VERSION "HNNBNNNYNNNNNNNNNNNNNNNNNNNNNNNNNNNNNNNNNN/4/%%%/4/'%**4NNN///"

NS_ :

BS_ :

BU_:  Airbag BAP_Tester ICAS1_Gateway ICAS1_KommunikationsServer LE1 LE2 Motor_BEV Schaltbetaetigung

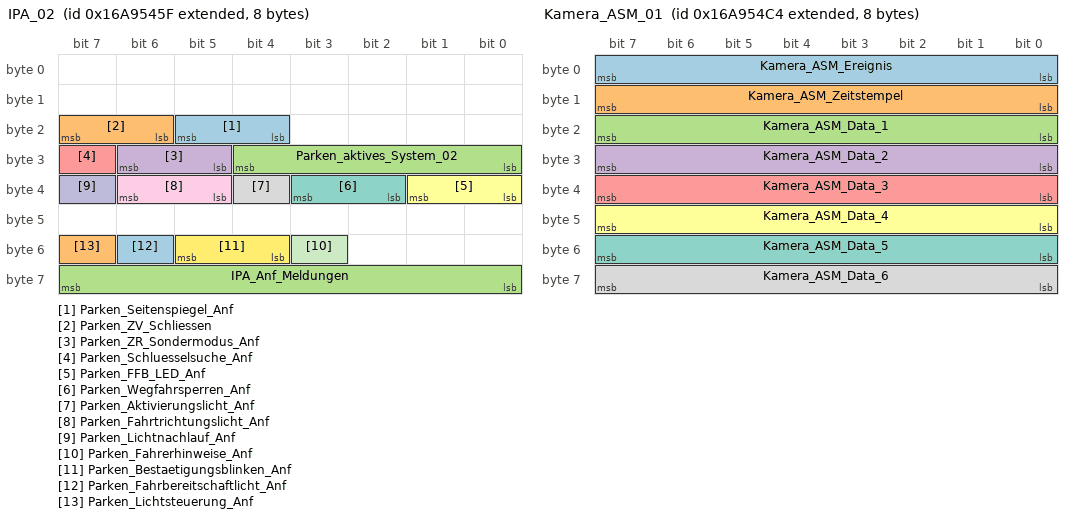
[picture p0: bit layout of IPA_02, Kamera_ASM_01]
BO_ 2527679583 IPA_02: 8 ICAS1_Gateway
 SG_ Parken_Seitenspiegel_Anf  : 20|2@1+ (1.000000,0.000000) [0.000000|3.000000] "" Vector__XXX
 SG_ Parken_ZV_Schliessen  : 22|2@1+ (1.000000,0.000000) [0.000000|3.000000] "" Vector__XXX
 SG_ Parken_aktives_System_02  : 24|5@1+ (1.000000,0.000000) [0.000000|31.000000] "" Vector__XXX
 SG_ Parken_ZR_Sondermodus_Anf  : 29|2@1+ (1.000000,0.000000) [0.000000|3.000000] "" Vector__XXX
 SG_ Parken_Schluesselsuche_Anf  : 31|1@1+ (1.000000,0.000000) [0.000000|1.000000] "" Vector__XXX
 SG_ Parken_FFB_LED_Anf  : 32|2@1+ (1.000000,0.000000) [0.000000|3.000000] "" Vector__XXX
 SG_ Parken_Wegfahrsperren_Anf  : 34|2@1+ (1.000000,0.000000) [0.000000|3.000000] "" LE1 LE2
 SG_ Parken_Aktivierungslicht_Anf  : 36|1@1+ (1.000000,0.000000) [0.000000|1.000000] "" Vector__XXX
 SG_ Parken_Fahrtrichtungslicht_Anf  : 37|2@1+ (1.000000,0.000000) [0.000000|3.000000] "" Vector__XXX
 SG_ Parken_Lichtnachlauf_Anf  : 39|1@1+ (1.000000,0.000000) [0.000000|1.000000] "" Vector__XXX
 SG_ Parken_Fahrerhinweise_Anf  : 51|1@1+ (1.000000,0.000000) [0.000000|1.000000] "" Vector__XXX
 SG_ Parken_Bestaetigungsblinken_Anf  : 52|2@1+ (1.000000,0.000000) [0.000000|3.000000] "" Vector__XXX
 SG_ Parken_Fahrbereitschaftlicht_Anf  : 54|1@1+ (1.000000,0.000000) [0.000000|1.000000] "" Vector__XXX
 SG_ Parken_Lichtsteuerung_Anf  : 55|1@1+ (1.000000,0.000000) [0.000000|1.000000] "" Vector__XXX
 SG_ IPA_Anf_Meldungen  : 56|8@1+ (1.000000,0.000000) [0.000000|255.000000] "" Vector__XXX

BO_ 1813 ISO_Airbag_01_Req: 8 ICAS1_Gateway
 SG_ ISO_Airbag_01_Req_Data  : 0|64@1+ (1.000000,0.000000) [0.000000|18446744073709551616.000000] "" Airbag

BO_ 1919 ISO_Airbag_01_Resp: 8 Airbag
 SG_ ISO_Airbag_01_Resp_Data  : 0|64@1+ (1.000000,0.000000) [0.000000|18446744073709551616.000000] "" ICAS1_Gateway

BO_ 1792 ISO_Funktionaler_Req_All: 8 ICAS1_Gateway
 SG_ ISO_ALL_01_Req_Data  : 0|64@1+ (1.000000,0.000000) [0.000000|18446744073709551616.000000] "" Airbag LE1 LE2 Motor_BEV

BO_ 2621440021 ISOx_Airbag_01_Req_FD: 64 ICAS1_Gateway
 SG_ ISOx_Airbag_01_Req_FD_Data  : 0|512@1+ (1.000000,0.000000) [0.000000|13407807929942597099574024998205846127479365820592393377723561443721764030073546976801874298166903427690031858186486050853753882811946569946433649006084096.000000] "" Airbag

BO_ 2621571093 ISOx_Airbag_01_Resp_FD: 64 Airbag
 SG_ ISOx_Airbag_01_Resp_FD_Data  : 0|512@1+ (1.000000,0.000000) [0.000000|13407807929942597099574024998205846127479365820592393377723561443721764030073546976801874298166903427690031858186486050853753882811946569946433649006084096.000000] "" ICAS1_Gateway

BO_ 2549874812 ISOx_EMotor_01_Req: 8 ICAS1_Gateway
 SG_ ISO_EMotor_01_Req_Data  : 0|64@1+ (1.000000,0.000000) [0.000000|18446744073709551616.000000] "" LE1

BO_ 2621440124 ISOx_EMotor_01_Req_FD: 64 ICAS1_Gateway
 SG_ ISOx_EMotor_01_Req_FD_Data  : 0|512@1+ (1.000000,0.000000) [0.000000|13407807929942597099574024998205846127479365820592393377723561443721764030073546976801874298166903427690031858186486050853753882811946569946433649006084096.000000] "" LE1

BO_ 2550005884 ISOx_EMotor_01_Resp: 8 LE1
 SG_ ISO_EMotor_01_Resp_Data  : 0|64@1+ (1.000000,0.000000) [0.000000|18446744073709551616.000000] "" ICAS1_Gateway

BO_ 2621571196 ISOx_EMotor_01_Resp_FD: 64 LE1
 SG_ ISOx_EMotor_01_Resp_FD_Data  : 0|512@1+ (1.000000,0.000000) [0.000000|13407807929942597099574024998205846127479365820592393377723561443721764030073546976801874298166903427690031858186486050853753882811946569946433649006084096.000000] "" ICAS1_Gateway

BO_ 2549874872 ISOx_EMotor_02_Req: 8 ICAS1_Gateway
 SG_ ISO_EMotor_02_Req_Data  : 0|64@1+ (1.000000,0.000000) [0.000000|18446744073709551616.000000] "" LE2

BO_ 2621440184 ISOx_EMotor_02_Req_FD: 64 ICAS1_Gateway
 SG_ ISOx_EMotor_02_Req_FD_Data  : 0|512@1+ (1.000000,0.000000) [0.000000|13407807929942597099574024998205846127479365820592393377723561443721764030073546976801874298166903427690031858186486050853753882811946569946433649006084096.000000] "" LE2

BO_ 2550005944 ISOx_EMotor_02_Resp: 8 LE2
 SG_ ISO_EMotor_02_Resp_Data  : 0|64@1+ (1.000000,0.000000) [0.000000|18446744073709551616.000000] "" ICAS1_Gateway

BO_ 2621571256 ISOx_EMotor_02_Resp_FD: 64 LE2
 SG_ ISOx_EMotor_02_Resp_FD_Data  : 0|512@1+ (1.000000,0.000000) [0.000000|13407807929942597099574024998205846127479365820592393377723561443721764030073546976801874298166903427690031858186486050853753882811946569946433649006084096.000000] "" ICAS1_Gateway

BO_ 2621505536 ISOx_Funkt_Req_All_FD: 64 ICAS1_Gateway
 SG_ ISOx_Funkt_Req_All_FD_Data  : 0|512@1+ (1.000000,0.000000) [0.000000|13407807929942597099574024998205846127479365820592393377723561443721764030073546976801874298166903427690031858186486050853753882811946569946433649006084096.000000] "" Airbag LE1 LE2 Motor_BEV

BO_ 2549874806 ISOx_MO_01_Req: 8 ICAS1_Gateway
 SG_ ISOx_MO_01_Req_Data  : 0|64@1+ (1.000000,0.000000) [0.000000|18446744073709551616.000000] "" Motor_BEV

BO_ 2621440118 ISOx_MO_01_Req_FD: 64 ICAS1_Gateway
 SG_ ISOx_MO_01_Req_FD_Data  : 0|512@1+ (1.000000,0.000000) [0.000000|13407807929942597099574024998205846127479365820592393377723561443721764030073546976801874298166903427690031858186486050853753882811946569946433649006084096.000000] "" Motor_BEV

BO_ 2550005878 ISOx_MO_01_Resp: 8 Motor_BEV
 SG_ ISOx_MO_01_Resp_Data  : 0|64@1+ (1.000000,0.000000) [0.000000|18446744073709551616.000000] "" ICAS1_Gateway

BO_ 2621571190 ISOx_MO_01_Resp_FD: 64 Motor_BEV
 SG_ ISOx_MO_01_Resp_FD_Data  : 0|512@1+ (1.000000,0.000000) [0.000000|13407807929942597099574024998205846127479365820592393377723561443721764030073546976801874298166903427690031858186486050853753882811946569946433649006084096.000000] "" ICAS1_Gateway

BO_ 2527679684 Kamera_ASM_01: 8 ICAS1_Gateway
 SG_ Kamera_ASM_Ereignis  : 0|8@1+ (1.000000,0.000000) [1.000000|254.000000] "" Airbag
 SG_ Kamera_ASM_Zeitstempel  : 8|8@1+ (0.080000,0.000000) [0.000000|20.320000] "Unit_Secon" Airbag
 SG_ Kamera_ASM_Data_1  : 16|8@1+ (1.000000,0.000000) [0.000000|255.000000] "" Airbag
 SG_ Kamera_ASM_Data_2  : 24|8@1+ (1.000000,0.000000) [0.000000|255.000000] "" Airbag
 SG_ Kamera_ASM_Data_3  : 32|8@1+ (1.000000,0.000000) [0.000000|255.000000] "" Airbag
 SG_ Kamera_ASM_Data_4  : 40|8@1+ (1.000000,0.000000) [0.000000|255.000000] "" Airbag
 SG_ Kamera_ASM_Data_5  : 48|8@1+ (1.000000,0.000000) [0.000000|255.000000] "" Airbag
 SG_ Kamera_ASM_Data_6  : 56|8@1+ (1.000000,0.000000) [0.000000|255.000000] "" Airbag

BO_ 960 Klemmen_Status_01: 4 ICAS1_Gateway
 SG_ Klemmen_Status_01_CRC  : 0|8@1+ (1.000000,0.000000) [0.000000|255.000000] "" Motor_BEV
 SG_ Klemmen_Status_01_BZ  : 8|4@1+ (1.000000,0.000000) [0.000000|15.000000] "" Motor_BEV
 SG_ RSt_Fahrerhinweise  : 12|4@1+ (1.000000,0.000000) [0.000000|15.000000] "" Vector__XXX
 SG_ ZAS_Kl_S  : 16|1@1+ (1.000000,0.000000) [0.000000|1.000000] "" Vector__XXX
 SG_ ZAS_Kl_15  : 17|1@1+ (1.000000,0.000000) [0.000000|1.000000] "" Airbag LE1 LE2 Motor_BEV Schaltbetaetigung
 SG_ ZAS_Kl_X  : 18|1@1+ (1.000000,0.000000) [0.000000|1.000000] "" Vector__XXX
 SG_ ZAS_Kl_50_Startanforderung  : 19|1@1+ (1.000000,0.000000) [0.000000|1.000000] "" Motor_BEV
 SG_ BCM_Remotestart_Betrieb  : 20|1@1+ (1.000000,0.000000) [0.000000|1.000000] "" Vector__XXX
 SG_ ZAS_Kl_Infotainment  : 21|1@1+ (1.000000,0.000000) [0.000000|1.000000] "" Vector__XXX
 SG_ BCM_Remotestart_KL15_Anf  : 22|1@1+ (1.000000,0.000000) [0.000000|1.000000] "" Vector__XXX
 SG_ BCM_Remotestart_MO_Start  : 23|1@1+ (1.000000,0.000000) [0.000000|1.000000] "" Vector__XXX
 SG_ KST_Warn_P1_ZST_def  : 24|1@1+ (1.000000,0.000000) [0.000000|1.000000] "" Vector__XXX
 SG_ KST_Warn_P2_ZST_def  : 25|1@1+ (1.000000,0.000000) [0.000000|1.000000] "" Vector__XXX
 SG_ KST_Fahrerhinweis_1  : 26|1@1+ (1.000000,0.000000) [0.000000|1.000000] "" Vector__XXX
 SG_ KST_Fahrerhinweis_2  : 27|1@1+ (1.000000,0.000000) [0.000000|1.000000] "" Vector__XXX
 SG_ BCM_Ausparken_Betrieb  : 28|1@1+ (1.000000,0.000000) [0.000000|1.000000] "" Vector__XXX
 SG_ KST_Fahrerhinweis_4  : 29|1@1+ (1.000000,0.000000) [0.000000|1.000000] "" Vector__XXX
 SG_ KST_Fahrerhinweis_5  : 30|1@1+ (1.000000,0.000000) [0.000000|1.000000] "" Vector__XXX
 SG_ KST_Fahrerhinweis_6  : 31|1@1+ (1.000000,0.000000) [0.000000|1.000000] "" Vector__XXX

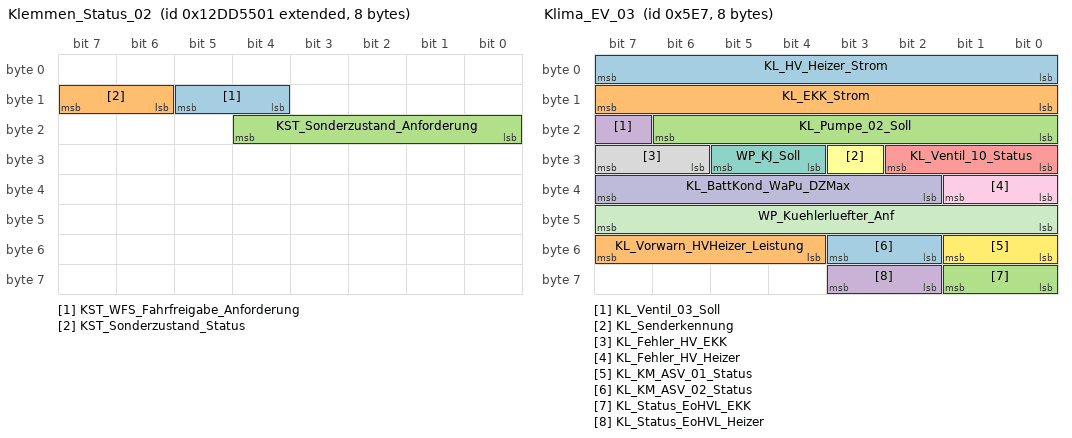
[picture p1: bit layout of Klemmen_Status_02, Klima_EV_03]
BO_ 2463978753 Klemmen_Status_02: 8 ICAS1_Gateway
 SG_ KST_WFS_Fahrfreigabe_Anforderung  : 12|2@1+ (1.000000,0.000000) [0.000000|3.000000] "" LE1 LE2
 SG_ KST_Sonderzustand_Status  : 14|2@1+ (1.000000,0.000000) [0.000000|3.000000] "" LE1 LE2
 SG_ KST_Sonderzustand_Anforderung  : 16|5@1+ (1.000000,0.000000) [0.000000|31.000000] "" LE1 LE2

BO_ 1420 Klemmen_Steuerung_01: 8 ICAS1_Gateway
 SG_ Klemmen_Steuerung_01_CRC  : 0|8@1+ (1.000000,0.000000) [0.000000|255.000000] "" Vector__XXX
 SG_ Klemmen_Steuerung_01_BZ  : 8|4@1+ (1.000000,0.000000) [0.000000|15.000000] "" Vector__XXX
 SG_ KST_Anf_Klemme_15  : 12|1@1+ (1.000000,0.000000) [0.000000|1.000000] "" Vector__XXX
 SG_ KST_Anf_Klemme_50  : 13|1@1+ (1.000000,0.000000) [0.000000|1.000000] "" Motor_BEV
 SG_ KST_Anf_Klemme_S  : 14|1@1+ (1.000000,0.000000) [0.000000|1.000000] "" Vector__XXX
 SG_ KST_Txt_Werkstatt  : 15|1@1+ (1.000000,0.000000) [0.000000|1.000000] "" Vector__XXX
 SG_ KST_Txt_P_Gang  : 16|1@1+ (1.000000,0.000000) [0.000000|1.000000] "" Vector__XXX
 SG_ KST_Txt_Panikabschaltung  : 17|1@1+ (1.000000,0.000000) [0.000000|1.000000] "" Vector__XXX
 SG_ KST_Anf_Klemmenfreigabe_ELV  : 18|1@1+ (1.000000,0.000000) [0.000000|1.000000] "" Vector__XXX
 SG_ KST_Txt_Komfortabschaltung  : 19|1@1+ (1.000000,0.000000) [0.000000|1.000000] "" Vector__XXX
 SG_ KST_ZAT_betaetigt  : 20|1@1+ (1.000000,0.000000) [0.000000|1.000000] "" Vector__XXX
 SG_ KST_Unterdr_Zuendungsmeldung  : 21|1@1+ (1.000000,0.000000) [0.000000|1.000000] "" Vector__XXX
 SG_ KST_aut_Abschaltung_Zuendung  : 22|1@1+ (1.000000,0.000000) [0.000000|1.000000] "" Vector__XXX
 SG_ KST_Anf_Klemmenfreigabe_WFS  : 23|1@1+ (1.000000,0.000000) [0.000000|1.000000] "" Vector__XXX
 SG_ KST_Anf_ZV_Verriegelung  : 24|1@1+ (1.000000,0.000000) [0.000000|1.000000] "" Vector__XXX
 SG_ Relais_VoKo_angesteuert  : 25|1@1+ (1.000000,0.000000) [0.000000|1.000000] "" Vector__XXX
 SG_ RSt_Anforderung_HMS  : 26|3@1+ (1.000000,0.000000) [0.000000|7.000000] "" Vector__XXX
 SG_ KST_Zuendungswarnung  : 29|2@1+ (1.000000,0.000000) [0.000000|3.000000] "" Vector__XXX
 SG_ KST_Fahrer_Info_Text  : 31|3@1+ (1.000000,0.000000) [0.000000|7.000000] "" Vector__XXX

BO_ 949 Klima_11: 8 ICAS1_Gateway
 SG_ KL_Drehz_Anh  : 0|1@1+ (1.000000,0.000000) [0.000000|1.000000] "" Vector__XXX
 SG_ KL_Vorwarn_Komp_ein  : 1|1@1+ (1.000000,0.000000) [0.000000|1.000000] "" Vector__XXX
 SG_ KL_AC_Schalter  : 2|1@1+ (1.000000,0.000000) [0.000000|1.000000] "" Vector__XXX
 SG_ KL_Komp_Moment_alt  : 3|1@1+ (1.000000,0.000000) [0.000000|1.000000] "" Vector__XXX
 SG_ KL_Vorwarn_Zuheizer_ein  : 6|1@1+ (1.000000,0.000000) [0.000000|1.000000] "" Vector__XXX
 SG_ KL_Zustand  : 7|1@1+ (1.000000,0.000000) [0.000000|1.000000] "" Vector__XXX
 SG_ KL_Kompressorkupplung_linear  : 8|8@1+ (20.000000,0.000000) [0.000000|4000.000000] "Unit_MilliAmper" Vector__XXX
 SG_ KL_Charisma_FahrPr  : 16|4@1+ (1.000000,0.000000) [0.000000|15.000000] "" Vector__XXX
 SG_ KL_Charisma_Status  : 20|2@1+ (1.000000,0.000000) [0.000000|3.000000] "" Vector__XXX
 SG_ KL_nachtr_Stopp_Anf  : 22|1@1+ (1.000000,0.000000) [0.000000|1.000000] "" Vector__XXX
 SG_ KL_T_Charge  : 23|1@1+ (1.000000,0.000000) [0.000000|1.000000] "" Vector__XXX
 SG_ KL_Last_Kompr  : 24|8@1+ (0.250000,0.000000) [0.000000|63.500000] "Unit_NewtoMeter" Vector__XXX
 SG_ KL_Spannungs_Anf  : 32|2@1+ (1.000000,0.000000) [0.000000|3.000000] "" Vector__XXX
 SG_ KL_Thermomanagement  : 34|2@1+ (1.000000,0.000000) [0.000000|3.000000] "" Motor_BEV
 SG_ KL_StartStopp_Info  : 36|2@1+ (1.000000,0.000000) [0.000000|3.000000] "" Vector__XXX
 SG_ KL_Freilauf_Info  : 38|2@1+ (1.000000,0.000000) [0.000000|3.000000] "" Vector__XXX
 SG_ KL_Anf_KL  : 40|8@1+ (0.400000,0.000000) [0.000000|101.600000] "Unit_PerCent" Motor_BEV
 SG_ KL_el_Zuheizer_Stufe  : 48|3@1+ (1.000000,0.000000) [0.000000|7.000000] "" Vector__XXX
 SG_ KL_Ausstattung_Klima  : 51|3@1+ (1.000000,0.000000) [0.000000|7.000000] "" Vector__XXX
 SG_ KL_Variante_Standheizung  : 54|2@1+ (1.000000,0.000000) [0.000000|3.000000] "" Vector__XXX
 SG_ KL_Anf_KV  : 57|7@1+ (1.000000,0.000000) [0.000000|100.000000] "Unit_PerCent" Motor_BEV

BO_ 1511 Klima_EV_03: 8 ICAS1_Gateway
 SG_ KL_HV_Heizer_Strom  : 0|8@1+ (0.250000,0.000000) [0.000000|63.500000] "Unit_Amper" Motor_BEV
 SG_ KL_EKK_Strom  : 8|8@1+ (0.250000,0.000000) [0.000000|63.500000] "Unit_Amper" Motor_BEV
 SG_ KL_Pumpe_02_Soll  : 16|7@1+ (1.000000,0.000000) [0.000000|100.000000] "Unit_PerCent" Motor_BEV
 SG_ KL_Ventil_03_Soll  : 23|1@1+ (1.000000,0.000000) [0.000000|1.000000] "" Vector__XXX
 SG_ KL_Ventil_10_Status  : 24|3@1+ (1.000000,0.000000) [0.000000|7.000000] "" Vector__XXX
 SG_ KL_Senderkennung  : 27|1@1+ (1.000000,0.000000) [0.000000|1.000000] "" Vector__XXX
 SG_ WP_KJ_Soll  : 28|2@1+ (1.000000,0.000000) [0.000000|3.000000] "" Vector__XXX
 SG_ KL_Fehler_HV_EKK  : 30|2@1+ (1.000000,0.000000) [0.000000|3.000000] "" Vector__XXX
 SG_ KL_Fehler_HV_Heizer  : 32|2@1+ (1.000000,0.000000) [0.000000|3.000000] "" Vector__XXX
 SG_ KL_BattKond_WaPu_DZMax  : 34|6@1+ (2.000000,0.000000) [0.000000|100.000000] "Unit_PerCent" Vector__XXX
 SG_ WP_Kuehlerluefter_Anf  : 40|8@1+ (0.400000,0.000000) [0.000000|101.600000] "Unit_PerCent" Vector__XXX
 SG_ KL_KM_ASV_01_Status  : 48|2@1+ (1.000000,0.000000) [0.000000|3.000000] "" Vector__XXX
 SG_ KL_KM_ASV_02_Status  : 50|2@1+ (1.000000,0.000000) [0.000000|3.000000] "" Vector__XXX
 SG_ KL_Vorwarn_HVHeizer_Leistung  : 52|4@1+ (1.000000,0.000000) [0.000000|15.000000] "" Vector__XXX
 SG_ KL_Status_EoHVL_EKK  : 56|2@1+ (1.000000,0.000000) [0.000000|3.000000] "" Motor_BEV
 SG_ KL_Status_EoHVL_Heizer  : 58|2@1+ (1.000000,0.000000) [0.000000|3.000000] "" Motor_BEV

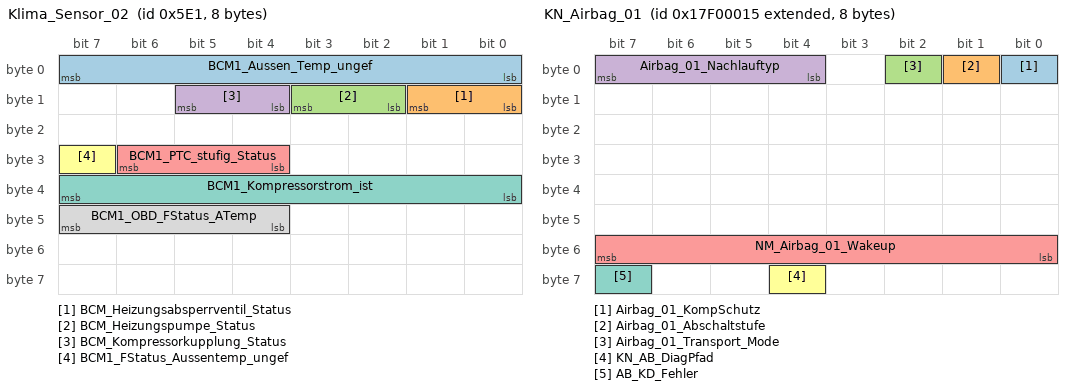
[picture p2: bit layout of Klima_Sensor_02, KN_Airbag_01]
BO_ 1505 Klima_Sensor_02: 8 ICAS1_Gateway
 SG_ BCM1_Aussen_Temp_ungef  : 0|8@1+ (0.500000,-50.000000) [-50.000000|76.000000] "Unit_DegreCelsi" LE1 LE2 Motor_BEV
 SG_ BCM_Heizungsabsperrventil_Status  : 8|2@1+ (1.000000,0.000000) [0.000000|3.000000] "" Vector__XXX
 SG_ BCM_Heizungspumpe_Status  : 10|2@1+ (1.000000,0.000000) [0.000000|3.000000] "" Vector__XXX
 SG_ BCM_Kompressorkupplung_Status  : 12|2@1+ (1.000000,0.000000) [0.000000|3.000000] "" Vector__XXX
 SG_ BCM1_PTC_stufig_Status  : 28|3@1+ (1.000000,0.000000) [0.000000|7.000000] "" Vector__XXX
 SG_ BCM1_FStatus_Aussentemp_ungef  : 31|1@1+ (1.000000,0.000000) [0.000000|1.000000] "" Vector__XXX
 SG_ BCM1_Kompressorstrom_ist  : 32|8@1+ (4.000000,0.000000) [0.000000|1000.000000] "Unit_MilliAmper" Vector__XXX
 SG_ BCM1_OBD_FStatus_ATemp  : 44|4@1+ (1.000000,0.000000) [0.000000|15.000000] "" Vector__XXX

BO_ 2549088277 KN_Airbag_01: 8 Airbag
 SG_ Airbag_01_KompSchutz  : 0|1@1+ (1.000000,0.000000) [0.000000|1.000000] "" Vector__XXX
 SG_ Airbag_01_Abschaltstufe  : 1|1@1+ (1.000000,0.000000) [0.000000|1.000000] "" Vector__XXX
 SG_ Airbag_01_Transport_Mode  : 2|1@1+ (1.000000,0.000000) [0.000000|1.000000] "" Vector__XXX
 SG_ Airbag_01_Nachlauftyp  : 4|4@1+ (1.000000,0.000000) [0.000000|15.000000] "" ICAS1_Gateway
 SG_ NM_Airbag_01_Wakeup  : 48|8@1+ (1.000000,0.000000) [0.000000|255.000000] "" Vector__XXX
 SG_ KN_AB_DiagPfad  : 60|1@1+ (1.000000,0.000000) [0.000000|1.000000] "" ICAS1_Gateway
 SG_ AB_KD_Fehler  : 63|1@1+ (1.000000,0.000000) [0.000000|1.000000] "" ICAS1_Gateway

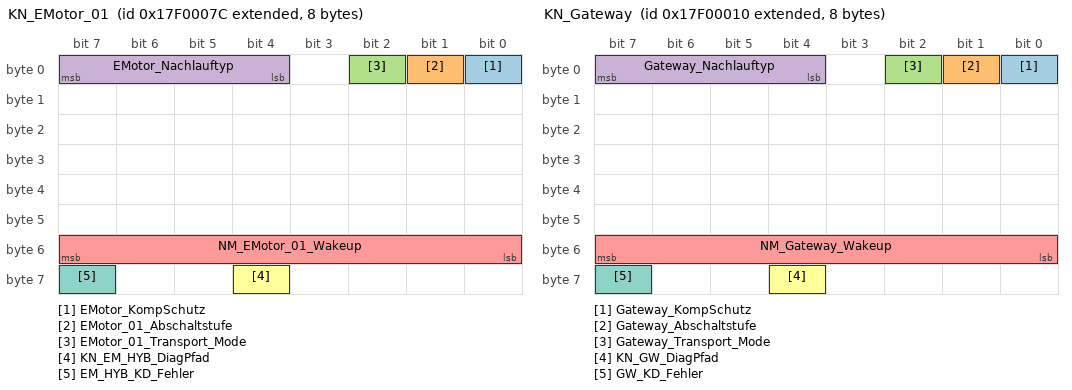
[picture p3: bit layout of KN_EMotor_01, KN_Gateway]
BO_ 2549088380 KN_EMotor_01: 8 LE1
 SG_ EMotor_KompSchutz  : 0|1@1+ (1.000000,0.000000) [0.000000|1.000000] "" Vector__XXX
 SG_ EMotor_01_Abschaltstufe  : 1|1@1+ (1.000000,0.000000) [0.000000|1.000000] "" Vector__XXX
 SG_ EMotor_01_Transport_Mode  : 2|1@1+ (1.000000,0.000000) [0.000000|1.000000] "" Vector__XXX
 SG_ EMotor_Nachlauftyp  : 4|4@1+ (1.000000,0.000000) [0.000000|15.000000] "" ICAS1_Gateway
 SG_ NM_EMotor_01_Wakeup  : 48|8@1+ (1.000000,0.000000) [0.000000|255.000000] "" Vector__XXX
 SG_ KN_EM_HYB_DiagPfad  : 60|1@1+ (1.000000,0.000000) [0.000000|1.000000] "" ICAS1_Gateway
 SG_ EM_HYB_KD_Fehler  : 63|1@1+ (1.000000,0.000000) [0.000000|1.000000] "" ICAS1_Gateway

BO_ 2549088272 KN_Gateway: 8 ICAS1_Gateway
 SG_ Gateway_KompSchutz  : 0|1@1+ (1.000000,0.000000) [0.000000|1.000000] "" Vector__XXX
 SG_ Gateway_Abschaltstufe  : 1|1@1+ (1.000000,0.000000) [0.000000|1.000000] "" Vector__XXX
 SG_ Gateway_Transport_Mode  : 2|1@1+ (1.000000,0.000000) [0.000000|1.000000] "" Vector__XXX
 SG_ Gateway_Nachlauftyp  : 4|4@1+ (1.000000,0.000000) [0.000000|15.000000] "" Vector__XXX
 SG_ NM_Gateway_Wakeup  : 48|8@1+ (1.000000,0.000000) [0.000000|255.000000] "" Vector__XXX
 SG_ KN_GW_DiagPfad  : 60|1@1+ (1.000000,0.000000) [0.000000|1.000000] "" Vector__XXX
 SG_ GW_KD_Fehler  : 63|1@1+ (1.000000,0.000000) [0.000000|1.000000] "" Vector__XXX

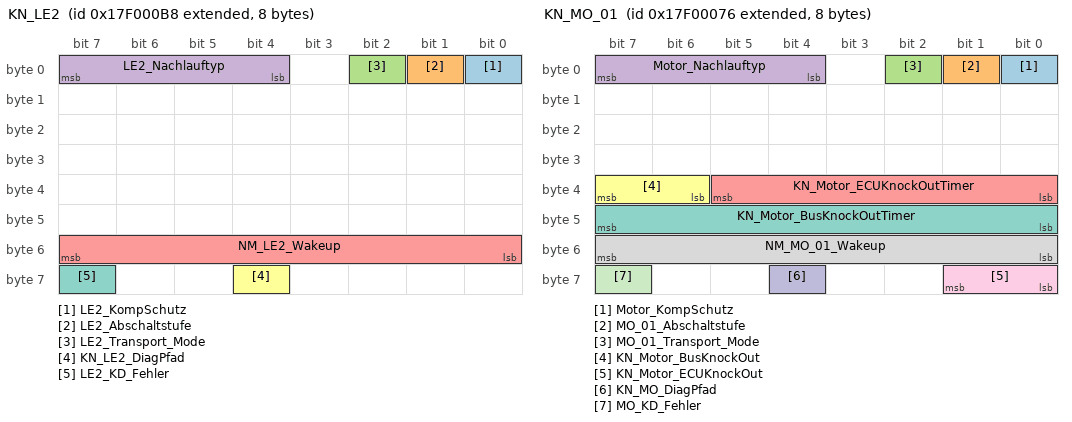
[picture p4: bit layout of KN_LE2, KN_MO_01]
BO_ 2549088440 KN_LE2: 8 LE2
 SG_ LE2_KompSchutz  : 0|1@1+ (1.000000,0.000000) [0.000000|1.000000] "" Vector__XXX
 SG_ LE2_Abschaltstufe  : 1|1@1+ (1.000000,0.000000) [0.000000|1.000000] "" Vector__XXX
 SG_ LE2_Transport_Mode  : 2|1@1+ (1.000000,0.000000) [0.000000|1.000000] "" Vector__XXX
 SG_ LE2_Nachlauftyp  : 4|4@1+ (1.000000,0.000000) [0.000000|15.000000] "" ICAS1_Gateway
 SG_ NM_LE2_Wakeup  : 48|8@1+ (1.000000,0.000000) [0.000000|255.000000] "" Vector__XXX
 SG_ KN_LE2_DiagPfad  : 60|1@1+ (1.000000,0.000000) [0.000000|1.000000] "" ICAS1_Gateway
 SG_ LE2_KD_Fehler  : 63|1@1+ (1.000000,0.000000) [0.000000|1.000000] "" ICAS1_Gateway

BO_ 2549088374 KN_MO_01: 8 Motor_BEV
 SG_ Motor_KompSchutz  : 0|1@1+ (1.000000,0.000000) [0.000000|1.000000] "" Vector__XXX
 SG_ MO_01_Abschaltstufe  : 1|1@1+ (1.000000,0.000000) [0.000000|1.000000] "" Vector__XXX
 SG_ MO_01_Transport_Mode  : 2|1@1+ (1.000000,0.000000) [0.000000|1.000000] "" Vector__XXX
 SG_ Motor_Nachlauftyp  : 4|4@1+ (1.000000,0.000000) [0.000000|15.000000] "" ICAS1_Gateway
 SG_ KN_Motor_ECUKnockOutTimer  : 32|6@1+ (1.000000,0.000000) [0.000000|62.000000] "Unit_Minut" Vector__XXX
 SG_ KN_Motor_BusKnockOut  : 38|2@1+ (1.000000,0.000000) [0.000000|3.000000] "" Vector__XXX
 SG_ KN_Motor_BusKnockOutTimer  : 40|8@1+ (1.000000,0.000000) [0.000000|254.000000] "" Vector__XXX
 SG_ NM_MO_01_Wakeup  : 48|8@1+ (1.000000,0.000000) [0.000000|255.000000] "" Vector__XXX
 SG_ KN_Motor_ECUKnockOut  : 56|2@1+ (1.000000,0.000000) [0.000000|3.000000] "" Vector__XXX
 SG_ KN_MO_DiagPfad  : 60|1@1+ (1.000000,0.000000) [0.000000|1.000000] "" ICAS1_Gateway
 SG_ MO_KD_Fehler  : 63|1@1+ (1.000000,0.000000) [0.000000|1.000000] "" ICAS1_Gateway

BO_ 2621440277 KS_Airbag_01_Req_FD: 16 ICAS1_Gateway
 SG_ KS_Airbag_01_Req_FD_Data  : 0|128@1+ (1.000000,0.000000) [0.000000|340282366920938463463374607431768211456.000000] "" Airbag

BO_ 2621571349 KS_Airbag_01_Resp_FD: 16 Airbag
 SG_ KS_Airbag_01_Resp_FD_Data  : 0|128@1+ (1.000000,0.000000) [0.000000|340282366920938463463374607431768211456.000000] "" ICAS1_Gateway

BO_ 982 Licht_hinten_01: 8 ICAS1_Gateway
 SG_ Licht_hinten_01_BZ  : 0|4@1+ (1.000000,0.000000) [0.000000|15.000000] "" Vector__XXX
 SG_ LH_Aussenlicht_def  : 7|1@1+ (1.000000,0.000000) [0.000000|1.000000] "" Vector__XXX
 SG_ LH_Standlicht_H_aktiv  : 8|1@1+ (1.000000,0.000000) [0.000000|1.000000] "" Vector__XXX
 SG_ LH_Parklicht_HL_aktiv  : 9|1@1+ (1.000000,0.000000) [0.000000|1.000000] "" Vector__XXX
 SG_ LH_Parklicht_HR_aktiv  : 10|1@1+ (1.000000,0.000000) [0.000000|1.000000] "" Vector__XXX
 SG_ LH_Bremslicht_H_aktiv  : 11|1@1+ (1.000000,0.000000) [0.000000|1.000000] "" Vector__XXX
 SG_ LH_Nebelschluss_aktiv  : 12|1@1+ (1.000000,0.000000) [0.000000|1.000000] "" Vector__XXX
 SG_ LH_Rueckfahrlicht_aktiv  : 13|1@1+ (1.000000,0.000000) [0.000000|1.000000] "" Vector__XXX
 SG_ LH_Blinker_HL_akt  : 14|1@1+ (1.000000,0.000000) [0.000000|1.000000] "" Vector__XXX
 SG_ LH_Blinker_HR_akt  : 15|1@1+ (1.000000,0.000000) [0.000000|1.000000] "" Vector__XXX
 SG_ LH_Blinker_li_def  : 16|1@1+ (1.000000,0.000000) [0.000000|1.000000] "" Vector__XXX
 SG_ LH_Bremsl_li_def  : 17|1@1+ (1.000000,0.000000) [0.000000|1.000000] "" Vector__XXX
 SG_ LH_Schlusslicht_li_def  : 18|1@1+ (1.000000,0.000000) [0.000000|1.000000] "" Vector__XXX
 SG_ LH_Rueckf_li_def  : 19|1@1+ (1.000000,0.000000) [0.000000|1.000000] "" Vector__XXX
 SG_ LH_Nebel_li_def  : 20|1@1+ (1.000000,0.000000) [0.000000|1.000000] "" Vector__XXX
 SG_ LH_Schluss_Brems_Nebel_li_def  : 21|1@1+ (1.000000,0.000000) [0.000000|1.000000] "" Vector__XXX
 SG_ LH_Schluss_Brems_Nebel_re_def  : 22|1@1+ (1.000000,0.000000) [0.000000|1.000000] "" Vector__XXX
 SG_ LH_Zusatzschlussl_def  : 23|1@1+ (1.000000,0.000000) [0.000000|1.000000] "" Vector__XXX
 SG_ LH_Schluss_Brems_li_def  : 24|1@1+ (1.000000,0.000000) [0.000000|1.000000] "" Vector__XXX
 SG_ LH_Schluss_Nebel_li_def  : 25|1@1+ (1.000000,0.000000) [0.000000|1.000000] "" Vector__XXX
 SG_ LH_SL_BRL_BLK_li_def  : 26|1@1+ (1.000000,0.000000) [0.000000|1.000000] "" Vector__XXX
 SG_ LH_Brems_Blk_li_def  : 27|1@1+ (1.000000,0.000000) [0.000000|1.000000] "" Vector__XXX
 SG_ LH_Diag_Status_re_def  : 28|1@1+ (1.000000,0.000000) [0.000000|1.000000] "" Vector__XXX
 SG_ LH_Diag_Status_li_def  : 29|1@1+ (1.000000,0.000000) [0.000000|1.000000] "" Vector__XXX
 SG_ LH_Diag_LED_li_def  : 30|1@1+ (1.000000,0.000000) [0.000000|1.000000] "" Vector__XXX
 SG_ LH_Diag_LED_re_def  : 31|1@1+ (1.000000,0.000000) [0.000000|1.000000] "" Vector__XXX
 SG_ LH_Blinker_re_def  : 32|1@1+ (1.000000,0.000000) [0.000000|1.000000] "" Vector__XXX
 SG_ LH_Bremsl_re_def  : 33|1@1+ (1.000000,0.000000) [0.000000|1.000000] "" Vector__XXX
 SG_ LH_Schlusslicht_re_def  : 34|1@1+ (1.000000,0.000000) [0.000000|1.000000] "" Vector__XXX
 SG_ LH_Rueckf_re_def  : 35|1@1+ (1.000000,0.000000) [0.000000|1.000000] "" Vector__XXX
 SG_ LH_Nebel_re_def  : 36|1@1+ (1.000000,0.000000) [0.000000|1.000000] "" Vector__XXX
 SG_ LH_Schluss_Brems_mi_def  : 37|1@1+ (1.000000,0.000000) [0.000000|1.000000] "" Vector__XXX
 SG_ LH_Schluss_Brems_re_def  : 40|1@1+ (1.000000,0.000000) [0.000000|1.000000] "" Vector__XXX
 SG_ LH_Schluss_Nebel_re_def  : 41|1@1+ (1.000000,0.000000) [0.000000|1.000000] "" Vector__XXX
 SG_ LH_SL_BRL_BLK_re_def  : 42|1@1+ (1.000000,0.000000) [0.000000|1.000000] "" Vector__XXX
 SG_ LH_Brems_Blk_re_def  : 43|1@1+ (1.000000,0.000000) [0.000000|1.000000] "" Vector__XXX
 SG_ LH_Kennzl_def  : 48|1@1+ (1.000000,0.000000) [0.000000|1.000000] "" Vector__XXX
 SG_ LH_3_Bremsl_def  : 49|1@1+ (1.000000,0.000000) [0.000000|1.000000] "" Motor_BEV
 SG_ LH_Nebel_mi_def  : 50|1@1+ (1.000000,0.000000) [0.000000|1.000000] "" Vector__XXX
 SG_ LH_Rueckf_mi_def  : 51|1@1+ (1.000000,0.000000) [0.000000|1.000000] "" Vector__XXX
 SG_ LH_Schlusslicht_mi_def  : 52|1@1+ (1.000000,0.000000) [0.000000|1.000000] "" Vector__XXX
 SG_ LH_Bremsl_li_ges_def  : 54|1@1+ (1.000000,0.000000) [0.000000|1.000000] "" Motor_BEV
 SG_ LH_Bremsl_re_ges_def  : 55|1@1+ (1.000000,0.000000) [0.000000|1.000000] "" Motor_BEV
 SG_ LH_Bremsl_mi_def  : 61|1@1+ (1.000000,0.000000) [0.000000|1.000000] "" Vector__XXX
 SG_ BRL_als_SHL  : 62|1@1+ (1.000000,0.000000) [0.000000|1.000000] "" Vector__XXX

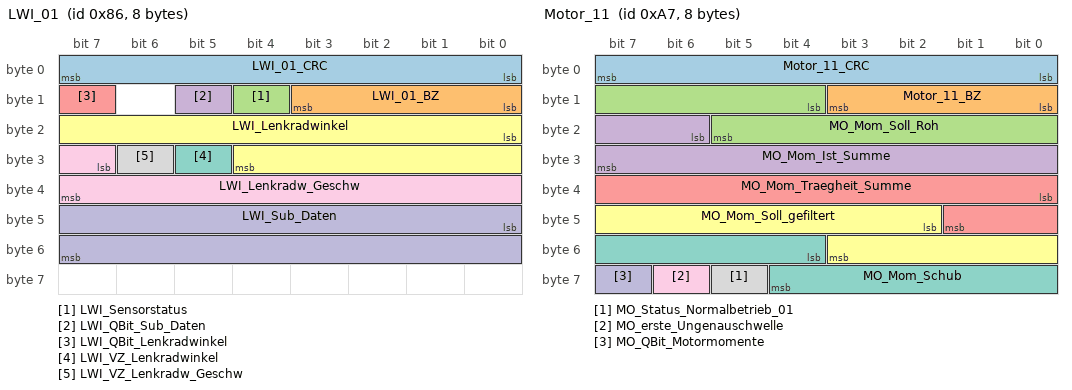
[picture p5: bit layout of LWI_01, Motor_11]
BO_ 134 LWI_01: 8 ICAS1_Gateway
 SG_ LWI_01_CRC  : 0|8@1+ (1.000000,0.000000) [0.000000|255.000000] "" Airbag Motor_BEV
 SG_ LWI_01_BZ  : 8|4@1+ (1.000000,0.000000) [0.000000|15.000000] "" Airbag Motor_BEV
 SG_ LWI_Sensorstatus  : 12|1@1+ (1.000000,0.000000) [0.000000|1.000000] "" Airbag Motor_BEV
 SG_ LWI_QBit_Sub_Daten  : 13|1@1+ (1.000000,0.000000) [0.000000|1.000000] "" Vector__XXX
 SG_ LWI_QBit_Lenkradwinkel  : 15|1@1+ (1.000000,0.000000) [0.000000|1.000000] "" Airbag Motor_BEV
 SG_ LWI_Lenkradwinkel  : 16|13@1+ (0.100000,0.000000) [0.000000|800.000000] "Unit_DegreOfArc" Airbag Motor_BEV
 SG_ LWI_VZ_Lenkradwinkel  : 29|1@1+ (1.000000,0.000000) [0.000000|1.000000] "" Airbag Motor_BEV
 SG_ LWI_VZ_Lenkradw_Geschw  : 30|1@1+ (1.000000,0.000000) [0.000000|1.000000] "" Vector__XXX
 SG_ LWI_Lenkradw_Geschw  : 31|9@1+ (5.000000,0.000000) [0.000000|2500.000000] "Unit_DegreOfArcPerSecon" Airbag
 SG_ LWI_Sub_Daten  : 40|16@1+ (1.000000,0.000000) [0.000000|65535.000000] "" Vector__XXX

BO_ 817 MFL_01: 8 ICAS1_Gateway
 SG_ MFL_Zaehler  : 0|4@1+ (1.000000,0.000000) [0.000000|15.000000] "" Vector__XXX
 SG_ MFL_Toggle  : 4|1@1+ (1.000000,0.000000) [0.000000|1.000000] "" Vector__XXX
 SG_ MFL_Lokalaktiv  : 5|1@1+ (1.000000,0.000000) [0.000000|1.000000] "" Vector__XXX
 SG_ MFL_M_Taste  : 6|1@1+ (1.000000,0.000000) [0.000000|1.000000] "" Vector__XXX
 SG_ MFL_Paddle_Verbau  : 7|1@1+ (1.000000,0.000000) [0.000000|1.000000] "" Vector__XXX
 SG_ MFL_Tastencode_1  : 8|8@1+ (1.000000,0.000000) [0.000000|255.000000] "" Vector__XXX
 SG_ MFL_Tastencode_2  : 16|8@1+ (1.000000,0.000000) [0.000000|255.000000] "" Vector__XXX
 SG_ MFL_Eventcode_1  : 24|4@1+ (1.000000,0.000000) [0.000000|15.000000] "" Vector__XXX
 SG_ MFL_Eventcode_2  : 28|4@1+ (1.000000,0.000000) [0.000000|15.000000] "" Vector__XXX
 SG_ MFL_Marke  : 32|4@1+ (1.000000,0.000000) [0.000000|15.000000] "" Vector__XXX
 SG_ MFL_Variante  : 36|4@1+ (1.000000,0.000000) [0.000000|15.000000] "" Vector__XXX
 SG_ MFL_Dummy_0_Signal_1  : 40|8@1+ (1.000000,0.000000) [0.000000|255.000000] "" Vector__XXX
 SG_ MFL_Tip_Down  : 48|1@1+ (1.000000,0.000000) [0.000000|1.000000] "" Motor_BEV
 SG_ MFL_Tip_Up  : 49|1@1+ (1.000000,0.000000) [0.000000|1.000000] "" Motor_BEV
 SG_ MFL_SatModul_links_Err  : 50|1@1+ (1.000000,0.000000) [0.000000|1.000000] "" Vector__XXX
 SG_ MFL_SatModul_rechts_Err  : 51|1@1+ (1.000000,0.000000) [0.000000|1.000000] "" Vector__XXX
 SG_ MFL_Dummy_0_Signal_2  : 52|1@1+ (1.000000,0.000000) [0.000000|1.000000] "" Vector__XXX
 SG_ MFL_Dummy_0_Signal_3  : 53|1@1+ (1.000000,0.000000) [0.000000|1.000000] "" Vector__XXX
 SG_ MFL_LR_HZG_Status  : 54|1@1+ (1.000000,0.000000) [0.000000|1.000000] "" Vector__XXX
 SG_ MFL_LR_HZG_Err  : 55|1@1+ (1.000000,0.000000) [0.000000|1.000000] "" Vector__XXX
 SG_ MFL_Signalhorn  : 56|1@1+ (1.000000,0.000000) [0.000000|1.000000] "" Vector__XXX
 SG_ MFL_Signalhorn_Err  : 57|1@1+ (1.000000,0.000000) [0.000000|1.000000] "" Vector__XXX
 SG_ MFL_Tip_links_Err  : 58|1@1+ (1.000000,0.000000) [0.000000|1.000000] "" Vector__XXX
 SG_ MFL_Tip_rechts_Err  : 59|1@1+ (1.000000,0.000000) [0.000000|1.000000] "" Vector__XXX
 SG_ MFL_Taste_links_Err  : 60|1@1+ (1.000000,0.000000) [0.000000|1.000000] "" Vector__XXX
 SG_ MFL_Taste_rechts_Err  : 61|1@1+ (1.000000,0.000000) [0.000000|1.000000] "" Vector__XXX
 SG_ MFL_ECU_Err  : 62|1@1+ (1.000000,0.000000) [0.000000|1.000000] "" Vector__XXX
 SG_ MFL_Response_Err  : 63|1@1+ (1.000000,0.000000) [0.000000|1.000000] "" Vector__XXX

BO_ 15 MO_SOPC: 1 Motor_BEV
 SG_ MO_SOPC  : 0|1@1+ (1.000000,0.000000) [0.000000|1.000000] "" Vector__XXX

BO_ 1600 Motor_07: 8 Motor_BEV
 SG_ MO_QBit_Ansaugluft_Temp  : 0|1@1+ (1.000000,0.000000) [0.000000|1.000000] "" Vector__XXX
 SG_ MO_QBit_Oel_Temp  : 1|1@1+ (1.000000,0.000000) [0.000000|1.000000] "" Vector__XXX
 SG_ MO_QBit_Kuehlmittel_Temp  : 2|1@1+ (1.000000,0.000000) [0.000000|1.000000] "" Vector__XXX
 SG_ MO_KL15_Abschaltempfehlung  : 3|1@1+ (1.000000,0.000000) [0.000000|1.000000] "" Vector__XXX
 SG_ MO_HYB_Fehler_HV_Netz  : 4|1@1+ (1.000000,0.000000) [0.000000|1.000000] "" Vector__XXX
 SG_ MO_aktives_Getriebeheizen  : 5|1@1+ (1.000000,0.000000) [0.000000|1.000000] "" Vector__XXX
 SG_ MO_Absperrventil_oeffnen  : 6|2@1+ (1.000000,0.000000) [0.000000|3.000000] "" Vector__XXX
 SG_ MO_Ansaugluft_Temp  : 8|8@1+ (0.750000,-48.000000) [-48.000000|141.750000] "Unit_DegreCelsi" Vector__XXX
 SG_ MO_Oel_Temp  : 16|8@1+ (1.000000,-60.000000) [-60.000000|192.000000] "Unit_DegreCelsi" Vector__XXX
 SG_ MO_Kuehlmittel_Temp  : 24|8@1+ (0.750000,-48.000000) [-48.000000|141.750000] "Unit_DegreCelsi" Vector__XXX
 SG_ MO_Hoeheninfo  : 32|8@1+ (0.007810,0.000000) [0.000000|1.983740] "" Vector__XXX
 SG_ MO_Kennfeldk  : 40|1@1+ (1.000000,0.000000) [0.000000|1.000000] "" Vector__XXX
 SG_ MO_Versionsinfo_02  : 41|5@1+ (1.000000,0.000000) [0.000000|31.000000] "" Vector__XXX
 SG_ MO_QBit_Hoeheninfo  : 46|1@1+ (1.000000,0.000000) [0.000000|1.000000] "" Vector__XXX
 SG_ MO_Getriebe_kuehlen  : 47|1@1+ (1.000000,0.000000) [0.000000|1.000000] "" Vector__XXX
 SG_ MO_Mom_Traegheit_02  : 48|5@1+ (0.010000,0.000000) [0.000000|0.310000] "Unit_KiloGramMeterSquar" Vector__XXX
 SG_ MO_Heizungspumpenansteuerung  : 53|4@1+ (10.000000,0.000000) [0.000000|100.000000] "Unit_PerCent" Vector__XXX
 SG_ MO_SpannungsAnf  : 57|1@1+ (1.000000,0.000000) [0.000000|1.000000] "" Vector__XXX
 SG_ MO_Nachlaufzeit_Heizungspumpe  : 58|6@1+ (15.000000,0.000000) [0.000000|945.000000] "Unit_Secon" Vector__XXX

BO_ 167 Motor_11: 8 Motor_BEV
 SG_ Motor_11_CRC  : 0|8@1+ (1.000000,0.000000) [0.000000|255.000000] "" ICAS1_Gateway
 SG_ Motor_11_BZ  : 8|4@1+ (1.000000,0.000000) [0.000000|15.000000] "" ICAS1_Gateway
 SG_ MO_Mom_Soll_Roh  : 12|10@1+ (1.000000,-509.000000) [-509.000000|509.000000] "" ICAS1_Gateway
 SG_ MO_Mom_Ist_Summe  : 22|10@1+ (1.000000,-509.000000) [-509.000000|509.000000] "" ICAS1_Gateway
 SG_ MO_Mom_Traegheit_Summe  : 32|10@1+ (1.000000,-509.000000) [-509.000000|509.000000] "" ICAS1_Gateway
 SG_ MO_Mom_Soll_gefiltert  : 42|10@1+ (1.000000,-509.000000) [-509.000000|509.000000] "" ICAS1_Gateway
 SG_ MO_Mom_Schub  : 52|9@1+ (1.000000,-509.000000) [-509.000000|0.000000] "" ICAS1_Gateway
 SG_ MO_Status_Normalbetrieb_01  : 61|1@1+ (1.000000,0.000000) [0.000000|1.000000] "" ICAS1_Gateway
 SG_ MO_erste_Ungenauschwelle  : 62|1@1+ (1.000000,0.000000) [0.000000|1.000000] "" ICAS1_Gateway
 SG_ MO_QBit_Motormomente  : 63|1@1+ (1.000000,0.000000) [0.000000|1.000000] "" ICAS1_Gateway

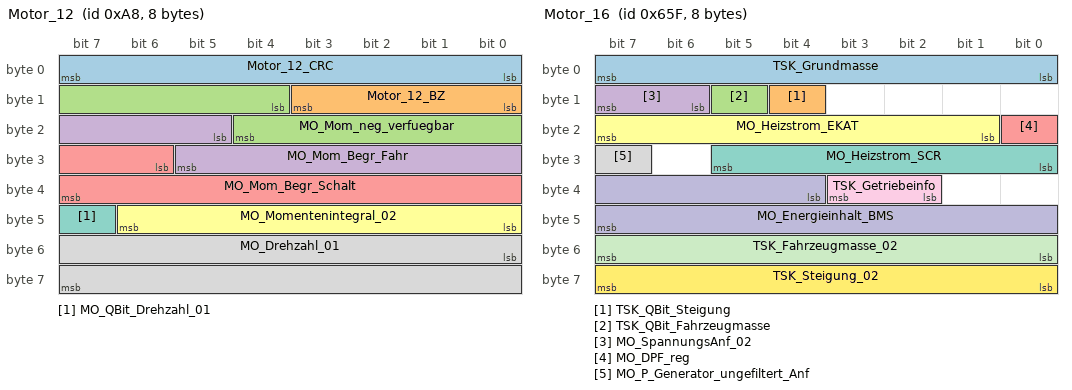
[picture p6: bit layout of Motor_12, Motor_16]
BO_ 168 Motor_12: 8 Motor_BEV
 SG_ Motor_12_CRC  : 0|8@1+ (1.000000,0.000000) [0.000000|255.000000] "" ICAS1_Gateway
 SG_ Motor_12_BZ  : 8|4@1+ (1.000000,0.000000) [0.000000|15.000000] "" ICAS1_Gateway
 SG_ MO_Mom_neg_verfuegbar  : 12|9@1+ (1.000000,-509.000000) [-509.000000|0.000000] "" ICAS1_Gateway
 SG_ MO_Mom_Begr_Fahr  : 21|9@1+ (1.000000,0.000000) [0.000000|509.000000] "" ICAS1_Gateway
 SG_ MO_Mom_Begr_Schalt  : 30|10@1+ (1.000000,-509.000000) [-509.000000|509.000000] "" ICAS1_Gateway
 SG_ MO_Momentenintegral_02  : 40|7@1+ (1.000000,0.000000) [0.000000|100.000000] "Unit_PerCent" ICAS1_Gateway
 SG_ MO_QBit_Drehzahl_01  : 47|1@1+ (1.000000,0.000000) [0.000000|1.000000] "" Airbag ICAS1_Gateway LE2
 SG_ MO_Drehzahl_01  : 48|16@1+ (0.250000,0.000000) [0.000000|16383.000000] "Unit_MinutInver" ICAS1_Gateway

BO_ 958 Motor_14: 8 Motor_BEV
 SG_ Motor_14_CRC  : 0|8@1+ (1.000000,0.000000) [0.000000|255.000000] "" ICAS1_Gateway
 SG_ Motor_14_BZ  : 8|4@1+ (1.000000,0.000000) [0.000000|15.000000] "" ICAS1_Gateway
 SG_ MO_StartStopp_Status  : 12|2@1+ (1.000000,0.000000) [0.000000|3.000000] "" ICAS1_Gateway
 SG_ MO_StartStopp_Wiederstart  : 14|1@1+ (1.000000,0.000000) [0.000000|1.000000] "" ICAS1_Gateway
 SG_ MO_StartStopp_Motorstopp  : 15|1@1+ (1.000000,0.000000) [0.000000|1.000000] "" ICAS1_Gateway
 SG_ MO_Freig_Reku  : 16|2@1+ (1.000000,0.000000) [0.000000|3.000000] "" ICAS1_Gateway
 SG_ MO_Kl_75  : 18|1@1+ (1.000000,0.000000) [0.000000|1.000000] "" ICAS1_Gateway
 SG_ MO_Kl_50  : 19|1@1+ (1.000000,0.000000) [0.000000|1.000000] "" ICAS1_Gateway
 SG_ MO_Gangposition  : 20|4@1+ (1.000000,0.000000) [0.000000|15.000000] "" ICAS1_Gateway
 SG_ MO_StartStopp_Fahrerwunsch  : 24|2@1+ (1.000000,0.000000) [0.000000|3.000000] "" ICAS1_Gateway
 SG_ MO_HYB_Fahrbereitschaft  : 26|1@1+ (1.000000,0.000000) [0.000000|1.000000] "" ICAS1_Gateway
 SG_ MO_Ext_E_Fahrt_aktiv  : 27|1@1+ (1.000000,0.000000) [0.000000|1.000000] "" ICAS1_Gateway
 SG_ MO_Fahrer_bremst  : 28|1@1+ (1.000000,0.000000) [0.000000|1.000000] "" Airbag ICAS1_Gateway
 SG_ MO_QBit_Fahrer_bremst  : 29|1@1+ (1.000000,0.000000) [0.000000|1.000000] "" Airbag ICAS1_Gateway
 SG_ MO_BLS  : 30|1@1+ (1.000000,0.000000) [0.000000|1.000000] "" Airbag ICAS1_Gateway
 SG_ MO_Konsistenz_Bremsped  : 31|1@1+ (1.000000,0.000000) [0.000000|1.000000] "" ICAS1_Gateway
 SG_ MO_Timeout_ESP  : 32|1@1+ (1.000000,0.000000) [0.000000|1.000000] "" ICAS1_Gateway
 SG_ MO_Klima_Eingr  : 33|2@1+ (1.000000,0.000000) [0.000000|3.000000] "" ICAS1_Gateway
 SG_ MO_Aussp_Anlass  : 35|1@1+ (1.000000,0.000000) [0.000000|1.000000] "" ICAS1_Gateway
 SG_ MO_Freig_Anlass  : 36|1@1+ (1.000000,0.000000) [0.000000|1.000000] "" ICAS1_Gateway
 SG_ MO_Kuppl_schalter  : 37|1@1+ (1.000000,0.000000) [0.000000|1.000000] "" ICAS1_Gateway
 SG_ MO_Interlock  : 38|1@1+ (1.000000,0.000000) [0.000000|1.000000] "" ICAS1_Gateway
 SG_ MO_Motor_laeuft  : 39|1@1+ (1.000000,0.000000) [0.000000|1.000000] "" ICAS1_Gateway
 SG_ MO_Kickdown  : 40|1@1+ (1.000000,0.000000) [0.000000|1.000000] "" ICAS1_Gateway ICAS1_KommunikationsServer
 SG_ MO_QBit_KL_75  : 41|1@1+ (1.000000,0.000000) [0.000000|1.000000] "" ICAS1_Gateway
 SG_ MO_EKlKomLeiRed  : 42|2@1+ (1.000000,0.000000) [0.000000|3.000000] "" ICAS1_Gateway
 SG_ MO_Handshake_STH  : 44|1@1+ (1.000000,0.000000) [0.000000|1.000000] "" ICAS1_Gateway
 SG_ MO_BKV_Unterdruckwarnung  : 45|1@1+ (1.000000,0.000000) [0.000000|1.000000] "" ICAS1_Gateway
 SG_ MO_Freigabe_Segeln  : 46|1@1+ (1.000000,0.000000) [0.000000|1.000000] "" ICAS1_Gateway
 SG_ MO_PTC_Status  : 47|3@1+ (1.000000,0.000000) [0.000000|7.000000] "" ICAS1_Gateway
 SG_ MO_QBit_Gangposition  : 50|1@1+ (1.000000,0.000000) [0.000000|1.000000] "" ICAS1_Gateway
 SG_ MO_Signalquelle_Gangposition  : 51|1@1+ (1.000000,0.000000) [0.000000|1.000000] "" ICAS1_Gateway
 SG_ MO_Remotestart_Betrieb  : 52|1@1+ (1.000000,0.000000) [0.000000|1.000000] "" ICAS1_Gateway
 SG_ MO_Remotestart_moeglich  : 53|1@1+ (1.000000,0.000000) [0.000000|1.000000] "" ICAS1_Gateway
 SG_ MO_FMAus_aktiv  : 55|1@1+ (1.000000,0.000000) [0.000000|1.000000] "" ICAS1_Gateway
 SG_ MO_FMAus_Startvariante  : 56|2@1+ (1.000000,0.000000) [0.000000|3.000000] "" ICAS1_Gateway
 SG_ MO_BMS_NV_Anf_stuetzen  : 58|1@1+ (1.000000,0.000000) [0.000000|1.000000] "" ICAS1_Gateway
 SG_ MO_Zylinderabschaltung  : 59|2@1+ (1.000000,0.000000) [0.000000|3.000000] "" ICAS1_Gateway
 SG_ MO_HYB_VM_aktiv  : 61|1@1+ (1.000000,0.000000) [0.000000|1.000000] "" ICAS1_Gateway
 SG_ MO_StartVorauss_erfuellt  : 62|2@1+ (1.000000,0.000000) [0.000000|3.000000] "" ICAS1_Gateway

BO_ 1631 Motor_16: 8 Motor_BEV
 SG_ TSK_Grundmasse  : 0|8@1+ (32.000000,0.000000) [0.000000|8128.000000] "Unit_KiloGram" ICAS1_Gateway
 SG_ TSK_QBit_Steigung  : 12|1@1+ (1.000000,0.000000) [0.000000|1.000000] "" ICAS1_Gateway
 SG_ TSK_QBit_Fahrzeugmasse  : 13|1@1+ (1.000000,0.000000) [0.000000|1.000000] "" ICAS1_Gateway
 SG_ MO_SpannungsAnf_02  : 14|2@1+ (1.000000,0.000000) [0.000000|3.000000] "" ICAS1_Gateway
 SG_ MO_DPF_reg  : 16|1@1+ (1.000000,0.000000) [0.000000|1.000000] "" ICAS1_Gateway
 SG_ MO_Heizstrom_EKAT  : 17|7@1+ (1.000000,0.000000) [0.000000|126.000000] "Unit_Amper" ICAS1_Gateway
 SG_ MO_Heizstrom_SCR  : 24|6@1+ (1.000000,0.000000) [0.000000|62.000000] "Unit_Amper" ICAS1_Gateway
 SG_ MO_P_Generator_ungefiltert_Anf  : 31|1@1+ (1.000000,0.000000) [0.000000|1.000000] "" ICAS1_Gateway
 SG_ TSK_Getriebeinfo  : 34|2@1+ (1.000000,0.000000) [0.000000|3.000000] "" ICAS1_Gateway
 SG_ MO_Energieinhalt_BMS  : 36|12@1+ (25.000000,0.000000) [0.000000|102325.000000] "Unit_WattHour" ICAS1_Gateway
 SG_ TSK_Fahrzeugmasse_02  : 48|8@1+ (32.000000,0.000000) [0.000000|8128.000000] "Unit_KiloGram" ICAS1_Gateway
 SG_ TSK_Steigung_02  : 56|8@1+ (0.800000,-101.600000) [-100.800000|101.600000] "Unit_PerCent" ICAS1_Gateway

CM_ BO_ 2527679583 "ehemalsZFAS_01";
CM_ BO_ 2621505536 "VWAGDiagnosefunktionalerRequestaufCANFD";
CM_ BO_ 960 "MQB";
CM_ BO_ 949 "abMQB7.4";
CM_ BO_ 1505 "abMQB7.3";
CM_ BO_ 982 "MQB";
CM_ BO_ 134 "abMQBmitCRCinByte1";
CM_ BO_ 1600 "abMQBmitQBitHöheneinfoundMO_Versionsinfo_02";
CM_ BO_ 168 "Teil2neueMomentenschnittstelleMLB";
CM_ SG_ 2527679583 Parken_Seitenspiegel_Anf "AnforderungfürSeitenspiegelan-oderabklappenbeimPiloPa";
CM_ SG_ 2527679583 Parken_ZV_Schliessen "AnforderungfürZentralverriegelungverriegelnodersafenbeimPiloPa";
CM_ SG_ 2527679583 Parken_aktives_System_02 "zeigtanwelchesparkendesSystemaktivist";
CM_ SG_ 2527679583 Parken_ZR_Sondermodus_Anf "AnforderungSondermodus,umbeim„pilotiertenParken“spezielleFunktionsanpassungenimInfotainment-Bereichzuermöglichen(u.a.schnellererStartup,AbschaltungBT)";
CM_ SG_ 2527679583 Parken_Schluesselsuche_Anf "AnsteuerungderSchlüsselsuchefürdaspilotierteParken.";
CM_ SG_ 2527679583 Parken_FFB_LED_Anf "StatusinformationdesPilotiertenParkensfürdieAnsteuerungderLEDaufderFunkfernbedienung.";
CM_ SG_ 2527679583 Parken_Wegfahrsperren_Anf "AnsteuerungderWegfahrsperrenKomponentenfürdaspilotierteParken.";
CM_ SG_ 2527679583 Parken_Aktivierungslicht_Anf "AnforderungdesAktivierungslichtsnacherfolgreicherAktivierungshandlungseitensPilotiertemParken.";
CM_ SG_ 2527679583 Parken_Fahrtrichtungslicht_Anf "AnforderungseitensPilotiertemParkenfürdieAnzeigederinitialenFahrtrichtungnachSystemaktivierung.";
CM_ SG_ 2527679583 Parken_Lichtnachlauf_Anf "AnforderungdesLichtnachlaufsbeimBCM1(analogVerlassenskonzept)fürdasPilotierteParken.";
CM_ SG_ 2527679583 Parken_Fahrerhinweise_Anf "AnforderungzurerneutenLampenaufprüfungundAnzeigevonWarnhinweisennacheinempilotiertenAusparkvorgang.";
CM_ SG_ 2527679583 Parken_Bestaetigungsblinken_Anf "AnforderungseitensPilotiertemParkenfüreinErfolgsblinkennachdemErreichenderZielpositionbzw.füreinAbbruchsblinkenbeiEintreteneinerAbbruchsbedingung.";
CM_ SG_ 2527679583 Parken_Fahrbereitschaftlicht_Anf "AnforderungdesFahrbereitschaftslichts";
CM_ SG_ 2527679583 Parken_Lichtsteuerung_Anf "AnforderungzumSetzendesLichtmodusdesFahrzeugesvonderParkfunktion";
CM_ SG_ 2527679583 IPA_Anf_Meldungen "AnforderungderMeldungen:
0 - Keine Meldung
1-127 IPA niederprio. Meldungen
128-191 IPA hochprio. Meldungen
192-207 TPA Meldungen
208-255 Vorhalt";
CM_ SG_ 1813 ISO_Airbag_01_Req_Data "DiagnoseRequestAirbagsteuergeraet";
CM_ SG_ 1919 ISO_Airbag_01_Resp_Data "DiagnoseResponseAirbagsteuergeraet";
CM_ SG_ 1792 ISO_ALL_01_Req_Data "FunktionalerRequestALL";
CM_ SG_ 2621440021 ISOx_Airbag_01_Req_FD_Data "DiagnoseRequest";
CM_ SG_ 2621571093 ISOx_Airbag_01_Resp_FD_Data "DiagnoseResponse";
CM_ SG_ 2549874812 ISO_EMotor_01_Req_Data "DiagnoseRequestLeistungselektronikE-Maschine1";
CM_ SG_ 2621440124 ISOx_EMotor_01_Req_FD_Data "DiagnoseRequest";
CM_ SG_ 2550005884 ISO_EMotor_01_Resp_Data "DiagnoseResponseLeistungselektronikE-Maschine1";
CM_ SG_ 2621571196 ISOx_EMotor_01_Resp_FD_Data "DiagnoseResponse";
CM_ SG_ 2549874872 ISO_EMotor_02_Req_Data "DiagnoseRequestLeistungselektronikE-Maschine2";
CM_ SG_ 2621440184 ISOx_EMotor_02_Req_FD_Data "DiagnoseRequest";
CM_ SG_ 2550005944 ISO_EMotor_02_Resp_Data "DiagnoseResponseLeistungselektronikE-Maschine2";
CM_ SG_ 2621571256 ISOx_EMotor_02_Resp_FD_Data "DiagnoseResponse";
CM_ SG_ 2621505536 ISOx_Funkt_Req_All_FD_Data "VWAGDiagnosefunktionalerRequestaufCANFD";
CM_ SG_ 2549874806 ISOx_MO_01_Req_Data "DiagnoseRequest";
CM_ SG_ 2621440118 ISOx_MO_01_Req_FD_Data "DiagnoseRequest";
CM_ SG_ 2550005878 ISOx_MO_01_Resp_Data "DiagnoseResponse";
CM_ SG_ 2621571190 ISOx_MO_01_Resp_FD_Data "DiagnoseResponse";
CM_ SG_ 2527679684 Kamera_ASM_Ereignis "DiesesSignaldefiniert,welcheFunktionundwelcheArtvonAktivitätdasSendenderBotschaftandenAssistenzsystemmonitorASMveranlassthat.";
CM_ SG_ 2527679684 Kamera_ASM_Zeitstempel "DiesesSignalermöglichtdiezeitlicheZuordnungdervonACCandenAssistenzsystemmonitorASMgesendetenStatusbotschaften.";
CM_ SG_ 2527679684 Kamera_ASM_Data_1 "DiesesSignalwirdvonderFrontkamerabefülltundandenAssistenzsystemmonitorASMgesendet.";
CM_ SG_ 2527679684 Kamera_ASM_Data_2 "DiesesSignalwirdvonderFrontkamerabefülltundandenAssistenzsystemmonitorASMgesendet.";
CM_ SG_ 2527679684 Kamera_ASM_Data_3 "DiesesSignalwirdvonderFrontkamerabefülltundandenAssistenzsystemmonitorASMgesendet.";
CM_ SG_ 2527679684 Kamera_ASM_Data_4 "DiesesSignalwirdvonderFrontkamerabefülltundandenAssistenzsystemmonitorASMgesendet.";
CM_ SG_ 2527679684 Kamera_ASM_Data_5 "DiesesSignalwirdvonderFrontkamerabefülltundandenAssistenzsystemmonitorASMgesendet.";
CM_ SG_ 2527679684 Kamera_ASM_Data_6 "DiesesSignalwirdvonderFrontkamerabefülltundandenAssistenzsystemmonitorASMgesendet.";
CM_ SG_ 960 Klemmen_Status_01_CRC "FürMLB:
'Berechnung siehe Lastenheft 'Kommunikationsabsicherung für FlexRay und CAN''

Ab MQB und MLBevo:
'Berechnung siehe Lastenheft 'End-to-End Kommunikationsabsicherung''

Endwerte siehe Begleitdokument 'S-PDU Kennungsfolgen'";
CM_ SG_ 960 Klemmen_Status_01_BZ "4bitBotschaftszaehler;wirdinjederSendebotschaftinkrementiert";
CM_ SG_ 960 RSt_Fahrerhinweise "ÜberdasSignalfordertdasBCMFahrerhinweiseimKombifürdieFunktionRemoteStartan.";
CM_ SG_ 960 ZAS_Kl_S "KlemmeS:S-Kontakt(Schluesselsteckt)
";
CM_ SG_ 960 ZAS_Kl_15 "Klemme15:Zuendung(SW-Kl.15)
";
CM_ SG_ 960 ZAS_Kl_X "Klemme75
";
CM_ SG_ 960 ZAS_Kl_50_Startanforderung "Klemme50:StartwunschFahrer
";
CM_ SG_ 960 BCM_Remotestart_Betrieb "ZeigtdenStatusdesRemoteStartsan,d.h.KL15_RStistaktiviertundderMotorlaufistimRSt-Betriebaktiv.";
CM_ SG_ 960 ZAS_Kl_Infotainment "SeparateKlemmeninformationfürdasInfotainment.SignalentsprichtimwesentlicheneinerKlemmeSInformation,kannaberübereinenVor-bzw.NachlaufzuKlemmeSverfügen.
Ein konkreter Anwendungsfall für einen Nachlauf ist die Abschaltung der Klemme";
CM_ SG_ 960 BCM_Remotestart_KL15_Anf "ZeigtdenStatusderAktivierungderKL15_RSTdurchdasBCMan.";
CM_ SG_ 960 BCM_Remotestart_MO_Start "NachdemdasBCMdieRemotestartMSGFreigabesichererkannthat,fordertdasBCMwiederumüberdiesesSignalvomMSGeinenMotorstartdurchzuführen.";
CM_ SG_ 960 KST_Warn_P1_ZST_def "KombiPrioWarnungKlemmensteuerung
Zündschloß defekt, Service aufsuchen!";
CM_ SG_ 960 KST_Warn_P2_ZST_def "KombiPrioWarnungKlemmensteuerung
Zündschloß defekt!
";
CM_ SG_ 960 KST_Fahrerhinweis_1 "SignalisierungFahrerhinweis1derKlemmensteuerungandasKombi";
CM_ SG_ 960 KST_Fahrerhinweis_2 "SignalisierungFahrerhinweis2derKlemmensteuerungandasKombi";
CM_ SG_ 960 BCM_Ausparken_Betrieb "AnforderungzurerneutenLampenaufprüfungundAnzeigevonWarnhinweisennacheinempilotiertenAusparkvorgang(Trigger:fallendeFlanke)";
CM_ SG_ 960 KST_Fahrerhinweis_4 "SignalisierungFahrerhinweis4derKlemmensteuerungandasKombi";
CM_ SG_ 960 KST_Fahrerhinweis_5 "AnzeigesignalfürRemoteStart";
CM_ SG_ 960 KST_Fahrerhinweis_6 "SignalaktiviertdieKombi-Anzeigeinstrumente(Drehzahl,Tankinhalt,Kühlmitteltemperatur)währendaktiviertemRemoteStart-Betrieb";
CM_ SG_ 2463978753 KST_WFS_Fahrfreigabe_Anforderung "HiermitwirddenWegfahrsperren-TeilnehmernsignalisiertwelcheArtderFahrfreigabevonderanforderndenSonderfunktionbenötigtwird";
CM_ SG_ 2463978753 KST_Sonderzustand_Status "Hiermitwirdsignalisiert,dasseineSonderfunktionaktivistunddieKlemme15durchdieseangefordertwurdebzw.einÜbergangvonSonderfunktionenstattfindet";
CM_ SG_ 2463978753 KST_Sonderzustand_Anforderung "Hiermitwirddieaktivebzw.aktuellangeforderte(s.KST_Sonderzustand_Status)Sonderfunktionidentifiziert";
CM_ SG_ 1420 Klemmen_Steuerung_01_CRC "AbMQBundMLBevo:
'Berechnung siehe Lastenheft 'End-to-End Kommunikationsabsicherung''

Endwerte siehe Begleitdokument 'S-PDU Kennungsfolgen'";
CM_ SG_ 1420 Klemmen_Steuerung_01_BZ "4bitBotschaftszaehler;wirdinjederSendebotschaftinkrementiert";
CM_ SG_ 1420 KST_Anf_Klemme_15 "AnforderungderKlemme15andasBCM.SignalwirdzurPlausibilisierungparallelzumKlemmensignalaufdemCANübertragen.";
CM_ SG_ 1420 KST_Anf_Klemme_50 "AnforderungderKlemme50andasMSG.SignalwirdzurPlausibilisierungparallelzumKlemmensignalaufdemCANübertragen.";
CM_ SG_ 1420 KST_Anf_Klemme_S "AnforderungderKlemmeSandasBCM.SignalwirdzurPlausibilisierungparallelzumKlemmensignalaufdemCANübertragen.";
CM_ SG_ 1420 KST_Txt_Werkstatt "Text:'Klemmensteuerung!Werkstatt!'";
CM_ SG_ 1420 KST_Txt_P_Gang "Text:'WählhebelinPositionPbringen!'";
CM_ SG_ 1420 KST_Txt_Panikabschaltung "Text:'Notabschaltung''";
CM_ SG_ 1420 KST_Anf_Klemmenfreigabe_ELV "KlemmensteuerungfordertKlemmen-FreigabedurchdieELVan.";
CM_ SG_ 1420 KST_Txt_Komfortabschaltung "DiesesSignalfordertimKombidieMeldungan,diedenFahrerüberdieausgeführteautomatischeZündungsabschaltunginformiert.Signalwirdfür10sgesendet.";
CM_ SG_ 1420 KST_ZAT_betaetigt "Zündanlass-Taster(ZAT)betätigt";
CM_ SG_ 1420 KST_Unterdr_Zuendungsmeldung "BeiaktivemSignalsolldieZündungsmeldungdurchdasKombiunterdrücktwerden.";
CM_ SG_ 1420 KST_aut_Abschaltung_Zuendung "FallsbeieingeschalteterZündungdasAbblendlichtaktivwar,mussnachderautomatischenAbschaltungderKl_15&Kl_S,dassStandlichtaktivbleiben.DasSignalsendetdieInformation,dasseineautomatischeAbschaltungderKl_15undKl_Serfogt.";
CM_ SG_ 1420 KST_Anf_Klemmenfreigabe_WFS "AnforderungderFreigabevonderWFSzumEinschaltenvonKlemme15undKlemmeS";
CM_ SG_ 1420 KST_Anf_ZV_Verriegelung "NeuerVerriegelungstriggerfürdieZVnachderautomatischenKlemmenabschaltung.

Wird bei Kessyfahrzeugen mit StartStop ein aktiver Stop-Mode und Fahrerverlassen erkannt, startet ein 30 Sekunden-Timer. Innerhalb dieser 30 Sekunden hat der Fahrer die Mö";
CM_ SG_ 1420 Relais_VoKo_angesteuert "SignalzurRückmeldung,obdasRelaisfürdieVerbrauchervonerweiterteVoko/RemoteStartangesteuertwird.";
CM_ SG_ 1420 RSt_Anforderung_HMS "AnforderungvomRSt(RemoteStart)andasHMS(HaltemanagementSystem)";
CM_ SG_ 1420 KST_Zuendungswarnung "BeiaktivemSignalsolljenachgesetztemStatuseineWarnungdurchdasKombiausgegebenwerden";
CM_ SG_ 1420 KST_Fahrer_Info_Text "HinweisefürdenFahrerfürdieFahrzeugaktivierung/-deaktivierung";
CM_ SG_ 949 KL_Drehz_Anh "DrehzahlanhebungvomMotorangefordert

";
CM_ SG_ 949 KL_Vorwarn_Komp_ein "VorwarnungKompressorein;140msvorher;InformationfürMotorzumAufbauMomentenreserve";
CM_ SG_ 949 KL_AC_Schalter "ACSchalter
";
CM_ SG_ 949 KL_Vorwarn_Zuheizer_ein "VorwarnungZuheizerbetrieb
";
CM_ SG_ 949 KL_Zustand "BeschreibtdenZustanddesKlima-/Heizungsbedienteils.(OFF-ModeBedienteil)

PAG (MLB): Beschreibt den Zustand des Kompressors";
CM_ SG_ 949 KL_Kompressorkupplung_linear "SollwertzurAnsteuerungderKompressorkupplung";
CM_ SG_ 949 KL_Charisma_FahrPr "MLBevo:AktuellesFahrprogrammdesCharisma-Teilnehmers(sieheSystemlastenheftDriveSelect)
MQB: Istwert der Kennlinie (siehe Systemlastenheft MQB FPA)";
CM_ SG_ 949 KL_Charisma_Status "CharismaSystemstatusdesCharisma-Teilnehmers

Wert 0x3 ist nur für Fahrzeuge ab MQB relevant";
CM_ SG_ 949 KL_nachtr_Stopp_Anf "DiesesSignaldientdemMotoralsTrigger,dasseinnachträglicherMotorstoppeingeleitetwerdenkann,wennesdieBedingungendesStStKoordinatorsdieszulassen.";
CM_ SG_ 949 KL_T_Charge "SignalfürTastenbetätigungCharge-Taste(SOCIncreasing)";
CM_ SG_ 949 KL_Last_Kompr "AktuellesVerlustmomentderKlimaanlagebezogenaufdieKurbelwelle.WirdderKlimakompressornichtangesteuert,istdasSchleppmomentbezogenaufdieKurbelwellezusenden.";
CM_ SG_ 949 KL_Spannungs_Anf "ForderungdesKlima-SG'szurSpannungsanhebung.";
CM_ SG_ 949 KL_Thermomanagement "StufendesThermomanagement";
CM_ SG_ 949 KL_StartStopp_Info "Stopp-FreigabeundStart-AnforderungandenStart-Stopp-Koordinator";
CM_ SG_ 949 KL_Freilauf_Info "FreilaufInformationssignalvonKlimazumFreilaufkoordinator.KlimakannüberdiesesSignaldenFreilauffreigeben,verhindernbzw.explizitanfordern.";
CM_ SG_ 949 KL_Anf_KL "AnforderungKühlerlüfterderKlimaanlageinProzent

";
CM_ SG_ 949 KL_el_Zuheizer_Stufe "VorgabefürMotorsteuergeraetPTC-Stufe;imMLB-B8undMQBnurStufe0...3

";
CM_ SG_ 949 KL_Ausstattung_Klima "AusttattungsartderKlimabedienung";
CM_ SG_ 949 KL_Variante_Standheizung "IdentifikationderVariantederStandheizungenzurBerechnungderenergetischenZielzeit";
CM_ SG_ 949 KL_Anf_KV "AnforderungdesKühlerrollosin%";
CM_ SG_ 1511 KL_HV_Heizer_Strom "StromHV-HeizerfürReichweitenberechnung";
CM_ SG_ 1511 KL_EKK_Strom "EKKStromaufnahme(Hochvolt)";
CM_ SG_ 1511 KL_Pumpe_02_Soll "AnforderungKM-PumpeKlimakreislauf
Init (126dec)      = 0% Ansteuerung Pumpe
Fehler (127dec) = 100% Ansteuerung Pumpe";
CM_ SG_ 1511 KL_Ventil_03_Soll "AnforderungBatteriebypass-VentilimKlimakreislauf";
CM_ SG_ 1511 KL_Ventil_10_Status "StatusVentil_Wärmepump";
CM_ SG_ 1511 KL_Senderkennung "Gibtan,welchesSG(KlimaoderWP)dieBotschaftsendet";
CM_ SG_ 1511 WP_KJ_Soll "AnforderungderKuehlerjalousiestellungdurchWaermepumpenSG";
CM_ SG_ 1511 KL_Fehler_HV_EKK "FehlersignalbeiErkennungHVFehleramelektrischenKlimakompressorEKK
Sender: Klima MQB (evtl. Wärmepumpen SG MQB, OBD SG MQB)";
CM_ SG_ 1511 KL_Fehler_HV_Heizer "FehlersignalbeiErkennungHVFehleramHVHeizer
Sender: Klima MQB (evtl. Wärmepumpen SG MQB, OBD SG MQB)";
CM_ SG_ 1511 KL_BattKond_WaPu_DZMax "Maximal-DrehzahlderWasserpumpeimBatteriekühlkreislaufalsVorgabefürBMS";
CM_ SG_ 1511 WP_Kuehlerluefter_Anf "AnforderungKühlerlüfterdurchWärmepumpenSG";
CM_ SG_ 1511 KL_KM_ASV_01_Status "SchaltstatusKältemittelAbsperrventil
VW370/9 PHEV = Ventil vor Verdampfer";
CM_ SG_ 1511 KL_KM_ASV_02_Status "SchaltstatusKältemittelAbsperrventil
VW370/9 PHEV = Ventil vor Chiller";
CM_ SG_ 1511 KL_Vorwarn_HVHeizer_Leistung "VorwarnungderHeizerleistungfürdieStromregelung.Botschaft:Klima_EV_03,dadasSignalentwedervomKlimasteuergerätoderdemWärmepumpensteuergerätgesendetwerdensoll.";
CM_ SG_ 1511 KL_Status_EoHVL_EKK "ErkennungeineroffenenHV-Leitung(EoHVL).BewertetanhandeinerSpannungsgrenze.";
CM_ SG_ 1511 KL_Status_EoHVL_Heizer "ErkennungeineroffenenHV-Leitung(EoHVL).BewertetanhandeinerSpannungsgrenze.";
CM_ SG_ 1505 BCM1_Aussen_Temp_ungef "ungefilterterWertdesAussentemperatursensors
";
CM_ SG_ 1505 BCM_Heizungsabsperrventil_Status "DasSignalbeschreibtdenZustanddesHeizungsabsperrventils,welchesalsPortexpandervomBCM1elektrischangesteuertwird.";
CM_ SG_ 1505 BCM_Heizungspumpe_Status "DasSignalbeschreibtdenZustandderHeizungspumpe,welchealsPortexpandervomBCM1elektrischangesteuertwird.";
CM_ SG_ 1505 BCM_Kompressorkupplung_Status "DasSignalbeschreibtdenZustandderKlimakompressorkupplung,welchealsPortexpandervomBCM1elektrischangesteuertwird.";
CM_ SG_ 1505 BCM1_PTC_stufig_Status "StatusdesBCM1-HeizverbrauchersPTC(stufig)";
CM_ SG_ 1505 BCM1_FStatus_Aussentemp_ungef "FehlerstatusfürAussentemperatur(Kombianzeige)";
CM_ SG_ 1505 BCM1_Kompressorstrom_ist "IST-StromvomKlima-Kompressor";
CM_ SG_ 1505 BCM1_OBD_FStatus_ATemp "FehlerstatusUmgebungstemperatursensor(OBDrelevanterSensor)
";
CM_ SG_ 2549088277 Airbag_01_KompSchutz "FunktionseinschränkungaufgrundKomponentenschutzaktiv";
CM_ SG_ 2549088277 Airbag_01_Abschaltstufe "FunktionseinschränkungaufgrundaktiverAbschaltstufe";
CM_ SG_ 2549088277 Airbag_01_Transport_Mode "FunktionseinschränkungaufgrundaktivemTransportModeund/oderTransportSchutz";
CM_ SG_ 2549088277 Airbag_01_Nachlauftyp "AbgebildetwirddievonderHardwarevorgegebeneMöglichkeit,dieKommunikationnachKlemme15=AUSaufrechtzuerhalten.EswirdeinInit-Wertgesendet.
0 = Kommunikation nur bei KL15=EIN (kein Nachlauf, nicht weckfähig)
1 = Kommunikation nach KL15=AU";
CM_ SG_ 2549088277 NM_Airbag_01_Wakeup "enthältdieWeckursache;stehenmehrereWeckursachenparallelan,dannmussderkleinsteWertübertragenwerden";
CM_ SG_ 2549088277 KN_AB_DiagPfad "KennzeichnungderDiagnosefähigkeitdesBusInterfaceseinesSteuergerätes(Knoten)
Umfang LAH 80127

Bei Nutzung des Signal explizit pro angebundenem BusInterface zu setzen:
MQB auf A-CAN = 0 (aktiv)
MQB2020 auf A-CAN = 0 (aktiv)
MLBevo auf FlexRay ";
CM_ SG_ 2549088277 AB_KD_Fehler "BeigesetztemBitistmindestenseinKundendienstfehlereingetragen
";
CM_ SG_ 2549088380 EMotor_KompSchutz "FunktionseinschränkungaufgrundKomponentenschutzaktiv";
CM_ SG_ 2549088380 EMotor_01_Abschaltstufe "FunktionseinschränkungaufgrundaktiverAbschaltstufe";
CM_ SG_ 2549088380 EMotor_01_Transport_Mode "FunktionseinschränkungaufgrundaktivemTransportModeund/oderTransportSchutz";
CM_ SG_ 2549088380 EMotor_Nachlauftyp "AbgebildetwirddievonderHardwarevorgegebeneMöglichkeit,dieKommunikationnachKlemme15=AUSaufrechtzuerhalten.EswirdeinInit-Wertgesendet.
0 = Kommunikation nur bei KL15=EIN (kein Nachlauf, nicht weckfähig)
1 = Kommunikation nach KL15=AU";
CM_ SG_ 2549088380 NM_EMotor_01_Wakeup "enthältdieWeckursache;stehenmehrereWeckursachenparallelan,dannmussderkleinsteWertübertragenwerden";
CM_ SG_ 2549088380 KN_EM_HYB_DiagPfad "KennzeichnungderDiagnosefähigkeitdesBusInterfaceseinesSteuergerätes(Knoten)
Umfang LAH 80127

Bei Nutzung des Signal explizit pro angebundenem BusInterface zu setzen:
MQB AB auf A-CAN = 0 (aktiv)
MQB2020 auf A-CAN = 0 (aktiv)
MEB auf A-CAN = ";
CM_ SG_ 2549088380 EM_HYB_KD_Fehler "BeigesetztemBitistmindestenseinKundendienstfehlereingetragen";
CM_ SG_ 2549088272 Gateway_KompSchutz "FunktionseinschränkungaufgrundKomponentenschutzaktiv";
CM_ SG_ 2549088272 Gateway_Abschaltstufe "FunktionseinschränkungaufgrundaktiverAbschaltstufe";
CM_ SG_ 2549088272 Gateway_Transport_Mode "FunktionseinschränkungaufgrundaktivemTransportModeund/oderTransportSchutz";
CM_ SG_ 2549088272 Gateway_Nachlauftyp "AbgebildetwirddievonderHardwarevorgegebeneMöglichkeit,dieKommunikationnachKlemme15=AUSaufrechtzuerhalten.EswirdeinInit-Wertgesendet.
0 = Kommunikation nur bei KL15=EIN (kein Nachlauf, nicht weckfähig)
1 = Kommunikation nach KL15=AU";
CM_ SG_ 2549088272 NM_Gateway_Wakeup "enthältdieWeckursache;stehenmehrereWeckursachenparallelan,dannmussderkleinsteWertübertragenwerden";
CM_ SG_ 2549088272 KN_GW_DiagPfad "KennzeichnungderDiagnosefähigkeitdesBusInterfaceseinesSteuergerätes(Knoten)
Umfang LAH 80127

Bei Nutzung des Signal explizit pro angebundenem BusInterface zu setzen:
MQB auf Diag-CAN = 0 (aktiv)
MLBevo auf Diag-CAN = 0 (aktiv)
alle weiteren ";
CM_ SG_ 2549088272 GW_KD_Fehler "KundendienstfehlerbitGatewayzurAnzeigeeinesimGatewayabgelegtenFehlerspeichereintrages.";
CM_ SG_ 2549088440 LE2_KompSchutz "FunktionseinschränkungaufgrundKomponentenschutzaktiv";
CM_ SG_ 2549088440 LE2_Abschaltstufe "FunktionseinschränkungaufgrundaktiverAbschaltstufe";
CM_ SG_ 2549088440 LE2_Transport_Mode "FunktionseinschränkungaufgrundaktivemTransportModeund/oderTransportSchutz
";
CM_ SG_ 2549088440 LE2_Nachlauftyp "AbgebildetwirddievonderHardwarevorgegebeneMoeglichkeit,dieKommunikationnachKlemme15=AUSaufrechtzuerhalten.EswirdeinInit-Wertgesendet.
0 = Kommunikation nur bei KL15=EIN (kein Nachlauf, nicht weckfähig)
1 = Kommunikation nach KL15=A";
CM_ SG_ 2549088440 NM_LE2_Wakeup "enthältdieWeckursache;stehenmehrereWeckursachenparallelan,dannmussderkleinsteWertübertragenwerden";
CM_ SG_ 2549088440 KN_LE2_DiagPfad "KennzeichnungderDiagnosefähigkeitdesBusInterfaceseinesSteuergerätes(Knoten)
Umfang LAH 80127

Bei Nutzung des Signal explizit pro angebundenem BusInterface zu setzen:

MQB2020 auf A-CAN = 0 (aktiv)
MEB auf A-CAN = 0 (aktiv)";
CM_ SG_ 2549088440 LE2_KD_Fehler "StatusKundendienst-Fehlerspeicher";
CM_ SG_ 2549088374 Motor_KompSchutz "FunktionseinschränkungaufgrundKomponentenschutzaktiv";
CM_ SG_ 2549088374 MO_01_Abschaltstufe "FunktionseinschränkungaufgrundaktiverAbschaltstufe";
CM_ SG_ 2549088374 MO_01_Transport_Mode "FunktionseinschränkungaufgrundaktivemTransportModeund/oderTransportSchutz";
CM_ SG_ 2549088374 Motor_Nachlauftyp "AbgebildetwirddievonderHardwarevorgegebeneMöglichkeit,dieKommunikationnachKlemme15=AUSaufrechtzuerhalten.EswirdeinInit-Wertgesendet.
0 = Kommunikation nur bei KL15=EIN (kein Nachlauf, nicht weckfähig)
1 = Kommunikation nach KL15=AU";
CM_ SG_ 2549088374 KN_Motor_ECUKnockOutTimer "AusgabedesECUKnockOut-TimerinderKnotenbotschaft";
CM_ SG_ 2549088374 KN_Motor_BusKnockOut "AusgabedesBusKnockout-StatusinderKnotenbotschaft";
CM_ SG_ 2549088374 KN_Motor_BusKnockOutTimer "AusgabedesBusKnockOut-TimerinderKnotenbotschaft";
CM_ SG_ 2549088374 NM_MO_01_Wakeup "enthältdieWeckursache;stehenmehrereWeckursachenparallelan,dannmussderkleinsteWertübertragenwerden";
CM_ SG_ 2549088374 KN_Motor_ECUKnockOut "AusgabedesECUKnockout-StatusinderKnotenbotschaft";
CM_ SG_ 2549088374 KN_MO_DiagPfad "KennzeichnungderDiagnosefähigkeitdesBusInterfaceseinesSteuergerätes(Knoten)
Umfang LAH 80127

Bei Nutzung des Signal explizit pro angebundenem BusInterface zu setzen:

MLBevo auf FlexRay A-Kanal = 0 (aktiv)
MQB auf A-CAN = 0 (aktiv)
MQB2020 ";
CM_ SG_ 2549088374 MO_KD_Fehler "Kundendienstfehlerspeicherbit";
CM_ SG_ 982 Licht_hinten_01_BZ "überlaufender4bitBotschaftszaehler;wirdinjederSendebotschaftinkrementiert";
CM_ SG_ 982 LH_Aussenlicht_def "Aussenlichtkannnichtmehrkorrektangesteuertwerden(EEPROMCodierungkannnichtmehrausgelesenwerden)
";
CM_ SG_ 982 LH_Standlicht_H_aktiv "Standlichthinten
";
CM_ SG_ 982 LH_Parklicht_HL_aktiv "Parklichthintenlinks
";
CM_ SG_ 982 LH_Parklicht_HR_aktiv "Parklichthintenrechts
";
CM_ SG_ 982 LH_Bremslicht_H_aktiv "Bremslichthinten
";
CM_ SG_ 982 LH_Nebelschluss_aktiv "Nebelschlusslicht
";
CM_ SG_ 982 LH_Rueckfahrlicht_aktiv "Rueckfahrlicht
";
CM_ SG_ 982 LH_Blinker_HL_akt "Blinkerhintenlinks
";
CM_ SG_ 982 LH_Blinker_HR_akt "Blinkerhintenrechts
";
CM_ SG_ 982 LH_Blinker_li_def "FehlerstatusBlinkerhintenlinks
";
CM_ SG_ 982 LH_Bremsl_li_def "FehlerstatusBremslichthintenlinks(DetektionEinzelausfall)
";
CM_ SG_ 982 LH_Schlusslicht_li_def "FehlererkennungSchlusslichthintenlinks
";
CM_ SG_ 982 LH_Rueckf_li_def "FehlererkennungRückfahrlichthintenlinks
";
CM_ SG_ 982 LH_Nebel_li_def "FehlererkennungNebelschlusslichthintenlinks
";
CM_ SG_ 982 LH_Schluss_Brems_Nebel_li_def "Signalwirdgesetzt,wenneineUnterbrechungodereinKurzschlussamLampenausgangfürSchluss_Brems_Nebelschlusslichterkanntwird.";
CM_ SG_ 982 LH_Schluss_Brems_Nebel_re_def "Signalwirdgesetzt,wenneineUnterbrechungodereinKurzschlussamLampenausgangfürSchluss_Brems_Nebelschlusslichterkanntwird.";
CM_ SG_ 982 LH_Zusatzschlussl_def "mindestenseinZusatzschlusslichtinderHeckbeleuchtungdefekt.";
CM_ SG_ 982 LH_Schluss_Brems_li_def "KonfigurationSL+BRL+PLlinksundSL+BRLlinks
";
CM_ SG_ 982 LH_Schluss_Nebel_li_def "KonfigurationSL+NSLlinksoderSL+NSL+PLlinks
";
CM_ SG_ 982 LH_SL_BRL_BLK_li_def "KonfigurationSL+BRL+BLKlinksoderSL+BRL+BLK+PLlinks
";
CM_ SG_ 982 LH_Brems_Blk_li_def "KonfigurationBRL+BLKlinks
";
CM_ SG_ 982 LH_Diag_Status_re_def "AußenlichtDiagnoseSystemstörungrechts";
CM_ SG_ 982 LH_Diag_Status_li_def "AußenlichtDiagnose
Systemstörung links";
CM_ SG_ 982 LH_Diag_LED_li_def "Heckleuchtelinksdefekt";
CM_ SG_ 982 LH_Diag_LED_re_def "Heckleuchterechtsdefekt";
CM_ SG_ 982 LH_Blinker_re_def "FehlerstatusBlinkerhintenrechts
";
CM_ SG_ 982 LH_Bremsl_re_def "FehlerstatusBremslichthintenrechts(DetektionEinzelausfall)
";
CM_ SG_ 982 LH_Schlusslicht_re_def "FehlererkennungSchlusslichthintenrechts
";
CM_ SG_ 982 LH_Rueckf_re_def "FehlererkennungRückfahrlichthintenrechts
";
CM_ SG_ 982 LH_Nebel_re_def "FehlererkennungNebelschlusslichthintenrechts
";
CM_ SG_ 982 LH_Schluss_Brems_mi_def "FehlerstatusSchluss+Bremslichtmittedefekt(DetektionEinzelausfall)";
CM_ SG_ 982 LH_Schluss_Brems_re_def "KonfigurationSL+BRL+PLrechtsundSL+BRLrechts
";
CM_ SG_ 982 LH_Schluss_Nebel_re_def "KonfigurationSL+NSLrechtsoderSL+NSL+PLrechts
";
CM_ SG_ 982 LH_SL_BRL_BLK_re_def "KonfigurationSL+BRL+BLKrechtsoderSL+BRL+BLK+PLrechts
";
CM_ SG_ 982 LH_Brems_Blk_re_def "KonfigurationBRL+BLKrechts
";
CM_ SG_ 982 LH_Kennzl_def "FehlerstatusKennzeichenbeleuchtunghinten
";
CM_ SG_ 982 LH_3_Bremsl_def "Fehlerstatus3.Bremsleuchte
";
CM_ SG_ 982 LH_Nebel_mi_def "FehlererkennungNebelschlusslichthintenMitte


";
CM_ SG_ 982 LH_Rueckf_mi_def "FehlererkennungRückfahrlichtMitte
";
CM_ SG_ 982 LH_Schlusslicht_mi_def "FehlererkennungSchlusslichthintenMitte";
CM_ SG_ 982 LH_Bremsl_li_ges_def "FehlerstatusBremslichthintenlinks(DetektionTotalausfall)
";
CM_ SG_ 982 LH_Bremsl_re_ges_def "FehlerstatusBremslichthintenrechts(DetektionTotalausfall)";
CM_ SG_ 982 LH_Bremsl_mi_def "FehlerstatusBremslichtmitteoderGepäckraumklappe(DetektionEinzelausfall)";
CM_ SG_ 982 BRL_als_SHL "ZeigtanobdasBremslichtalsSchlusslichtimplementiertwird(VarianteNAR)";
CM_ SG_ 134 LWI_01_CRC "FürMLB:
'Berechnung siehe Lastenheft 'Kommunikationsabsicherung für FlexRay und CAN''

Ab MQB und MLBevo:
'Berechnung siehe Lastenheft 'End-to-End Kommunikationsabsicherung'

Endwerte siehe Begleitdokument 'S-PDU Kennungsfolgen'";
CM_ SG_ 134 LWI_QBit_Sub_Daten "EsgiltdieSignalspezifikationlautLAH";
CM_ SG_ 134 LWI_QBit_Lenkradwinkel "DasQBitwirdauchbeinichtabgeglichenemLenkradwinkelsensorgesetzt";
CM_ SG_ 134 LWI_Lenkradwinkel "Wertebereich=+/-800Grad
Auflösung = 0,1 Grad
ACHTUNG: spezifizierte Interne Auflösung des Sensors beträgt aber nur Schrittweite 0,5 Grad!

Hinweis:
MLB: Zusätzlich gestellte Winkel bei Dynamiklenkung beachten !
MQB: Nicht konstante Lenkübersetzu";
CM_ SG_ 134 LWI_VZ_Lenkradwinkel "VorzeichenLenkradwinkelgemässDIN7000";
CM_ SG_ 134 LWI_VZ_Lenkradw_Geschw "VorzeichenLenkradwinkelgeschwindigkeitgemässDIN7000";
CM_ SG_ 134 LWI_Lenkradw_Geschw "Wertebereich=+/-2500Grad/s
Auflösung = 5 Grad/s

Hinweis: Zusätzlich gestellte Winkel bei Dynamiklenkung beachten !";
CM_ SG_ 134 LWI_Sub_Daten "VerschlüsseltesDatenpaketvomSub-RechnerdesLWS,VerwendungnurdurchSCUundESP_ADS
Verwendung gemäß 'Sicherheitsanforderungen an Empfängersteuergeräte'

Im MLB gilt die Signalspezifikation: LAH 8K0953B
Im MLBevo gilt die Signalspezifikation LAH.";
CM_ SG_ 817 MFL_Toggle "WatchdogToggle-Bit";
CM_ SG_ 817 MFL_Lokalaktiv "ZeigtanobdasSGnachKlemme15AUSundnachentsprechenderMAXAktivzeitnochaktivwar";
CM_ SG_ 817 MFL_M_Taste "TasterfürUmschaltungAutomatik/manuellesSchalten(Tiptronic)";
CM_ SG_ 817 MFL_Paddle_Verbau "SignalisiertdenZustanddesTipp-Paddle-Verbaus";
CM_ SG_ 817 MFL_Tastencode_1 "BeschreibtdieFunktioneinerfestzugeordnetenTaste/WalzeaufdemMFL.BeiBetätigungändertsichderWertvon0x0aufdenjeweiligenTastencode.";
CM_ SG_ 817 MFL_Tastencode_2 "BeschreibtdieFunktioneinerfestzugeordnetenTaste/WalzeaufdemMFL.IstMFL_Tastencode_1wegenBetätigungeinerTaste/WalzebereitsmiteinemWertungleich0x0belegt,soändertsichbeiBetätigungeinerweiterenTaste/WalzederWertdiesesSignalsv";
CM_ SG_ 817 MFL_Eventcode_1 "SieheQ-LAHMFL-Protokoll";
CM_ SG_ 817 MFL_Eventcode_2 "SieheQ-LAHMFL-Protokoll";
CM_ SG_ 817 MFL_Variante "MarkenspezifischeVariantennummerdesMFL";
CM_ SG_ 817 MFL_Tip_Down "MFL-TiptronicTastenvomMFLfürGetriebe
0x0 = kein Tip_Down
0x1 = Tip_Down";
CM_ SG_ 817 MFL_Tip_Up "MFL-TiptronicTastenvomMFLfürGetriebe
0x0 = kein Tip_Up
0x1 = Tip_Up";
CM_ SG_ 817 MFL_SatModul_links_Err "SchalterTastermodullinksFehler";
CM_ SG_ 817 MFL_SatModul_rechts_Err "SchalterTastermodulrechtsFehler";
CM_ SG_ 817 MFL_LR_HZG_Status "StatusLenkradheizung";
CM_ SG_ 817 MFL_LR_HZG_Err "LenkradheizungFehler";
CM_ SG_ 817 MFL_Signalhorn "Signalhornnichtbetaetigt/betaetigt";
CM_ SG_ 817 MFL_Signalhorn_Err "SignalhornFehler";
CM_ SG_ 817 MFL_Tip_links_Err "TiptroniclinksFehler";
CM_ SG_ 817 MFL_Tip_rechts_Err "TiptronicrechtsFehler";
CM_ SG_ 817 MFL_Taste_links_Err "MFL_TastenblocklinksFehler";
CM_ SG_ 817 MFL_Taste_rechts_Err "MFL_TastenblockrechtsFehler";
CM_ SG_ 817 MFL_ECU_Err "MFL-µCFehler";
CM_ SG_ 817 MFL_Response_Err "sieheLIN2.0-Specification
(Darf nicht über ein Fehlergueltigkeitsbit abgesichtert werden!)";
CM_ SG_ 15 MO_SOPC "SwitchofPathCheckderMotorsteuerung

Achtung, reines CAN-Signal!";
CM_ SG_ 1600 MO_QBit_Ansaugluft_Temp "
";
CM_ SG_ 1600 MO_QBit_Kuehlmittel_Temp "
";
CM_ SG_ 1600 MO_KL15_Abschaltempfehlung "KessyAbschaltempfehlungnachVerlassendesFahrzeugs";
CM_ SG_ 1600 MO_HYB_Fehler_HV_Netz "ImHV-BordnetzistfehlerbedingtkeingeneratorischerBetriebmöglich.Das12V-BordnetzwirdüberdenDC/DC-WandleralleinausderTraktionsbatteriegespeist.UmdiesenZustandmöglichstlangeaufrechterhaltenzukönnen,solltenKomfort-Verbraucherabgesc";
CM_ SG_ 1600 MO_aktives_Getriebeheizen "InformationfürGetriebe,obeinVentilfürGetriebheizenangesteuertwerdenmuss";
CM_ SG_ 1600 MO_Absperrventil_oeffnen "SignalanKlima-SGdasAbsperrrventilanzusteuern.AbD4auch0x3Ventil_schließen.

Im MQB wird hier der Soll-Status des Absperrventils ausgegeben.
Achtung: bei z. B. klemmendem Ventil entspricht das Signal nicht dem tatsächlichen Status!";
CM_ SG_ 1600 MO_Ansaugluft_Temp "InFahrzeugenohneAußentemperaturvomKombikannausderAnsauglufttemperaturaufdieAußentemperaturgeschlossenwerden.BeimSDIistdasmiteinergewissenGenauigkeitgegeben.GenutztwirdesvomASG.";
CM_ SG_ 1600 MO_Oel_Temp "RealerMeßbereichca.-40..150Grad";
CM_ SG_ 1600 MO_Kuehlmittel_Temp "Kuehlmitteltemperatur";
CM_ SG_ 1600 MO_Hoeheninfo "KorrekturfaktorHöhe(1entspricht1013mbar)";
CM_ SG_ 1600 MO_Kennfeldk "DieKennfeldkühlungistindiesemFahrzeugverbautundhatkeinenSystemfehler";
CM_ SG_ 1600 MO_Versionsinfo_02 "VersioninformationvomMotorzurSteuerungbeiinkompatiblenKMatrix-Änderungbzw.EinführungvonneuenFunktionen,dieindenEmpfängernverriegeltwerdenmüssen.ZujedemEreigniswirdeinfixerZählerstandzugeordnet,umdemEmpfängerdiefunktionaleÄ";
CM_ SG_ 1600 MO_QBit_Hoeheninfo "QualifizierungsbitderHöheninfo.GesetztbeiErsatzwert,InitoderFehler.";
CM_ SG_ 1600 MO_Getriebe_kuehlen "AnforderungGetriebekühlventilansteuerung";
CM_ SG_ 1600 MO_Mom_Traegheit_02 "Massenträgheit(J)derMotorsbzw.derAntriebsmaschineninkgm².

Zur Berücksichtigung des E-Motor in Hybrid-Projekten:
in MLB-Projekten wird nur der J-Wert des Verbrennungsmotors und nicht der J-Wert des E-Motors berücksichtigt.
In MQB/MLBevo-Projek";
CM_ SG_ 1600 MO_Heizungspumpenansteuerung "AnforderungHeizungspumpenansteuerung
MQB und Hybrid: Status der Heizungsunterstützungspumpe am MSG
";
CM_ SG_ 1600 MO_SpannungsAnf "ForderungdesMotor-SGszurSpannungsanhebung";
CM_ SG_ 1600 MO_Nachlaufzeit_Heizungspumpe "NachlaufzeitfürHeizungspumpefürTurboladerschutz";
CM_ SG_ 167 Motor_11_CRC "FürMLB:
'Berechnung siehe Lastenheft 'Kommunikationsabsicherung für FlexRay und CAN''

Ab MQB und MLBevo:
'Berechnung siehe Lastenheft 'End-to-End Kommunikationsabsicherung''

Endwerte siehe Begleitdokument 'S-PDU Kennungsfolgen'";
CM_ SG_ 167 MO_Mom_Soll_Roh "EinheitenloserWert!FaktorinMO_Faktor_Momente_02inMotor_Code_01beachten!

Momentenanforderung aus Fahrpedal bzw. von ACC/GRA bzw. aus dem Leerlaufregler (quasistatischer Anteil) bzw. aus Rekuperationsanforderung; keine Begrenzungen, keine Filterun";
CM_ SG_ 167 MO_Mom_Ist_Summe "EinheitenloserWert!FaktorinMO_Faktor_Momente_02inMotor_Code_01beachten!

Ist-Moment als Summe aus Verbrennungsmotor und E-Motor (bei Hybrid-Konzepten) incl. allen Eingriffen und Korrekturen

In Fahrzeugen mit einer Antriebsachse bzw. mit mechan";
CM_ SG_ 167 MO_Mom_Traegheit_Summe "EinheitenloserWert!FaktorinMO_Faktor_Momente(CANV6.x)bzw.MO_Faktor_Momente_02(CANV7.x)inMotor_Code_01beachten!

Moment, das zur Beschleunigung der trägen Massen aufgewendet wird bzw. frei wird; Summen aus Anteilen für Verbrennungsmotor und ";
CM_ SG_ 167 MO_Mom_Soll_gefiltert "EinheitenloserWert!FaktorinMO_Faktor_Momente_02inMotor_Code_01beachten!

MO_Mom_Soll_Roh nach Fahrverhaltensfilter, begrenzt nach oben mit MO_Mom_Begr_dyn, Einrechnung der plausibilisierten Bremsen-Eingriffe; ohne Getriebe-Schalt-Eingriffe, ohne ";
CM_ SG_ 167 MO_Mom_Schub "EinheitenloserWert!FaktorinMO_Faktor_Momente_02inMotor_Code_01beachten!

Moment das sich einstellt, wenn der Fahrer 0% Fahrpedal gibt; bei konventionellen Projekten = alle Verluste (mechanische Reibung und sonstige Verluste) des Verbrennungsmotor";
CM_ SG_ 167 MO_Status_Normalbetrieb_01 "DasMotorsteuergerätsendetdasInformationsbit,wenndieInitialisierungsphasedesSteuergerätesabgeschlossenist.ZusätzlichmussdieKlemme15eingeschaltenseinundeineapplizierbareMindestdrehzahlschwelle(KennlinieinAbh.vonderKühlwassertempe";
CM_ SG_ 167 MO_erste_Ungenauschwelle "ZusätzlicheUngenauigkeit(zurGrundungenauigkeit).Motormomenteungenau>8%(kleinsteUngenauschwelle)
";
CM_ SG_ 167 MO_QBit_Motormomente "AUDID4:Zykluszeit:10ms(sieheZykluszeitschnell/CycletimeFast)

Ungenaue Momentenangaben, weil die Momente aus Ersatzwerten berechnet wurden (z.B. HFM ausgefallen). Qualifizierungsbit für die Motormomente.

Achtung:
Reduktion der Zykluszeit Moto";
CM_ SG_ 168 Motor_12_CRC "FürMLB:
'Berechnung siehe Lastenheft 'Kommunikationsabsicherung für FlexRay und CAN''

Ab MQB und MLBevo:
'Berechnung siehe Lastenheft 'End-to-End Kommunikationsabsicherung'

Endwerte siehe Begleitdokument 'S-PDU Kennungsfolgen'";
CM_ SG_ 168 MO_Mom_neg_verfuegbar "EinheitenloserWert!FaktorinMO_Faktor_Momente(CANV6.x)bzw.MO_Faktor_Momente_02(CANV7.x)inMotor_Code_01beachten!

Bei aktueller Drehzahl im nächsten Task (bei CAN-Übertragung z.B. 10ms) tatsächlich verfügbares negatives Moment (Summe aus Verl";
CM_ SG_ 168 MO_Mom_Begr_Fahr "EinheitenloserWert!FaktorinMO_Faktor_Momente(CANV6.x)bzw.MO_Faktor_Momente_02(CANV7.xundhöher)inMotor_Code_01beachten!

Bei aktueller Drehzahl quasistationär (nach ca. 3…5 s) max. mögliches Getriebeeingangsmoment (Summe aus Verbrennungsmo";
CM_ SG_ 168 MO_Mom_Begr_Schalt "EinheitenloserWert!FaktorinMO_Faktor_Momente(CANV6.x)bzw.MO_Faktor_Momente_02(CANV7.x/8.x)inMotor_Code_01beachten!

Bei aktueller Drehzahl kurzfristig (ca. 100..200 ms) für momentenerhöhende Getriebeeingriffe max. zur Verfügung stehendes Ge";
CM_ SG_ 168 MO_Momentenintegral_02 "100%entsprichtvolleVerfügbarkeitaktuellvorhanden.0%entsprichtIntegralbisLimitgefüllt,erhöhenderEingriffkannaktuellnichtberücksichtigtwerdenoderaufgrundeinesFehlersnichtverfügbar
";
CM_ SG_ 168 MO_QBit_Drehzahl_01 "AUDID4:Zykluszeit:10ms(sieheZykluszeitschnell/CycletimeFast)

Achtung:
Reduktion der Zykluszeit Motor_03 auf 10ms geplant.
Projektabhängig soll künftig mit 10ms gesendet werden.
Empfänger die in weiteren Konzern-Projekten eingesetzt werden müs";
CM_ SG_ 168 MO_Drehzahl_01 "ImFehlerfallwirddieMotordrehzahlüberdieNockenwellendrehzahlalsErsatzgrösseausgegeben

Bei Parallelhybrid: Getriebeeingangsdrehzahl (=E-Maschinen Drehzahl)

Hinweis:
Ehemaliger Fehlerwert 0xFFFF wird senderseitig nicht unterstützt.
Diesen";
CM_ SG_ 958 Motor_14_CRC "AbMQBundMLBevo:
'Berechnung siehe Lastenheft 'End-to-End Kommunikationsabsicherung'

Endwerte siehe Begleitdokument 'S-PDU Kennungsfolgen'";
CM_ SG_ 958 MO_StartStopp_Status "AktivitätsstatusStart/Stopp-Koordinator
HYBRID:
Wenn MO_Hybridfahrzeug = 1 gilt:
Signal bezieht sich nur auf den Verbrennungsmotor, nicht auf den Hybridantrieb
";
CM_ SG_ 958 MO_StartStopp_Wiederstart "MotorwiederstartdurchStart/Stopp-Koordinator
HYBRID:
Wenn MO_Hybridfahrzeug =1 gilt:
Warnung vor Spannungseinbruch beim Zustart des Verbrennungsmotors.
-nicht relevant, da derzeit kein Start über 12V-Starter geplant-
Dieses Signal wird nur vom Hyb";
CM_ SG_ 958 MO_StartStopp_Motorstopp "Motor-StoppdurchStart/Stopp-Koordinator
HYBRID:
Wenn MO_Hybridfahrzeug = 1 gilt:
Verbrennungsmotor durch Hybrid-Koordinator im MSG ausgeschaltet.
Die definierten Start/Stopp-Signale beziehen sich nur auf den Verbrennungsmotor!";
CM_ SG_ 958 MO_Freig_Reku "EmpfehlungdesMotor-SG'szurSpannungsabsenkung/-anhebungfürdenRekuperationsbetrieb";
CM_ SG_ 958 MO_Kl_75 "KlemmeX
";
CM_ SG_ 958 MO_Kl_50 "Klemme50:StartausführungdurchRitzelstarter

MLB: nicht von allen Motoren gesendet
MQB/MLBevo: gesendet von allen Motoren";
CM_ SG_ 958 MO_Gangposition "MLB:
Stellung des Wählhebels in der Schaltgasse des Handschaltgetriebes.
MLBevo:
Ausweitung der Bedienung auch auf Automatikgetrieb";
CM_ SG_ 958 MO_StartStopp_Fahrerwunsch "FahreraktivitätStart/Stop";
CM_ SG_ 958 MO_HYB_Fahrbereitschaft "Signalsteuertu.a.inderLenkhilfezusammenmitweiterenInformationendenModewechselinden'Drivemode'
Grüne Anzeige im Kombiinstrument zur Signalisierung der Bereitschaft des Hybridsystems.";
CM_ SG_ 958 MO_Ext_E_Fahrt_aktiv "Funktionsrückmeldungzumerw.E-Fahr-BetriebüberLampe/LEDimE-Mode-Taster";
CM_ SG_ 958 MO_Fahrer_bremst "RedundanteBremsinformationvomMotor.

MLB:
AUDI D4: Zykluszeit: 10ms (siehe Zykluszeit schnell/Cycletime Fast)
Im AUDI B8 wird in diesem Bit der Wert der ESP-CAN-Information 'ESP_Fahrer_bremst' ausgegeben.

Achtung:
Reduktion der Zykluszeit Motor";
CM_ SG_ 958 MO_QBit_Fahrer_bremst "MLB:
AUDI D4: Zykluszeit: 10ms (siehe Zykluszeit schnell/Cycletime Fast)

Achtung:
Reduktion der Zykluszeit Motor_03 auf 10ms geplant.
Projektabhängig soll künftig mit 10ms gesendet werden.
Empfänger die in weiteren Konzern-Projekten eingesetzt werd";
CM_ SG_ 958 MO_BLS "UngefiltertesRohsignaldesBremslichtschalters,nurwennHW-Eingangbestücktundausgewertetwird.BeiMotorenohnegenutztenHW-EingangwirdkeinErsatzwert(bspw.SW-SignalüberCAN)ausgegeben!
Bei AUDI muss das Signal wg. Bremslichtfunktion immer be";
CM_ SG_ 958 MO_Konsistenz_Bremsped "MLB:

AUDI D4: Zykluszeit: 10ms (siehe Zykluszeit schnell/Cycletime Fast)
Siehe 'Funktionsspezifikation Bremslichtinfo B8'

Achtung:
Reduktion der Zykluszeit Motor_03 auf 10ms geplant.
Projektabhängig soll künftig mit 10ms gesendet werden.
Empfäng";
CM_ SG_ 958 MO_Timeout_ESP "500msTimeoutaufBremsen-Botschaftist>=1malaufgelaufen,LöschendesBitsnachNeustart(KL15).

MLB:
AUDI D4: Zykluszeit: 10ms (siehe Zykluszeit schnell/Cycletime Fast)

Achtung:
Reduktion der Zykluszeit Motor_03 auf 10ms geplant.
Projektabh";
CM_ SG_ 958 MO_Klima_Eingr "EingriffedesMotorbeiderKlima";
CM_ SG_ 958 MO_Aussp_Anlass "DasSignalzeigtan,obdieWiederholstartsperreaktivist.D.h.eineAnsteuerungdesAnlasserswirdauchbeierfülltenStartvoraussetzungen(HS:Interlockbetätigtbzw.AT:P/NeingelegtundBremsebetätigt)nichterfolgen.";
CM_ SG_ 958 MO_Freig_Anlass "Bitwirdgesetzt,wennderMotorbeimAutomatikstartgestartetwerdendarf(Motorstillstand,Emissionsmaßnahmensinderfüllt).";
CM_ SG_ 958 MO_Kuppl_schalter "MLB:
Das Motorsteuergerät gibt die Information aus, ab wann der Kupplungsschalter durch das Motorsteuergerät als getreten gesehen wird
0x0: Schalter sagt betätigt (Ausgekuppelt)
0x1: Schalter sagt nicht betätigt (Eingekuppelt)

MQB:
Nur Handschalter";
CM_ SG_ 958 MO_Interlock "DasMotorsteuergerätgibtdieInformationaus,abwannderKupplungsschalterdurchdasMotorsteuergerätalsgetretengesehenwird.
Bei Systemen für Start Stopp muss das Interlocksignal für einen Start durch das MSG generiert werden, sobald der Schalthebe";
CM_ SG_ 958 MO_Motor_laeuft "DasMotorsteuergerätgibtdieInformationaus,abwannderMotorverbrennungsbedingtautarkläuftunddurchzuschaltbareNebenaggregatemechanischbelastbarist(z.B.durchGenerator,Klimakompressor,etc.).

Die 'Motor läuft' Information wird ausgegebe";
CM_ SG_ 958 MO_Kickdown "Esgilt:SignalspecMO_Kickdownv1.0";
CM_ SG_ 958 MO_QBit_KL_75 "Q-BitfürdasKL75SignalzurVermeidungderfehlerhaftenErkennungvonMotorstarts.
Wird auf 1 gesetzt, solange das Motorsteuergerät KL15 = AUS erkannt hat.";
CM_ SG_ 958 MO_EKlKomLeiRed "AnforderungandieKlimasteuerung,dieLeistungsaufnahmedesE-KompressorsbeischlechtemSOCundinbestimmtenFahrsituationenzubegrenzen.(DasbereitsbestehendeSignal'Klimakompressoraus'alsstetsumzusetzendeAnforderungbleibtunverändertbesteh";
CM_ SG_ 958 MO_Handshake_STH "Esgilt:SignalspecMO_Handshakev1.0

Handshake zwischen MSG und STH. Wenn das MSG die EKP aufgrund einer STH-Anforderung ansteuert und kein Fehlereintrag bzgl. EKP/KPE/NDR vorliegt, wird das Bit gesetzt.";
CM_ SG_ 958 MO_BKV_Unterdruckwarnung "ÜberdieUnterdruckwarnungsignalisiertdasMSGdemESP,dasskeinausreichenderUnterdruckfürdenBKVzurVerfügunggestelltwerdenkann.";
CM_ SG_ 958 MO_Freigabe_Segeln "FreigabebitdesSegelbetriebsimGetriebe.BedingtdurchbestimmteDiagnosenundAdaptionendesMSGs,dienurimSchubmöglichsind,darfnichtjedeSchubphasefüreinenSegelbetriebgenutztwerden.EineFreigabebleibtauchaußerhalbeinerSchubphasebes";
CM_ SG_ 958 MO_PTC_Status "Status-RückmeldungvomMSGzumaktuellenPTC-Status(stufigesPTC,RelaisamMSG).BeiAnsteuerungeinesstufigenPTCdurcheinanderesSGbeschreibtdasSignaldievomMSGfreigegebenePTC-Stufe.";
CM_ SG_ 958 MO_QBit_Gangposition "QualitätsbitzumSignalMO_Gangposition";
CM_ SG_ 958 MO_Signalquelle_Gangposition "SignalquelledesSignalsMO_Gangposition
0: Signalquelle Gangpositionssensor
1: Signalquelle Modellwert (v/n)";
CM_ SG_ 958 MO_Remotestart_Betrieb "DasMSGistfürdenRemotestart-Betriebbereit.NachEmpfangderMotorstartanforderungfürRSt-BetriebdurchBCMwirdderFahrzeugmotorgestartetundsolangederMotorläuft,bleibtdiesesBitaktiv.DiesesSignalistnurzurVerwendungdurchdasBCMzur";
CM_ SG_ 958 MO_Remotestart_moeglich "WennBitgesetzt,würdedasMSGbeientsprechenderAnforderungdurchdasBCMdenRemotestartbetriebeinleiten,d.h.dasMSGistremotestartfähigundesliegenaktuellkeinerelevantenFehleroderandereAbbruchgründevor.";
CM_ SG_ 958 MO_FMAus_aktiv "DasSignalgibtRückmeldungobFreilaufMotorausaktivist.Beleibtauch0km/h(unterhalbderStartStoppSchwelle)weiterhinaktiv.";
CM_ SG_ 958 MO_FMAus_Startvariante "StartvariantebeimMotorstartausderFreilauf-Motor-AUSPhase";
CM_ SG_ 958 MO_BMS_NV_Anf_stuetzen "GarantierteUnterstützungdesZusatzspeichersisterforderlich.ZusatzspeichermussandasVersorgungsneztangebundenwerden.";
CM_ SG_ 958 MO_Zylinderabschaltung "StatusZylinderabschaltungMotor";
CM_ SG_ 958 MO_HYB_VM_aktiv "0=VMotorwirdnichtaktivgehalten(nVM<n_minundkeineLL-Regelungaktiv)
1 = VMotor aktiv (ab der ersten Einspritzung; gilt auch für Schubbetrieb, wenn VMotor spätestens durch LLRegelung befeuert würde)
Verwendet zur Bestimmung des Ist-Zustandes";
CM_ SG_ 958 MO_StartVorauss_erfuellt "DientderFallunterscheidungbeiZAT-BetätigungimZustand'KL15ein'(beinichtgesetztemSignalfolgtKL15aus,beigesetztemSignalfolgtsetzenKL50-Anf.)

0: Signal nicht bedient
1: Voraussetzungen zur Antriebsstrangaktivierung / Startvoraussetzu";
CM_ SG_ 1631 TSK_Grundmasse "Fahrzeuggrundmasseinkg.DasSignaldientderAnpassungderSollbeschleunigungvomACC

Hinweis: Ehemaliger Fehlerwert 0x7F wird senderseitig nicht unterstützt. Diesen Wert aus Kompatibilitätsgründen nicht neu belegen!";
CM_ SG_ 1631 MO_SpannungsAnf_02 "ForderungdesMotor-SG'szurSpannungsanhebung";
CM_ SG_ 1631 MO_DPF_reg "RegenerationDiesel-Partikel-Filter";
CM_ SG_ 1631 MO_Heizstrom_EKAT "AktuelleGesamtstromaufnahmedesE-Katalysators";
CM_ SG_ 1631 MO_Heizstrom_SCR "AktuelleGesamtstromaufnahmederTank-,Fördermodul-undLeitungsheizungdesSCR-Systems";
CM_ SG_ 1631 MO_P_Generator_ungefiltert_Anf "BeiEmpfangderAnforderungsollderSenderBEM_P_Generatorungefiltertbefüllen.";
CM_ SG_ 1631 MO_Energieinhalt_BMS "RestenergieinhaltderTraktionsbatterie,beeinflusstdurchFahrstrategieundweiterenFaktorenderAntriebssteuerung.";
CM_ SG_ 1631 TSK_Fahrzeugmasse_02 "NeueDefinitionabD4
Fahrzeugmasse in kg. Das Signal dient der Anpassung der Sollbeschleunigung vom ACC


";
CM_ SG_ 1631 TSK_Steigung_02 "Steigungin%Berg.DasSignaldientderAnpassungderSollbeschleunigungvomACC

Positive Werte > bergau";
BA_DEF_ BO_ "DiagRequest" ENUM "No", "Yes";
BA_DEF_ BO_ "DiagResponse" ENUM "No", "Yes";
BA_DEF_ BO_ "DiagState" ENUM "No", "Yes";
BA_DEF_ BO_ "GenMsgChkConstant" HEX 0 4095;
BA_DEF_ BO_ "GenMsgCycleTime" INT 0 65535;
BA_DEF_ BO_ "GenMsgCycleTimeFast" INT 0 65535;
BA_DEF_ BO_ "GenMsgDelayTime" INT 0 100000;
BA_DEF_ BO_ "GenMsgILSupport" ENUM "No", "Yes";
BA_DEF_ BO_ "GenMsgNrOfRepetition" INT 0 100;
BA_DEF_ BO_ "GenMsgPDUConstants" STRING;
BA_DEF_ BO_ "GenMsgSendType" ENUM "Cyclic", "not_used", "not_used", "not_used", "not_used", "not_used", "not_used", "IfActive", "NoMsgSendType";
BA_DEF_ BO_ "GenMsgStartDelayTime" INT 0 100000;
BA_DEF_ BO_ "NmMessage" ENUM "No", "Yes";
BA_DEF_ BO_ "NmhMessage" ENUM "No", "Yes";
BA_DEF_ BO_ "MsgType" ENUM "Application", "NM", "NMH", "TP2.0", "ISO-TP", "BAP", "EID", "KS";
BA_DEF_ BO_ "VAGTP20_API" HEX 0 255;
BA_DEF_ BO_ "VAGTP20_DynConnection" ENUM "No", "Yes";
BA_DEF_ BO_ "VAGTP20_DynSetup" ENUM "No", "Yes";
BA_DEF_ BO_ "VAGTP20_StatConnection" ENUM "No", "Yes";
BA_DEF_ BO_ "CANFD_BRS" ENUM "0", "1";
BA_DEF_ BO_ "VFrameFormat" ENUM "StandardCAN", "ExtendedCAN", "reserved", "reserved", "reserved", "reserved", "reserved", "reserved", "reserved", "reserved", "reserved", "reserved", "reserved", "reserved", "StandardCAN_FD", "ExtendedCAN_FD";
BA_DEF_ SG_ "GenSigActiveRepetitions" INT -2147483648 2147483647;
BA_DEF_ SG_ "GenSigInactiveValue" INT -2147483648 2147483647;
BA_DEF_ SG_ "GenSigSendType" ENUM "Cyclic", "OnWrite", "OnWriteWithRepetition", "OnChange", "OnChangeWithRepetition", "IfActive", "IfActiveWithRepetition", "NoSigSendType", "OnChangeAndIfActive", "OnChangeAndIfActiveWithRepetition";
BA_DEF_ SG_ "GenSigStartValue" INT -2147483648 2147483647;
BA_DEF_ SG_ "NWM-WakeupAllowed" ENUM "No", "Yes";
BA_DEF_ SG_ "GenSigFuncType" ENUM "NoFunction", "MsgCounter", "CRC-8", "XOR", "XOR-2", "DatedBit", "SW-Kl15", "CHK", "Constant", "Protocol", "CRC-8-SAE_J1850";
BA_DEF_ SG_ "GenSigSwitchedByIgnition" ENUM "No", "Yes";
BA_DEF_ SG_ "Fehlerwert" HEX 0 2147483647;
BA_DEF_ SG_ "GenSigMissingSourceValue" HEX 0 2147483647;
BA_DEF_DEF_  "DiagRequest" "No";
BA_DEF_DEF_  "DiagResponse" "No";
BA_DEF_DEF_  "DiagState" "No";
BA_DEF_DEF_  "GenMsgChkConstant" 0;
BA_DEF_DEF_  "GenMsgCycleTime" 0;
BA_DEF_DEF_  "GenMsgCycleTimeFast" 0;
BA_DEF_DEF_  "GenMsgDelayTime" 0;
BA_DEF_DEF_  "GenMsgILSupport" "No";
BA_DEF_DEF_  "GenMsgNrOfRepetition" 0;
BA_DEF_DEF_  "GenMsgPDUConstants" "";
BA_DEF_DEF_  "GenMsgSendType" "NoMsgSendType";
BA_DEF_DEF_  "GenMsgStartDelayTime" 0;
BA_DEF_DEF_  "NmMessage" "No";
BA_DEF_DEF_  "NmhMessage" "No";
BA_DEF_DEF_  "MsgType" "Application";
BA_DEF_DEF_  "VAGTP20_API" 0;
BA_DEF_DEF_  "VAGTP20_DynConnection" "No";
BA_DEF_DEF_  "VAGTP20_DynSetup" "No";
BA_DEF_DEF_  "VAGTP20_StatConnection" "No";
BA_DEF_DEF_  "CANFD_BRS" "1";
BA_DEF_DEF_  "VFrameFormat" "StandardCAN";
BA_DEF_DEF_  "GenSigActiveRepetitions" 0;
BA_DEF_DEF_  "GenSigInactiveValue" 0;
BA_DEF_DEF_  "GenSigSendType" "NoSigSendType";
BA_DEF_DEF_  "GenSigStartValue" 0;
BA_DEF_DEF_  "NWM-WakeupAllowed" "No";
BA_DEF_DEF_  "GenSigFuncType" "NoFunction";
BA_DEF_DEF_  "GenSigSwitchedByIgnition" "Yes";
BA_DEF_DEF_  "Fehlerwert" 0;
BA_DEF_DEF_  "GenSigMissingSourceValue" 0;
BA_ "GenMsgCycleTime" BO_ 2527679583 1000;
BA_ "GenMsgCycleTimeFast" BO_ 2527679583 100;
BA_ "GenMsgDelayTime" BO_ 2527679583 50;
BA_ "GenMsgILSupport" BO_ 2527679583 "Yes";
BA_ "GenMsgNrOfRepetition" BO_ 2527679583 5;
BA_ "GenMsgSendType" BO_ 2527679583 "Cyclic";
BA_ "VFrameFormat" BO_ 2527679583 "ExtendedCAN_FD";
BA_ "DiagRequest" BO_ 1813 "Yes";
BA_ "MsgType" BO_ 1813 "ISO-TP";
BA_ "VFrameFormat" BO_ 1813 "StandardCAN_FD";
BA_ "DiagResponse" BO_ 1919 "Yes";
BA_ "MsgType" BO_ 1919 "ISO-TP";
BA_ "VFrameFormat" BO_ 1919 "StandardCAN_FD";
BA_ "DiagState" BO_ 1792 "Yes";
BA_ "MsgType" BO_ 1792 "ISO-TP";
BA_ "VFrameFormat" BO_ 1792 "StandardCAN_FD";
BA_ "DiagRequest" BO_ 2621440021 "Yes";
BA_ "MsgType" BO_ 2621440021 "ISO-TP";
BA_ "VFrameFormat" BO_ 2621440021 "ExtendedCAN_FD";
BA_ "DiagResponse" BO_ 2621571093 "Yes";
BA_ "MsgType" BO_ 2621571093 "ISO-TP";
BA_ "VFrameFormat" BO_ 2621571093 "ExtendedCAN_FD";
BA_ "DiagRequest" BO_ 2549874812 "Yes";
BA_ "MsgType" BO_ 2549874812 "ISO-TP";
BA_ "VFrameFormat" BO_ 2549874812 "ExtendedCAN_FD";
BA_ "DiagRequest" BO_ 2621440124 "Yes";
BA_ "MsgType" BO_ 2621440124 "ISO-TP";
BA_ "VFrameFormat" BO_ 2621440124 "ExtendedCAN_FD";
BA_ "DiagResponse" BO_ 2550005884 "Yes";
BA_ "MsgType" BO_ 2550005884 "ISO-TP";
BA_ "VFrameFormat" BO_ 2550005884 "ExtendedCAN_FD";
BA_ "DiagResponse" BO_ 2621571196 "Yes";
BA_ "MsgType" BO_ 2621571196 "ISO-TP";
BA_ "VFrameFormat" BO_ 2621571196 "ExtendedCAN_FD";
BA_ "DiagRequest" BO_ 2549874872 "Yes";
BA_ "MsgType" BO_ 2549874872 "ISO-TP";
BA_ "VFrameFormat" BO_ 2549874872 "ExtendedCAN_FD";
BA_ "DiagRequest" BO_ 2621440184 "Yes";
BA_ "MsgType" BO_ 2621440184 "ISO-TP";
BA_ "VFrameFormat" BO_ 2621440184 "ExtendedCAN_FD";
BA_ "DiagResponse" BO_ 2550005944 "Yes";
BA_ "MsgType" BO_ 2550005944 "ISO-TP";
BA_ "VFrameFormat" BO_ 2550005944 "ExtendedCAN_FD";
BA_ "DiagResponse" BO_ 2621571256 "Yes";
BA_ "MsgType" BO_ 2621571256 "ISO-TP";
BA_ "VFrameFormat" BO_ 2621571256 "ExtendedCAN_FD";
BA_ "DiagState" BO_ 2621505536 "Yes";
BA_ "MsgType" BO_ 2621505536 "ISO-TP";
BA_ "VFrameFormat" BO_ 2621505536 "ExtendedCAN_FD";
BA_ "DiagRequest" BO_ 2549874806 "Yes";
BA_ "MsgType" BO_ 2549874806 "ISO-TP";
BA_ "VFrameFormat" BO_ 2549874806 "ExtendedCAN_FD";
BA_ "DiagRequest" BO_ 2621440118 "Yes";
BA_ "MsgType" BO_ 2621440118 "ISO-TP";
BA_ "VFrameFormat" BO_ 2621440118 "ExtendedCAN_FD";
BA_ "DiagResponse" BO_ 2550005878 "Yes";
BA_ "MsgType" BO_ 2550005878 "ISO-TP";
BA_ "VFrameFormat" BO_ 2550005878 "ExtendedCAN_FD";
BA_ "DiagResponse" BO_ 2621571190 "Yes";
BA_ "MsgType" BO_ 2621571190 "ISO-TP";
BA_ "VFrameFormat" BO_ 2621571190 "ExtendedCAN_FD";
BA_ "GenMsgCycleTime" BO_ 2527679684 2000;
BA_ "GenMsgDelayTime" BO_ 2527679684 100;
BA_ "GenMsgILSupport" BO_ 2527679684 "Yes";
BA_ "GenMsgSendType" BO_ 2527679684 "Cyclic";
BA_ "VFrameFormat" BO_ 2527679684 "ExtendedCAN_FD";
BA_ "GenMsgChkConstant" BO_ 960 195;
BA_ "GenMsgCycleTime" BO_ 960 100;
BA_ "GenMsgDelayTime" BO_ 960 10;
BA_ "GenMsgILSupport" BO_ 960 "Yes";
BA_ "GenMsgPDUConstants" BO_ 960 "0xc3,0xc3,0xc3,0xc3,0xc3,0xc3,0xc3,0xc3,0xc3,0xc3,0xc3,0xc3,0xc3,0xc3,0xc3,0xc3";
BA_ "GenMsgSendType" BO_ 960 "Cyclic";
BA_ "VFrameFormat" BO_ 960 "StandardCAN_FD";
BA_ "GenMsgCycleTime" BO_ 2463978753 1000;
BA_ "GenMsgCycleTimeFast" BO_ 2463978753 100;
BA_ "GenMsgDelayTime" BO_ 2463978753 100;
BA_ "GenMsgILSupport" BO_ 2463978753 "Yes";
BA_ "GenMsgNrOfRepetition" BO_ 2463978753 5;
BA_ "GenMsgSendType" BO_ 2463978753 "Cyclic";
BA_ "VFrameFormat" BO_ 2463978753 "ExtendedCAN_FD";
BA_ "GenMsgCycleTime" BO_ 1420 1000;
BA_ "GenMsgCycleTimeFast" BO_ 1420 20;
BA_ "GenMsgDelayTime" BO_ 1420 10;
BA_ "GenMsgILSupport" BO_ 1420 "Yes";
BA_ "GenMsgNrOfRepetition" BO_ 1420 5;
BA_ "GenMsgPDUConstants" BO_ 1420 "0x9b,0xb5,0x9d,0x06,0x01,0xe7,0x8f,0xc1,0xd0,0x10,0x47,0xe9,0xd3,0xca,0x05,0xf0";
BA_ "GenMsgSendType" BO_ 1420 "Cyclic";
BA_ "VFrameFormat" BO_ 1420 "StandardCAN_FD";
BA_ "GenMsgCycleTime" BO_ 949 100;
BA_ "GenMsgILSupport" BO_ 949 "Yes";
BA_ "GenMsgSendType" BO_ 949 "Cyclic";
BA_ "VFrameFormat" BO_ 949 "StandardCAN_FD";
BA_ "GenMsgCycleTime" BO_ 1511 200;
BA_ "GenMsgILSupport" BO_ 1511 "Yes";
BA_ "GenMsgSendType" BO_ 1511 "Cyclic";
BA_ "VFrameFormat" BO_ 1511 "StandardCAN_FD";
BA_ "GenMsgCycleTime" BO_ 1505 200;
BA_ "GenMsgILSupport" BO_ 1505 "Yes";
BA_ "GenMsgSendType" BO_ 1505 "Cyclic";
BA_ "VFrameFormat" BO_ 1505 "StandardCAN_FD";
BA_ "GenMsgCycleTime" BO_ 2549088277 500;
BA_ "GenMsgILSupport" BO_ 2549088277 "Yes";
BA_ "GenMsgSendType" BO_ 2549088277 "Cyclic";
BA_ "CANFD_BRS" BO_ 2549088277 "0";
BA_ "VFrameFormat" BO_ 2549088277 "ExtendedCAN";
BA_ "GenMsgCycleTime" BO_ 2549088380 500;
BA_ "GenMsgILSupport" BO_ 2549088380 "Yes";
BA_ "GenMsgSendType" BO_ 2549088380 "Cyclic";
BA_ "VFrameFormat" BO_ 2549088380 "ExtendedCAN_FD";
BA_ "GenMsgCycleTime" BO_ 2549088272 500;
BA_ "GenMsgILSupport" BO_ 2549088272 "Yes";
BA_ "GenMsgSendType" BO_ 2549088272 "Cyclic";
BA_ "VFrameFormat" BO_ 2549088272 "ExtendedCAN_FD";
BA_ "GenMsgCycleTime" BO_ 2549088440 500;
BA_ "GenMsgILSupport" BO_ 2549088440 "Yes";
BA_ "GenMsgSendType" BO_ 2549088440 "Cyclic";
BA_ "VFrameFormat" BO_ 2549088440 "ExtendedCAN_FD";
BA_ "GenMsgCycleTime" BO_ 2549088374 500;
BA_ "GenMsgILSupport" BO_ 2549088374 "Yes";
BA_ "GenMsgSendType" BO_ 2549088374 "Cyclic";
BA_ "VFrameFormat" BO_ 2549088374 "ExtendedCAN_FD";
BA_ "MsgType" BO_ 2621440277 "ISO-TP";
BA_ "VFrameFormat" BO_ 2621440277 "ExtendedCAN_FD";
BA_ "MsgType" BO_ 2621571349 "ISO-TP";
BA_ "VFrameFormat" BO_ 2621571349 "ExtendedCAN_FD";
BA_ "GenMsgCycleTime" BO_ 982 100;
BA_ "GenMsgDelayTime" BO_ 982 20;
BA_ "GenMsgILSupport" BO_ 982 "Yes";
BA_ "GenMsgSendType" BO_ 982 "Cyclic";
BA_ "VFrameFormat" BO_ 982 "StandardCAN_FD";
BA_ "GenMsgChkConstant" BO_ 134 134;
BA_ "GenMsgCycleTime" BO_ 134 5;
BA_ "GenMsgILSupport" BO_ 134 "Yes";
BA_ "GenMsgPDUConstants" BO_ 134 "0x86,0x86,0x86,0x86,0x86,0x86,0x86,0x86,0x86,0x86,0x86,0x86,0x86,0x86,0x86,0x86";
BA_ "GenMsgSendType" BO_ 134 "Cyclic";
BA_ "VFrameFormat" BO_ 134 "StandardCAN_FD";
BA_ "GenMsgCycleTime" BO_ 817 500;
BA_ "GenMsgCycleTimeFast" BO_ 817 30;
BA_ "GenMsgILSupport" BO_ 817 "Yes";
BA_ "GenMsgSendType" BO_ 817 "Cyclic";
BA_ "VFrameFormat" BO_ 817 "StandardCAN_FD";
BA_ "GenMsgCycleTimeFast" BO_ 15 10;
BA_ "GenMsgILSupport" BO_ 15 "Yes";
BA_ "GenMsgSendType" BO_ 15 "IfActive";
BA_ "VFrameFormat" BO_ 15 "StandardCAN_FD";
BA_ "GenMsgCycleTime" BO_ 1600 500;
BA_ "GenMsgILSupport" BO_ 1600 "Yes";
BA_ "GenMsgSendType" BO_ 1600 "Cyclic";
BA_ "VFrameFormat" BO_ 1600 "StandardCAN_FD";
BA_ "GenMsgCycleTime" BO_ 167 10;
BA_ "GenMsgILSupport" BO_ 167 "Yes";
BA_ "GenMsgPDUConstants" BO_ 167 "0xd2,0x3d,0xcd,0x28,0x4c,0x14,0x22,0x4b,0x24,0xac,0xfa,0x55,0x66,0x80,0x0d,0x6c";
BA_ "GenMsgSendType" BO_ 167 "Cyclic";
BA_ "VFrameFormat" BO_ 167 "StandardCAN_FD";
BA_ "GenMsgCycleTime" BO_ 168 10;
BA_ "GenMsgILSupport" BO_ 168 "Yes";
BA_ "GenMsgPDUConstants" BO_ 168 "0x52,0x8c,0x50,0xee,0x4f,0xa6,0xcc,0xcf,0x7d,0x2f,0x98,0x6b,0x27,0x41,0x9f,0x93";
BA_ "GenMsgSendType" BO_ 168 "Cyclic";
BA_ "VFrameFormat" BO_ 168 "StandardCAN_FD";
BA_ "GenMsgCycleTime" BO_ 958 100;
BA_ "GenMsgDelayTime" BO_ 958 10;
BA_ "GenMsgILSupport" BO_ 958 "Yes";
BA_ "GenMsgPDUConstants" BO_ 958 "0x1f,0x28,0xc6,0x85,0xe6,0xf8,0xb0,0x19,0x5b,0x64,0x35,0x21,0xe4,0xf7,0x9c,0x24";
BA_ "GenMsgSendType" BO_ 958 "Cyclic";
BA_ "VFrameFormat" BO_ 958 "StandardCAN_FD";
BA_ "GenMsgCycleTime" BO_ 1631 500;
BA_ "GenMsgILSupport" BO_ 1631 "Yes";
BA_ "GenMsgSendType" BO_ 1631 "Cyclic";
BA_ "VFrameFormat" BO_ 1631 "StandardCAN_FD";
BA_ "GenSigActiveRepetitions" SG_ 2527679583 Parken_Seitenspiegel_Anf 5;
BA_ "GenSigSendType" SG_ 2527679583 Parken_Seitenspiegel_Anf "OnChangeWithRepetition";
BA_ "GenSigActiveRepetitions" SG_ 2527679583 Parken_ZV_Schliessen 5;
BA_ "GenSigSendType" SG_ 2527679583 Parken_ZV_Schliessen "OnChangeWithRepetition";
BA_ "GenSigActiveRepetitions" SG_ 2527679583 Parken_aktives_System_02 5;
BA_ "GenSigSendType" SG_ 2527679583 Parken_aktives_System_02 "OnChangeWithRepetition";
BA_ "GenSigSwitchedByIgnition" SG_ 2527679583 Parken_aktives_System_02 "No";
BA_ "GenSigActiveRepetitions" SG_ 2527679583 Parken_ZR_Sondermodus_Anf 5;
BA_ "GenSigSendType" SG_ 2527679583 Parken_ZR_Sondermodus_Anf "OnChangeWithRepetition";
BA_ "GenSigSwitchedByIgnition" SG_ 2527679583 Parken_ZR_Sondermodus_Anf "No";
BA_ "GenSigActiveRepetitions" SG_ 2527679583 Parken_Schluesselsuche_Anf 5;
BA_ "GenSigSendType" SG_ 2527679583 Parken_Schluesselsuche_Anf "OnChangeWithRepetition";
BA_ "GenSigActiveRepetitions" SG_ 2527679583 Parken_FFB_LED_Anf 5;
BA_ "GenSigSendType" SG_ 2527679583 Parken_FFB_LED_Anf "OnChangeWithRepetition";
BA_ "GenSigActiveRepetitions" SG_ 2527679583 Parken_Wegfahrsperren_Anf 5;
BA_ "GenSigSendType" SG_ 2527679583 Parken_Wegfahrsperren_Anf "OnChangeWithRepetition";
BA_ "GenSigActiveRepetitions" SG_ 2527679583 Parken_Aktivierungslicht_Anf 5;
BA_ "GenSigSendType" SG_ 2527679583 Parken_Aktivierungslicht_Anf "OnChangeWithRepetition";
BA_ "GenSigSwitchedByIgnition" SG_ 2527679583 Parken_Aktivierungslicht_Anf "No";
BA_ "GenSigActiveRepetitions" SG_ 2527679583 Parken_Fahrtrichtungslicht_Anf 5;
BA_ "GenSigSendType" SG_ 2527679583 Parken_Fahrtrichtungslicht_Anf "OnChangeWithRepetition";
BA_ "GenSigActiveRepetitions" SG_ 2527679583 Parken_Lichtnachlauf_Anf 5;
BA_ "GenSigSendType" SG_ 2527679583 Parken_Lichtnachlauf_Anf "OnChangeWithRepetition";
BA_ "GenSigActiveRepetitions" SG_ 2527679583 Parken_Fahrerhinweise_Anf 5;
BA_ "GenSigSendType" SG_ 2527679583 Parken_Fahrerhinweise_Anf "OnChangeWithRepetition";
BA_ "GenSigSwitchedByIgnition" SG_ 2527679583 Parken_Fahrerhinweise_Anf "No";
BA_ "GenSigActiveRepetitions" SG_ 2527679583 Parken_Bestaetigungsblinken_Anf 5;
BA_ "GenSigSendType" SG_ 2527679583 Parken_Bestaetigungsblinken_Anf "OnChangeWithRepetition";
BA_ "GenSigSwitchedByIgnition" SG_ 2527679583 Parken_Bestaetigungsblinken_Anf "No";
BA_ "GenSigActiveRepetitions" SG_ 2527679583 Parken_Fahrbereitschaftlicht_Anf 5;
BA_ "GenSigSendType" SG_ 2527679583 Parken_Fahrbereitschaftlicht_Anf "OnChangeWithRepetition";
BA_ "GenSigActiveRepetitions" SG_ 2527679583 Parken_Lichtsteuerung_Anf 5;
BA_ "GenSigSendType" SG_ 2527679583 Parken_Lichtsteuerung_Anf "OnChangeWithRepetition";
BA_ "GenSigSwitchedByIgnition" SG_ 2527679583 Parken_Lichtsteuerung_Anf "No";
BA_ "GenSigActiveRepetitions" SG_ 2527679583 IPA_Anf_Meldungen 5;
BA_ "GenSigSendType" SG_ 2527679583 IPA_Anf_Meldungen "OnChangeWithRepetition";
BA_ "GenSigSwitchedByIgnition" SG_ 2527679583 IPA_Anf_Meldungen "No";
BA_ "GenSigSendType" SG_ 1813 ISO_Airbag_01_Req_Data "OnChange";
BA_ "GenSigFuncType" SG_ 1813 ISO_Airbag_01_Req_Data "Protocol";
BA_ "GenSigSwitchedByIgnition" SG_ 1813 ISO_Airbag_01_Req_Data "No";
BA_ "GenSigSendType" SG_ 1919 ISO_Airbag_01_Resp_Data "OnChange";
BA_ "GenSigFuncType" SG_ 1919 ISO_Airbag_01_Resp_Data "Protocol";
BA_ "GenSigSwitchedByIgnition" SG_ 1919 ISO_Airbag_01_Resp_Data "No";
BA_ "GenSigSendType" SG_ 1792 ISO_ALL_01_Req_Data "OnChange";
BA_ "GenSigFuncType" SG_ 1792 ISO_ALL_01_Req_Data "Protocol";
BA_ "GenSigSwitchedByIgnition" SG_ 1792 ISO_ALL_01_Req_Data "No";
BA_ "GenSigSendType" SG_ 2621440021 ISOx_Airbag_01_Req_FD_Data "OnChange";
BA_ "GenSigFuncType" SG_ 2621440021 ISOx_Airbag_01_Req_FD_Data "Protocol";
BA_ "GenSigSwitchedByIgnition" SG_ 2621440021 ISOx_Airbag_01_Req_FD_Data "No";
BA_ "GenSigSendType" SG_ 2621571093 ISOx_Airbag_01_Resp_FD_Data "OnChange";
BA_ "GenSigFuncType" SG_ 2621571093 ISOx_Airbag_01_Resp_FD_Data "Protocol";
BA_ "GenSigSwitchedByIgnition" SG_ 2621571093 ISOx_Airbag_01_Resp_FD_Data "No";
BA_ "GenSigSendType" SG_ 2549874812 ISO_EMotor_01_Req_Data "OnChange";
BA_ "GenSigFuncType" SG_ 2549874812 ISO_EMotor_01_Req_Data "Protocol";
BA_ "GenSigSwitchedByIgnition" SG_ 2549874812 ISO_EMotor_01_Req_Data "No";
BA_ "GenSigSendType" SG_ 2621440124 ISOx_EMotor_01_Req_FD_Data "OnChange";
BA_ "GenSigFuncType" SG_ 2621440124 ISOx_EMotor_01_Req_FD_Data "Protocol";
BA_ "GenSigSwitchedByIgnition" SG_ 2621440124 ISOx_EMotor_01_Req_FD_Data "No";
BA_ "GenSigSendType" SG_ 2550005884 ISO_EMotor_01_Resp_Data "OnChange";
BA_ "GenSigFuncType" SG_ 2550005884 ISO_EMotor_01_Resp_Data "Protocol";
BA_ "GenSigSwitchedByIgnition" SG_ 2550005884 ISO_EMotor_01_Resp_Data "No";
BA_ "GenSigSendType" SG_ 2621571196 ISOx_EMotor_01_Resp_FD_Data "OnChange";
BA_ "GenSigFuncType" SG_ 2621571196 ISOx_EMotor_01_Resp_FD_Data "Protocol";
BA_ "GenSigSwitchedByIgnition" SG_ 2621571196 ISOx_EMotor_01_Resp_FD_Data "No";
BA_ "GenSigSendType" SG_ 2549874872 ISO_EMotor_02_Req_Data "OnChange";
BA_ "GenSigFuncType" SG_ 2549874872 ISO_EMotor_02_Req_Data "Protocol";
BA_ "GenSigSwitchedByIgnition" SG_ 2549874872 ISO_EMotor_02_Req_Data "No";
BA_ "GenSigSendType" SG_ 2621440184 ISOx_EMotor_02_Req_FD_Data "OnChange";
BA_ "GenSigFuncType" SG_ 2621440184 ISOx_EMotor_02_Req_FD_Data "Protocol";
BA_ "GenSigSwitchedByIgnition" SG_ 2621440184 ISOx_EMotor_02_Req_FD_Data "No";
BA_ "GenSigSendType" SG_ 2550005944 ISO_EMotor_02_Resp_Data "OnChange";
BA_ "GenSigFuncType" SG_ 2550005944 ISO_EMotor_02_Resp_Data "Protocol";
BA_ "GenSigSwitchedByIgnition" SG_ 2550005944 ISO_EMotor_02_Resp_Data "No";
BA_ "GenSigSendType" SG_ 2621571256 ISOx_EMotor_02_Resp_FD_Data "OnChange";
BA_ "GenSigFuncType" SG_ 2621571256 ISOx_EMotor_02_Resp_FD_Data "Protocol";
BA_ "GenSigSwitchedByIgnition" SG_ 2621571256 ISOx_EMotor_02_Resp_FD_Data "No";
BA_ "GenSigSendType" SG_ 2621505536 ISOx_Funkt_Req_All_FD_Data "OnChange";
BA_ "GenSigFuncType" SG_ 2621505536 ISOx_Funkt_Req_All_FD_Data "Protocol";
BA_ "GenSigSwitchedByIgnition" SG_ 2621505536 ISOx_Funkt_Req_All_FD_Data "No";
BA_ "GenSigSendType" SG_ 2549874806 ISOx_MO_01_Req_Data "OnChange";
BA_ "GenSigFuncType" SG_ 2549874806 ISOx_MO_01_Req_Data "Protocol";
BA_ "GenSigSwitchedByIgnition" SG_ 2549874806 ISOx_MO_01_Req_Data "No";
BA_ "GenSigSendType" SG_ 2621440118 ISOx_MO_01_Req_FD_Data "OnChange";
BA_ "GenSigFuncType" SG_ 2621440118 ISOx_MO_01_Req_FD_Data "Protocol";
BA_ "GenSigSwitchedByIgnition" SG_ 2621440118 ISOx_MO_01_Req_FD_Data "No";
BA_ "GenSigSendType" SG_ 2550005878 ISOx_MO_01_Resp_Data "OnChange";
BA_ "GenSigFuncType" SG_ 2550005878 ISOx_MO_01_Resp_Data "Protocol";
BA_ "GenSigSwitchedByIgnition" SG_ 2550005878 ISOx_MO_01_Resp_Data "No";
BA_ "GenSigSendType" SG_ 2621571190 ISOx_MO_01_Resp_FD_Data "OnChange";
BA_ "GenSigFuncType" SG_ 2621571190 ISOx_MO_01_Resp_FD_Data "Protocol";
BA_ "GenSigSwitchedByIgnition" SG_ 2621571190 ISOx_MO_01_Resp_FD_Data "No";
BA_ "GenSigSendType" SG_ 2527679684 Kamera_ASM_Ereignis "OnChange";
BA_ "GenSigSendType" SG_ 2527679684 Kamera_ASM_Zeitstempel "OnChange";
BA_ "GenSigStartValue" SG_ 2527679684 Kamera_ASM_Zeitstempel 255;
BA_ "GenSigSendType" SG_ 2527679684 Kamera_ASM_Data_1 "Cyclic";
BA_ "GenSigSendType" SG_ 2527679684 Kamera_ASM_Data_2 "Cyclic";
BA_ "GenSigSendType" SG_ 2527679684 Kamera_ASM_Data_3 "Cyclic";
BA_ "GenSigSendType" SG_ 2527679684 Kamera_ASM_Data_4 "Cyclic";
BA_ "GenSigSendType" SG_ 2527679684 Kamera_ASM_Data_5 "Cyclic";
BA_ "GenSigSendType" SG_ 2527679684 Kamera_ASM_Data_6 "Cyclic";
BA_ "GenSigSendType" SG_ 960 Klemmen_Status_01_CRC "Cyclic";
BA_ "GenSigFuncType" SG_ 960 Klemmen_Status_01_CRC "CRC-8";
BA_ "GenSigSwitchedByIgnition" SG_ 960 Klemmen_Status_01_CRC "No";
BA_ "GenSigSendType" SG_ 960 Klemmen_Status_01_BZ "Cyclic";
BA_ "GenSigFuncType" SG_ 960 Klemmen_Status_01_BZ "MsgCounter";
BA_ "GenSigSwitchedByIgnition" SG_ 960 Klemmen_Status_01_BZ "No";
BA_ "GenSigSendType" SG_ 960 RSt_Fahrerhinweise "OnChange";
BA_ "GenSigSwitchedByIgnition" SG_ 960 RSt_Fahrerhinweise "No";
BA_ "GenSigSendType" SG_ 960 ZAS_Kl_S "OnChange";
BA_ "GenSigSwitchedByIgnition" SG_ 960 ZAS_Kl_S "No";
BA_ "GenSigSendType" SG_ 960 ZAS_Kl_15 "OnChange";
BA_ "NWM-WakeupAllowed" SG_ 960 ZAS_Kl_15 "Yes";
BA_ "GenSigFuncType" SG_ 960 ZAS_Kl_15 "SW-Kl15";
BA_ "GenSigSwitchedByIgnition" SG_ 960 ZAS_Kl_15 "No";
BA_ "GenSigSendType" SG_ 960 ZAS_Kl_X "OnChange";
BA_ "GenSigSwitchedByIgnition" SG_ 960 ZAS_Kl_X "No";
BA_ "GenSigSendType" SG_ 960 ZAS_Kl_50_Startanforderung "OnChange";
BA_ "GenSigSwitchedByIgnition" SG_ 960 ZAS_Kl_50_Startanforderung "No";
BA_ "GenSigSendType" SG_ 960 BCM_Remotestart_Betrieb "OnChange";
BA_ "GenSigSwitchedByIgnition" SG_ 960 BCM_Remotestart_Betrieb "No";
BA_ "GenSigSendType" SG_ 960 ZAS_Kl_Infotainment "OnChange";
BA_ "GenSigSwitchedByIgnition" SG_ 960 ZAS_Kl_Infotainment "No";
BA_ "GenSigSendType" SG_ 960 BCM_Remotestart_KL15_Anf "OnChange";
BA_ "GenSigSwitchedByIgnition" SG_ 960 BCM_Remotestart_KL15_Anf "No";
BA_ "GenSigSendType" SG_ 960 BCM_Remotestart_MO_Start "OnChange";
BA_ "GenSigSwitchedByIgnition" SG_ 960 BCM_Remotestart_MO_Start "No";
BA_ "GenSigSendType" SG_ 960 KST_Warn_P1_ZST_def "OnChange";
BA_ "GenSigSwitchedByIgnition" SG_ 960 KST_Warn_P1_ZST_def "No";
BA_ "GenSigSendType" SG_ 960 KST_Warn_P2_ZST_def "OnChange";
BA_ "GenSigSwitchedByIgnition" SG_ 960 KST_Warn_P2_ZST_def "No";
BA_ "GenSigSendType" SG_ 960 KST_Fahrerhinweis_1 "OnChange";
BA_ "GenSigSwitchedByIgnition" SG_ 960 KST_Fahrerhinweis_1 "No";
BA_ "GenSigSendType" SG_ 960 KST_Fahrerhinweis_2 "OnChange";
BA_ "GenSigSwitchedByIgnition" SG_ 960 KST_Fahrerhinweis_2 "No";
BA_ "GenSigSendType" SG_ 960 BCM_Ausparken_Betrieb "OnChange";
BA_ "GenSigSwitchedByIgnition" SG_ 960 BCM_Ausparken_Betrieb "No";
BA_ "GenSigSendType" SG_ 960 KST_Fahrerhinweis_4 "OnChange";
BA_ "GenSigSwitchedByIgnition" SG_ 960 KST_Fahrerhinweis_4 "No";
BA_ "GenSigSendType" SG_ 960 KST_Fahrerhinweis_5 "OnChange";
BA_ "GenSigSwitchedByIgnition" SG_ 960 KST_Fahrerhinweis_5 "No";
BA_ "GenSigSendType" SG_ 960 KST_Fahrerhinweis_6 "OnChange";
BA_ "GenSigSwitchedByIgnition" SG_ 960 KST_Fahrerhinweis_6 "No";
BA_ "GenSigSendType" SG_ 2463978753 KST_WFS_Fahrfreigabe_Anforderung "OnChangeWithRepetition";
BA_ "GenSigSwitchedByIgnition" SG_ 2463978753 KST_WFS_Fahrfreigabe_Anforderung "No";
BA_ "GenSigSendType" SG_ 2463978753 KST_Sonderzustand_Status "OnChangeWithRepetition";
BA_ "GenSigSwitchedByIgnition" SG_ 2463978753 KST_Sonderzustand_Status "No";
BA_ "Fehlerwert" SG_ 2463978753 KST_Sonderzustand_Status 3;
BA_ "GenSigSendType" SG_ 2463978753 KST_Sonderzustand_Anforderung "OnChangeWithRepetition";
BA_ "GenSigSwitchedByIgnition" SG_ 2463978753 KST_Sonderzustand_Anforderung "No";
BA_ "Fehlerwert" SG_ 2463978753 KST_Sonderzustand_Anforderung 31;
BA_ "GenSigSendType" SG_ 1420 Klemmen_Steuerung_01_CRC "Cyclic";
BA_ "GenSigFuncType" SG_ 1420 Klemmen_Steuerung_01_CRC "CRC-8";
BA_ "GenSigSwitchedByIgnition" SG_ 1420 Klemmen_Steuerung_01_CRC "No";
BA_ "GenSigSendType" SG_ 1420 Klemmen_Steuerung_01_BZ "Cyclic";
BA_ "GenSigFuncType" SG_ 1420 Klemmen_Steuerung_01_BZ "MsgCounter";
BA_ "GenSigSwitchedByIgnition" SG_ 1420 Klemmen_Steuerung_01_BZ "No";
BA_ "GenSigSendType" SG_ 1420 KST_Anf_Klemme_15 "OnChangeWithRepetition";
BA_ "GenSigSwitchedByIgnition" SG_ 1420 KST_Anf_Klemme_15 "No";
BA_ "GenSigSendType" SG_ 1420 KST_Anf_Klemme_50 "OnChangeWithRepetition";
BA_ "GenSigSwitchedByIgnition" SG_ 1420 KST_Anf_Klemme_50 "No";
BA_ "GenSigSendType" SG_ 1420 KST_Anf_Klemme_S "OnChange";
BA_ "GenSigSwitchedByIgnition" SG_ 1420 KST_Anf_Klemme_S "No";
BA_ "GenSigSendType" SG_ 1420 KST_Txt_Werkstatt "OnChange";
BA_ "GenSigSwitchedByIgnition" SG_ 1420 KST_Txt_Werkstatt "No";
BA_ "GenSigSendType" SG_ 1420 KST_Txt_P_Gang "OnChange";
BA_ "GenSigSwitchedByIgnition" SG_ 1420 KST_Txt_P_Gang "No";
BA_ "GenSigSendType" SG_ 1420 KST_Txt_Panikabschaltung "OnChange";
BA_ "GenSigSwitchedByIgnition" SG_ 1420 KST_Txt_Panikabschaltung "No";
BA_ "GenSigSendType" SG_ 1420 KST_Anf_Klemmenfreigabe_ELV "OnChange";
BA_ "GenSigSwitchedByIgnition" SG_ 1420 KST_Anf_Klemmenfreigabe_ELV "No";
BA_ "GenSigSendType" SG_ 1420 KST_Txt_Komfortabschaltung "OnChange";
BA_ "GenSigSwitchedByIgnition" SG_ 1420 KST_Txt_Komfortabschaltung "No";
BA_ "GenSigSendType" SG_ 1420 KST_ZAT_betaetigt "OnChange";
BA_ "GenSigSwitchedByIgnition" SG_ 1420 KST_ZAT_betaetigt "No";
BA_ "GenSigSendType" SG_ 1420 KST_Unterdr_Zuendungsmeldung "OnChange";
BA_ "GenSigSwitchedByIgnition" SG_ 1420 KST_Unterdr_Zuendungsmeldung "No";
BA_ "GenSigSendType" SG_ 1420 KST_aut_Abschaltung_Zuendung "OnChangeWithRepetition";
BA_ "GenSigSwitchedByIgnition" SG_ 1420 KST_aut_Abschaltung_Zuendung "No";
BA_ "GenSigSendType" SG_ 1420 KST_Anf_Klemmenfreigabe_WFS "OnChange";
BA_ "GenSigSwitchedByIgnition" SG_ 1420 KST_Anf_Klemmenfreigabe_WFS "No";
BA_ "GenSigSendType" SG_ 1420 KST_Anf_ZV_Verriegelung "OnChange";
BA_ "GenSigSwitchedByIgnition" SG_ 1420 KST_Anf_ZV_Verriegelung "No";
BA_ "GenSigSendType" SG_ 1420 Relais_VoKo_angesteuert "OnChange";
BA_ "GenSigSwitchedByIgnition" SG_ 1420 Relais_VoKo_angesteuert "No";
BA_ "GenSigSendType" SG_ 1420 RSt_Anforderung_HMS "OnChange";
BA_ "GenSigSwitchedByIgnition" SG_ 1420 RSt_Anforderung_HMS "No";
BA_ "GenSigSendType" SG_ 1420 KST_Zuendungswarnung "OnChangeWithRepetition";
BA_ "GenSigSwitchedByIgnition" SG_ 1420 KST_Zuendungswarnung "No";
BA_ "GenSigSendType" SG_ 1420 KST_Fahrer_Info_Text "OnChange";
BA_ "GenSigSwitchedByIgnition" SG_ 1420 KST_Fahrer_Info_Text "No";
BA_ "GenSigSendType" SG_ 949 KL_Drehz_Anh "Cyclic";
BA_ "GenSigSwitchedByIgnition" SG_ 949 KL_Drehz_Anh "No";
BA_ "GenSigSendType" SG_ 949 KL_Vorwarn_Komp_ein "Cyclic";
BA_ "GenSigSwitchedByIgnition" SG_ 949 KL_Vorwarn_Komp_ein "No";
BA_ "GenSigSendType" SG_ 949 KL_AC_Schalter "Cyclic";
BA_ "GenSigSwitchedByIgnition" SG_ 949 KL_AC_Schalter "No";
BA_ "GenSigSendType" SG_ 949 KL_Komp_Moment_alt "Cyclic";
BA_ "GenSigFuncType" SG_ 949 KL_Komp_Moment_alt "DatedBit";
BA_ "GenSigSwitchedByIgnition" SG_ 949 KL_Komp_Moment_alt "No";
BA_ "GenSigSendType" SG_ 949 KL_Vorwarn_Zuheizer_ein "Cyclic";
BA_ "GenSigSwitchedByIgnition" SG_ 949 KL_Vorwarn_Zuheizer_ein "No";
BA_ "GenSigSendType" SG_ 949 KL_Zustand "Cyclic";
BA_ "GenSigSwitchedByIgnition" SG_ 949 KL_Zustand "No";
BA_ "GenSigSendType" SG_ 949 KL_Kompressorkupplung_linear "Cyclic";
BA_ "GenSigStartValue" SG_ 949 KL_Kompressorkupplung_linear 254;
BA_ "GenSigSwitchedByIgnition" SG_ 949 KL_Kompressorkupplung_linear "No";
BA_ "GenSigSendType" SG_ 949 KL_Charisma_FahrPr "Cyclic";
BA_ "GenSigSwitchedByIgnition" SG_ 949 KL_Charisma_FahrPr "No";
BA_ "GenSigSendType" SG_ 949 KL_Charisma_Status "Cyclic";
BA_ "GenSigSwitchedByIgnition" SG_ 949 KL_Charisma_Status "No";
BA_ "GenSigSendType" SG_ 949 KL_nachtr_Stopp_Anf "Cyclic";
BA_ "GenSigSwitchedByIgnition" SG_ 949 KL_nachtr_Stopp_Anf "No";
BA_ "GenSigSendType" SG_ 949 KL_T_Charge "Cyclic";
BA_ "GenSigSwitchedByIgnition" SG_ 949 KL_T_Charge "No";
BA_ "GenSigSendType" SG_ 949 KL_Last_Kompr "Cyclic";
BA_ "GenSigSwitchedByIgnition" SG_ 949 KL_Last_Kompr "No";
BA_ "Fehlerwert" SG_ 949 KL_Last_Kompr 255;
BA_ "GenSigSendType" SG_ 949 KL_Spannungs_Anf "Cyclic";
BA_ "GenSigSwitchedByIgnition" SG_ 949 KL_Spannungs_Anf "No";
BA_ "GenSigSendType" SG_ 949 KL_Thermomanagement "Cyclic";
BA_ "GenSigSwitchedByIgnition" SG_ 949 KL_Thermomanagement "No";
BA_ "GenSigSendType" SG_ 949 KL_StartStopp_Info "Cyclic";
BA_ "GenSigSwitchedByIgnition" SG_ 949 KL_StartStopp_Info "No";
BA_ "GenSigSendType" SG_ 949 KL_Freilauf_Info "Cyclic";
BA_ "GenSigSwitchedByIgnition" SG_ 949 KL_Freilauf_Info "No";
BA_ "GenSigSendType" SG_ 949 KL_Anf_KL "Cyclic";
BA_ "GenSigSwitchedByIgnition" SG_ 949 KL_Anf_KL "No";
BA_ "Fehlerwert" SG_ 949 KL_Anf_KL 255;
BA_ "GenSigSendType" SG_ 949 KL_el_Zuheizer_Stufe "Cyclic";
BA_ "GenSigSwitchedByIgnition" SG_ 949 KL_el_Zuheizer_Stufe "No";
BA_ "GenSigSendType" SG_ 949 KL_Ausstattung_Klima "Cyclic";
BA_ "GenSigSwitchedByIgnition" SG_ 949 KL_Ausstattung_Klima "No";
BA_ "GenSigSendType" SG_ 949 KL_Variante_Standheizung "Cyclic";
BA_ "GenSigSwitchedByIgnition" SG_ 949 KL_Variante_Standheizung "No";
BA_ "GenSigSendType" SG_ 949 KL_Anf_KV "Cyclic";
BA_ "GenSigStartValue" SG_ 949 KL_Anf_KV 126;
BA_ "GenSigSwitchedByIgnition" SG_ 949 KL_Anf_KV "No";
BA_ "GenSigSendType" SG_ 1511 KL_HV_Heizer_Strom "Cyclic";
BA_ "GenSigStartValue" SG_ 1511 KL_HV_Heizer_Strom 255;
BA_ "GenSigSwitchedByIgnition" SG_ 1511 KL_HV_Heizer_Strom "No";
BA_ "GenSigSendType" SG_ 1511 KL_EKK_Strom "Cyclic";
BA_ "GenSigStartValue" SG_ 1511 KL_EKK_Strom 255;
BA_ "GenSigSwitchedByIgnition" SG_ 1511 KL_EKK_Strom "No";
BA_ "GenSigSendType" SG_ 1511 KL_Pumpe_02_Soll "Cyclic";
BA_ "GenSigStartValue" SG_ 1511 KL_Pumpe_02_Soll 126;
BA_ "GenSigSwitchedByIgnition" SG_ 1511 KL_Pumpe_02_Soll "No";
BA_ "Fehlerwert" SG_ 1511 KL_Pumpe_02_Soll 127;
BA_ "GenSigSendType" SG_ 1511 KL_Ventil_03_Soll "Cyclic";
BA_ "GenSigSwitchedByIgnition" SG_ 1511 KL_Ventil_03_Soll "No";
BA_ "GenSigSendType" SG_ 1511 KL_Ventil_10_Status "Cyclic";
BA_ "GenSigStartValue" SG_ 1511 KL_Ventil_10_Status 6;
BA_ "GenSigSwitchedByIgnition" SG_ 1511 KL_Ventil_10_Status "No";
BA_ "Fehlerwert" SG_ 1511 KL_Ventil_10_Status 7;
BA_ "GenSigSendType" SG_ 1511 KL_Senderkennung "Cyclic";
BA_ "GenSigSwitchedByIgnition" SG_ 1511 KL_Senderkennung "No";
BA_ "GenSigSendType" SG_ 1511 WP_KJ_Soll "Cyclic";
BA_ "GenSigSwitchedByIgnition" SG_ 1511 WP_KJ_Soll "No";
BA_ "Fehlerwert" SG_ 1511 WP_KJ_Soll 3;
BA_ "GenSigSendType" SG_ 1511 KL_Fehler_HV_EKK "Cyclic";
BA_ "GenSigSwitchedByIgnition" SG_ 1511 KL_Fehler_HV_EKK "No";
BA_ "Fehlerwert" SG_ 1511 KL_Fehler_HV_EKK 3;
BA_ "GenSigSendType" SG_ 1511 KL_Fehler_HV_Heizer "Cyclic";
BA_ "GenSigSwitchedByIgnition" SG_ 1511 KL_Fehler_HV_Heizer "No";
BA_ "Fehlerwert" SG_ 1511 KL_Fehler_HV_Heizer 3;
BA_ "GenSigSendType" SG_ 1511 KL_BattKond_WaPu_DZMax "Cyclic";
BA_ "GenSigStartValue" SG_ 1511 KL_BattKond_WaPu_DZMax 62;
BA_ "GenSigSwitchedByIgnition" SG_ 1511 KL_BattKond_WaPu_DZMax "No";
BA_ "Fehlerwert" SG_ 1511 KL_BattKond_WaPu_DZMax 63;
BA_ "GenSigSendType" SG_ 1511 WP_Kuehlerluefter_Anf "Cyclic";
BA_ "GenSigSwitchedByIgnition" SG_ 1511 WP_Kuehlerluefter_Anf "No";
BA_ "Fehlerwert" SG_ 1511 WP_Kuehlerluefter_Anf 255;
BA_ "GenSigSendType" SG_ 1511 KL_KM_ASV_01_Status "Cyclic";
BA_ "GenSigSwitchedByIgnition" SG_ 1511 KL_KM_ASV_01_Status "No";
BA_ "Fehlerwert" SG_ 1511 KL_KM_ASV_01_Status 3;
BA_ "GenSigSendType" SG_ 1511 KL_KM_ASV_02_Status "Cyclic";
BA_ "GenSigSwitchedByIgnition" SG_ 1511 KL_KM_ASV_02_Status "No";
BA_ "Fehlerwert" SG_ 1511 KL_KM_ASV_02_Status 3;
BA_ "GenSigSendType" SG_ 1511 KL_Vorwarn_HVHeizer_Leistung "Cyclic";
BA_ "GenSigSwitchedByIgnition" SG_ 1511 KL_Vorwarn_HVHeizer_Leistung "No";
BA_ "Fehlerwert" SG_ 1511 KL_Vorwarn_HVHeizer_Leistung 15;
BA_ "GenSigSendType" SG_ 1511 KL_Status_EoHVL_EKK "Cyclic";
BA_ "GenSigSwitchedByIgnition" SG_ 1511 KL_Status_EoHVL_EKK "No";
BA_ "Fehlerwert" SG_ 1511 KL_Status_EoHVL_EKK 3;
BA_ "GenSigSendType" SG_ 1511 KL_Status_EoHVL_Heizer "Cyclic";
BA_ "GenSigSwitchedByIgnition" SG_ 1511 KL_Status_EoHVL_Heizer "No";
BA_ "Fehlerwert" SG_ 1511 KL_Status_EoHVL_Heizer 3;
BA_ "GenSigSendType" SG_ 1505 BCM1_Aussen_Temp_ungef "Cyclic";
BA_ "GenSigStartValue" SG_ 1505 BCM1_Aussen_Temp_ungef 254;
BA_ "GenSigSwitchedByIgnition" SG_ 1505 BCM1_Aussen_Temp_ungef "No";
BA_ "Fehlerwert" SG_ 1505 BCM1_Aussen_Temp_ungef 255;
BA_ "GenSigSendType" SG_ 1505 BCM_Heizungsabsperrventil_Status "Cyclic";
BA_ "GenSigStartValue" SG_ 1505 BCM_Heizungsabsperrventil_Status 2;
BA_ "GenSigSwitchedByIgnition" SG_ 1505 BCM_Heizungsabsperrventil_Status "No";
BA_ "Fehlerwert" SG_ 1505 BCM_Heizungsabsperrventil_Status 3;
BA_ "GenSigSendType" SG_ 1505 BCM_Heizungspumpe_Status "Cyclic";
BA_ "GenSigStartValue" SG_ 1505 BCM_Heizungspumpe_Status 2;
BA_ "GenSigSwitchedByIgnition" SG_ 1505 BCM_Heizungspumpe_Status "No";
BA_ "Fehlerwert" SG_ 1505 BCM_Heizungspumpe_Status 3;
BA_ "GenSigSendType" SG_ 1505 BCM_Kompressorkupplung_Status "Cyclic";
BA_ "GenSigStartValue" SG_ 1505 BCM_Kompressorkupplung_Status 2;
BA_ "GenSigSwitchedByIgnition" SG_ 1505 BCM_Kompressorkupplung_Status "No";
BA_ "Fehlerwert" SG_ 1505 BCM_Kompressorkupplung_Status 3;
BA_ "GenSigSendType" SG_ 1505 BCM1_PTC_stufig_Status "Cyclic";
BA_ "GenSigStartValue" SG_ 1505 BCM1_PTC_stufig_Status 6;
BA_ "GenSigSwitchedByIgnition" SG_ 1505 BCM1_PTC_stufig_Status "No";
BA_ "Fehlerwert" SG_ 1505 BCM1_PTC_stufig_Status 7;
BA_ "GenSigSendType" SG_ 1505 BCM1_FStatus_Aussentemp_ungef "Cyclic";
BA_ "GenSigStartValue" SG_ 1505 BCM1_FStatus_Aussentemp_ungef 1;
BA_ "GenSigSwitchedByIgnition" SG_ 1505 BCM1_FStatus_Aussentemp_ungef "No";
BA_ "GenSigSendType" SG_ 1505 BCM1_Kompressorstrom_ist "Cyclic";
BA_ "GenSigStartValue" SG_ 1505 BCM1_Kompressorstrom_ist 254;
BA_ "GenSigSwitchedByIgnition" SG_ 1505 BCM1_Kompressorstrom_ist "No";
BA_ "Fehlerwert" SG_ 1505 BCM1_Kompressorstrom_ist 255;
BA_ "GenSigSendType" SG_ 1505 BCM1_OBD_FStatus_ATemp "Cyclic";
BA_ "GenSigSwitchedByIgnition" SG_ 1505 BCM1_OBD_FStatus_ATemp "No";
BA_ "GenSigSendType" SG_ 2549088277 Airbag_01_KompSchutz "Cyclic";
BA_ "GenSigSwitchedByIgnition" SG_ 2549088277 Airbag_01_KompSchutz "No";
BA_ "GenSigSendType" SG_ 2549088277 Airbag_01_Abschaltstufe "Cyclic";
BA_ "GenSigSwitchedByIgnition" SG_ 2549088277 Airbag_01_Abschaltstufe "No";
BA_ "GenSigSendType" SG_ 2549088277 Airbag_01_Transport_Mode "Cyclic";
BA_ "GenSigSwitchedByIgnition" SG_ 2549088277 Airbag_01_Transport_Mode "No";
BA_ "GenSigSendType" SG_ 2549088277 Airbag_01_Nachlauftyp "Cyclic";
BA_ "GenSigStartValue" SG_ 2549088277 Airbag_01_Nachlauftyp 2;
BA_ "GenSigSwitchedByIgnition" SG_ 2549088277 Airbag_01_Nachlauftyp "No";
BA_ "GenSigSendType" SG_ 2549088277 NM_Airbag_01_Wakeup "Cyclic";
BA_ "NWM-WakeupAllowed" SG_ 2549088277 NM_Airbag_01_Wakeup "Yes";
BA_ "GenSigSwitchedByIgnition" SG_ 2549088277 NM_Airbag_01_Wakeup "No";
BA_ "GenSigSendType" SG_ 2549088277 KN_AB_DiagPfad "Cyclic";
BA_ "GenSigSwitchedByIgnition" SG_ 2549088277 KN_AB_DiagPfad "No";
BA_ "GenSigSendType" SG_ 2549088277 AB_KD_Fehler "Cyclic";
BA_ "GenSigSwitchedByIgnition" SG_ 2549088277 AB_KD_Fehler "No";
BA_ "GenSigSendType" SG_ 2549088380 EMotor_KompSchutz "Cyclic";
BA_ "GenSigSwitchedByIgnition" SG_ 2549088380 EMotor_KompSchutz "No";
BA_ "GenSigSendType" SG_ 2549088380 EMotor_01_Abschaltstufe "Cyclic";
BA_ "GenSigSwitchedByIgnition" SG_ 2549088380 EMotor_01_Abschaltstufe "No";
BA_ "GenSigSendType" SG_ 2549088380 EMotor_01_Transport_Mode "Cyclic";
BA_ "GenSigSwitchedByIgnition" SG_ 2549088380 EMotor_01_Transport_Mode "No";
BA_ "GenSigSendType" SG_ 2549088380 EMotor_Nachlauftyp "Cyclic";
BA_ "GenSigStartValue" SG_ 2549088380 EMotor_Nachlauftyp 2;
BA_ "GenSigSwitchedByIgnition" SG_ 2549088380 EMotor_Nachlauftyp "No";
BA_ "GenSigSendType" SG_ 2549088380 NM_EMotor_01_Wakeup "Cyclic";
BA_ "NWM-WakeupAllowed" SG_ 2549088380 NM_EMotor_01_Wakeup "Yes";
BA_ "GenSigSwitchedByIgnition" SG_ 2549088380 NM_EMotor_01_Wakeup "No";
BA_ "GenSigSendType" SG_ 2549088380 KN_EM_HYB_DiagPfad "Cyclic";
BA_ "GenSigSwitchedByIgnition" SG_ 2549088380 KN_EM_HYB_DiagPfad "No";
BA_ "GenSigSendType" SG_ 2549088380 EM_HYB_KD_Fehler "Cyclic";
BA_ "GenSigSwitchedByIgnition" SG_ 2549088380 EM_HYB_KD_Fehler "No";
BA_ "GenSigSendType" SG_ 2549088272 Gateway_KompSchutz "Cyclic";
BA_ "GenSigSwitchedByIgnition" SG_ 2549088272 Gateway_KompSchutz "No";
BA_ "GenSigSendType" SG_ 2549088272 Gateway_Abschaltstufe "Cyclic";
BA_ "GenSigSwitchedByIgnition" SG_ 2549088272 Gateway_Abschaltstufe "No";
BA_ "GenSigSendType" SG_ 2549088272 Gateway_Transport_Mode "Cyclic";
BA_ "GenSigSwitchedByIgnition" SG_ 2549088272 Gateway_Transport_Mode "No";
BA_ "GenSigSendType" SG_ 2549088272 Gateway_Nachlauftyp "Cyclic";
BA_ "GenSigStartValue" SG_ 2549088272 Gateway_Nachlauftyp 2;
BA_ "GenSigSwitchedByIgnition" SG_ 2549088272 Gateway_Nachlauftyp "No";
BA_ "GenSigSendType" SG_ 2549088272 NM_Gateway_Wakeup "Cyclic";
BA_ "NWM-WakeupAllowed" SG_ 2549088272 NM_Gateway_Wakeup "Yes";
BA_ "GenSigSwitchedByIgnition" SG_ 2549088272 NM_Gateway_Wakeup "No";
BA_ "GenSigSendType" SG_ 2549088272 KN_GW_DiagPfad "Cyclic";
BA_ "GenSigSwitchedByIgnition" SG_ 2549088272 KN_GW_DiagPfad "No";
BA_ "GenSigSendType" SG_ 2549088272 GW_KD_Fehler "Cyclic";
BA_ "GenSigSendType" SG_ 2549088440 LE2_KompSchutz "Cyclic";
BA_ "GenSigSwitchedByIgnition" SG_ 2549088440 LE2_KompSchutz "No";
BA_ "GenSigSendType" SG_ 2549088440 LE2_Abschaltstufe "Cyclic";
BA_ "GenSigSwitchedByIgnition" SG_ 2549088440 LE2_Abschaltstufe "No";
BA_ "GenSigSendType" SG_ 2549088440 LE2_Transport_Mode "Cyclic";
BA_ "GenSigSwitchedByIgnition" SG_ 2549088440 LE2_Transport_Mode "No";
BA_ "GenSigSendType" SG_ 2549088440 LE2_Nachlauftyp "Cyclic";
BA_ "GenSigStartValue" SG_ 2549088440 LE2_Nachlauftyp 2;
BA_ "GenSigSwitchedByIgnition" SG_ 2549088440 LE2_Nachlauftyp "No";
BA_ "GenSigSendType" SG_ 2549088440 NM_LE2_Wakeup "Cyclic";
BA_ "NWM-WakeupAllowed" SG_ 2549088440 NM_LE2_Wakeup "Yes";
BA_ "GenSigSwitchedByIgnition" SG_ 2549088440 NM_LE2_Wakeup "No";
BA_ "GenSigSendType" SG_ 2549088440 KN_LE2_DiagPfad "Cyclic";
BA_ "GenSigSwitchedByIgnition" SG_ 2549088440 KN_LE2_DiagPfad "No";
BA_ "GenSigSendType" SG_ 2549088440 LE2_KD_Fehler "Cyclic";
BA_ "GenSigSwitchedByIgnition" SG_ 2549088440 LE2_KD_Fehler "No";
BA_ "GenSigSendType" SG_ 2549088374 Motor_KompSchutz "Cyclic";
BA_ "GenSigSwitchedByIgnition" SG_ 2549088374 Motor_KompSchutz "No";
BA_ "GenSigSendType" SG_ 2549088374 MO_01_Abschaltstufe "Cyclic";
BA_ "GenSigSwitchedByIgnition" SG_ 2549088374 MO_01_Abschaltstufe "No";
BA_ "GenSigSendType" SG_ 2549088374 MO_01_Transport_Mode "Cyclic";
BA_ "GenSigSwitchedByIgnition" SG_ 2549088374 MO_01_Transport_Mode "No";
BA_ "GenSigSendType" SG_ 2549088374 Motor_Nachlauftyp "Cyclic";
BA_ "GenSigStartValue" SG_ 2549088374 Motor_Nachlauftyp 2;
BA_ "GenSigSwitchedByIgnition" SG_ 2549088374 Motor_Nachlauftyp "No";
BA_ "GenSigSendType" SG_ 2549088374 KN_Motor_ECUKnockOutTimer "Cyclic";
BA_ "GenSigSwitchedByIgnition" SG_ 2549088374 KN_Motor_ECUKnockOutTimer "No";
BA_ "GenSigSendType" SG_ 2549088374 KN_Motor_BusKnockOut "Cyclic";
BA_ "GenSigSwitchedByIgnition" SG_ 2549088374 KN_Motor_BusKnockOut "No";
BA_ "GenSigSendType" SG_ 2549088374 KN_Motor_BusKnockOutTimer "Cyclic";
BA_ "GenSigSwitchedByIgnition" SG_ 2549088374 KN_Motor_BusKnockOutTimer "No";
BA_ "GenSigSendType" SG_ 2549088374 NM_MO_01_Wakeup "Cyclic";
BA_ "NWM-WakeupAllowed" SG_ 2549088374 NM_MO_01_Wakeup "Yes";
BA_ "GenSigSwitchedByIgnition" SG_ 2549088374 NM_MO_01_Wakeup "No";
BA_ "GenSigSendType" SG_ 2549088374 KN_Motor_ECUKnockOut "Cyclic";
BA_ "GenSigSwitchedByIgnition" SG_ 2549088374 KN_Motor_ECUKnockOut "No";
BA_ "GenSigSendType" SG_ 2549088374 KN_MO_DiagPfad "Cyclic";
BA_ "GenSigSwitchedByIgnition" SG_ 2549088374 KN_MO_DiagPfad "No";
BA_ "GenSigSendType" SG_ 2549088374 MO_KD_Fehler "Cyclic";
BA_ "GenSigSwitchedByIgnition" SG_ 2549088374 MO_KD_Fehler "No";
BA_ "GenSigFuncType" SG_ 2621440277 KS_Airbag_01_Req_FD_Data "Protocol";
BA_ "GenSigSwitchedByIgnition" SG_ 2621440277 KS_Airbag_01_Req_FD_Data "No";
BA_ "GenSigFuncType" SG_ 2621571349 KS_Airbag_01_Resp_FD_Data "Protocol";
BA_ "GenSigSwitchedByIgnition" SG_ 2621571349 KS_Airbag_01_Resp_FD_Data "No";
BA_ "GenSigSendType" SG_ 982 Licht_hinten_01_BZ "Cyclic";
BA_ "GenSigFuncType" SG_ 982 Licht_hinten_01_BZ "MsgCounter";
BA_ "GenSigSwitchedByIgnition" SG_ 982 Licht_hinten_01_BZ "No";
BA_ "GenSigSendType" SG_ 982 LH_Aussenlicht_def "Cyclic";
BA_ "GenSigSwitchedByIgnition" SG_ 982 LH_Aussenlicht_def "No";
BA_ "GenSigSendType" SG_ 982 LH_Standlicht_H_aktiv "Cyclic";
BA_ "GenSigSwitchedByIgnition" SG_ 982 LH_Standlicht_H_aktiv "No";
BA_ "GenSigSendType" SG_ 982 LH_Parklicht_HL_aktiv "Cyclic";
BA_ "GenSigSwitchedByIgnition" SG_ 982 LH_Parklicht_HL_aktiv "No";
BA_ "GenSigSendType" SG_ 982 LH_Parklicht_HR_aktiv "Cyclic";
BA_ "GenSigSwitchedByIgnition" SG_ 982 LH_Parklicht_HR_aktiv "No";
BA_ "GenSigSendType" SG_ 982 LH_Bremslicht_H_aktiv "Cyclic";
BA_ "GenSigSwitchedByIgnition" SG_ 982 LH_Bremslicht_H_aktiv "No";
BA_ "GenSigSendType" SG_ 982 LH_Nebelschluss_aktiv "Cyclic";
BA_ "GenSigSwitchedByIgnition" SG_ 982 LH_Nebelschluss_aktiv "No";
BA_ "GenSigSendType" SG_ 982 LH_Rueckfahrlicht_aktiv "Cyclic";
BA_ "GenSigSwitchedByIgnition" SG_ 982 LH_Rueckfahrlicht_aktiv "No";
BA_ "GenSigSendType" SG_ 982 LH_Blinker_HL_akt "Cyclic";
BA_ "GenSigSwitchedByIgnition" SG_ 982 LH_Blinker_HL_akt "No";
BA_ "GenSigSendType" SG_ 982 LH_Blinker_HR_akt "Cyclic";
BA_ "GenSigSwitchedByIgnition" SG_ 982 LH_Blinker_HR_akt "No";
BA_ "GenSigSendType" SG_ 982 LH_Blinker_li_def "Cyclic";
BA_ "GenSigSwitchedByIgnition" SG_ 982 LH_Blinker_li_def "No";
BA_ "GenSigSendType" SG_ 982 LH_Bremsl_li_def "Cyclic";
BA_ "GenSigSwitchedByIgnition" SG_ 982 LH_Bremsl_li_def "No";
BA_ "GenSigSendType" SG_ 982 LH_Schlusslicht_li_def "Cyclic";
BA_ "GenSigSwitchedByIgnition" SG_ 982 LH_Schlusslicht_li_def "No";
BA_ "GenSigSendType" SG_ 982 LH_Rueckf_li_def "Cyclic";
BA_ "GenSigSwitchedByIgnition" SG_ 982 LH_Rueckf_li_def "No";
BA_ "GenSigSendType" SG_ 982 LH_Nebel_li_def "Cyclic";
BA_ "GenSigSwitchedByIgnition" SG_ 982 LH_Nebel_li_def "No";
BA_ "GenSigSendType" SG_ 982 LH_Schluss_Brems_Nebel_li_def "Cyclic";
BA_ "GenSigSwitchedByIgnition" SG_ 982 LH_Schluss_Brems_Nebel_li_def "No";
BA_ "GenSigSendType" SG_ 982 LH_Schluss_Brems_Nebel_re_def "Cyclic";
BA_ "GenSigSwitchedByIgnition" SG_ 982 LH_Schluss_Brems_Nebel_re_def "No";
BA_ "GenSigSendType" SG_ 982 LH_Zusatzschlussl_def "Cyclic";
BA_ "GenSigSwitchedByIgnition" SG_ 982 LH_Zusatzschlussl_def "No";
BA_ "GenSigSendType" SG_ 982 LH_Schluss_Brems_li_def "Cyclic";
BA_ "GenSigSwitchedByIgnition" SG_ 982 LH_Schluss_Brems_li_def "No";
BA_ "GenSigSendType" SG_ 982 LH_Schluss_Nebel_li_def "Cyclic";
BA_ "GenSigSwitchedByIgnition" SG_ 982 LH_Schluss_Nebel_li_def "No";
BA_ "GenSigSendType" SG_ 982 LH_SL_BRL_BLK_li_def "Cyclic";
BA_ "GenSigSwitchedByIgnition" SG_ 982 LH_SL_BRL_BLK_li_def "No";
BA_ "GenSigSendType" SG_ 982 LH_Brems_Blk_li_def "Cyclic";
BA_ "GenSigSwitchedByIgnition" SG_ 982 LH_Brems_Blk_li_def "No";
BA_ "GenSigSendType" SG_ 982 LH_Diag_Status_re_def "Cyclic";
BA_ "GenSigSwitchedByIgnition" SG_ 982 LH_Diag_Status_re_def "No";
BA_ "GenSigSendType" SG_ 982 LH_Diag_Status_li_def "Cyclic";
BA_ "GenSigSwitchedByIgnition" SG_ 982 LH_Diag_Status_li_def "No";
BA_ "GenSigSendType" SG_ 982 LH_Diag_LED_li_def "Cyclic";
BA_ "GenSigSwitchedByIgnition" SG_ 982 LH_Diag_LED_li_def "No";
BA_ "GenSigSendType" SG_ 982 LH_Diag_LED_re_def "Cyclic";
BA_ "GenSigSwitchedByIgnition" SG_ 982 LH_Diag_LED_re_def "No";
BA_ "GenSigSendType" SG_ 982 LH_Blinker_re_def "Cyclic";
BA_ "GenSigSwitchedByIgnition" SG_ 982 LH_Blinker_re_def "No";
BA_ "GenSigSendType" SG_ 982 LH_Bremsl_re_def "Cyclic";
BA_ "GenSigSwitchedByIgnition" SG_ 982 LH_Bremsl_re_def "No";
BA_ "GenSigSendType" SG_ 982 LH_Schlusslicht_re_def "Cyclic";
BA_ "GenSigSwitchedByIgnition" SG_ 982 LH_Schlusslicht_re_def "No";
BA_ "GenSigSendType" SG_ 982 LH_Rueckf_re_def "Cyclic";
BA_ "GenSigSwitchedByIgnition" SG_ 982 LH_Rueckf_re_def "No";
BA_ "GenSigSendType" SG_ 982 LH_Nebel_re_def "Cyclic";
BA_ "GenSigSwitchedByIgnition" SG_ 982 LH_Nebel_re_def "No";
BA_ "GenSigSendType" SG_ 982 LH_Schluss_Brems_mi_def "Cyclic";
BA_ "GenSigSwitchedByIgnition" SG_ 982 LH_Schluss_Brems_mi_def "No";
BA_ "GenSigSendType" SG_ 982 LH_Schluss_Brems_re_def "Cyclic";
BA_ "GenSigSwitchedByIgnition" SG_ 982 LH_Schluss_Brems_re_def "No";
BA_ "GenSigSendType" SG_ 982 LH_Schluss_Nebel_re_def "Cyclic";
BA_ "GenSigSwitchedByIgnition" SG_ 982 LH_Schluss_Nebel_re_def "No";
BA_ "GenSigSendType" SG_ 982 LH_SL_BRL_BLK_re_def "Cyclic";
BA_ "GenSigSwitchedByIgnition" SG_ 982 LH_SL_BRL_BLK_re_def "No";
BA_ "GenSigSendType" SG_ 982 LH_Brems_Blk_re_def "Cyclic";
BA_ "GenSigSwitchedByIgnition" SG_ 982 LH_Brems_Blk_re_def "No";
BA_ "GenSigSendType" SG_ 982 LH_Kennzl_def "Cyclic";
BA_ "GenSigSwitchedByIgnition" SG_ 982 LH_Kennzl_def "No";
BA_ "GenSigSendType" SG_ 982 LH_3_Bremsl_def "Cyclic";
BA_ "GenSigSwitchedByIgnition" SG_ 982 LH_3_Bremsl_def "No";
BA_ "GenSigSendType" SG_ 982 LH_Nebel_mi_def "Cyclic";
BA_ "GenSigSwitchedByIgnition" SG_ 982 LH_Nebel_mi_def "No";
BA_ "GenSigSendType" SG_ 982 LH_Rueckf_mi_def "Cyclic";
BA_ "GenSigSwitchedByIgnition" SG_ 982 LH_Rueckf_mi_def "No";
BA_ "GenSigSendType" SG_ 982 LH_Schlusslicht_mi_def "Cyclic";
BA_ "GenSigSwitchedByIgnition" SG_ 982 LH_Schlusslicht_mi_def "No";
BA_ "GenSigSendType" SG_ 982 LH_Bremsl_li_ges_def "Cyclic";
BA_ "GenSigSwitchedByIgnition" SG_ 982 LH_Bremsl_li_ges_def "No";
BA_ "GenSigSendType" SG_ 982 LH_Bremsl_re_ges_def "Cyclic";
BA_ "GenSigSwitchedByIgnition" SG_ 982 LH_Bremsl_re_ges_def "No";
BA_ "GenSigSendType" SG_ 982 LH_Bremsl_mi_def "Cyclic";
BA_ "GenSigSwitchedByIgnition" SG_ 982 LH_Bremsl_mi_def "No";
BA_ "GenSigSendType" SG_ 982 BRL_als_SHL "OnChange";
BA_ "GenSigSwitchedByIgnition" SG_ 982 BRL_als_SHL "No";
BA_ "GenSigSendType" SG_ 134 LWI_01_CRC "Cyclic";
BA_ "GenSigFuncType" SG_ 134 LWI_01_CRC "CRC-8";
BA_ "GenSigSwitchedByIgnition" SG_ 134 LWI_01_CRC "No";
BA_ "GenSigSendType" SG_ 134 LWI_01_BZ "Cyclic";
BA_ "GenSigFuncType" SG_ 134 LWI_01_BZ "MsgCounter";
BA_ "GenSigSendType" SG_ 134 LWI_Sensorstatus "Cyclic";
BA_ "GenSigSendType" SG_ 134 LWI_QBit_Sub_Daten "Cyclic";
BA_ "GenSigSendType" SG_ 134 LWI_QBit_Lenkradwinkel "Cyclic";
BA_ "GenSigStartValue" SG_ 134 LWI_QBit_Lenkradwinkel 1;
BA_ "GenSigSendType" SG_ 134 LWI_Lenkradwinkel "Cyclic";
BA_ "GenSigStartValue" SG_ 134 LWI_Lenkradwinkel 8190;
BA_ "Fehlerwert" SG_ 134 LWI_Lenkradwinkel 8191;
BA_ "GenSigSendType" SG_ 134 LWI_VZ_Lenkradwinkel "Cyclic";
BA_ "GenSigSendType" SG_ 134 LWI_VZ_Lenkradw_Geschw "Cyclic";
BA_ "GenSigSendType" SG_ 134 LWI_Lenkradw_Geschw "Cyclic";
BA_ "GenSigStartValue" SG_ 134 LWI_Lenkradw_Geschw 510;
BA_ "Fehlerwert" SG_ 134 LWI_Lenkradw_Geschw 511;
BA_ "GenSigSendType" SG_ 134 LWI_Sub_Daten "Cyclic";
BA_ "GenSigSendType" SG_ 817 MFL_Zaehler "Cyclic";
BA_ "GenSigSwitchedByIgnition" SG_ 817 MFL_Zaehler "No";
BA_ "GenSigSendType" SG_ 817 MFL_Toggle "Cyclic";
BA_ "GenSigSwitchedByIgnition" SG_ 817 MFL_Toggle "No";
BA_ "GenSigSendType" SG_ 817 MFL_Lokalaktiv "Cyclic";
BA_ "GenSigSwitchedByIgnition" SG_ 817 MFL_Lokalaktiv "No";
BA_ "GenSigSendType" SG_ 817 MFL_M_Taste "Cyclic";
BA_ "GenSigSendType" SG_ 817 MFL_Paddle_Verbau "Cyclic";
BA_ "GenSigSwitchedByIgnition" SG_ 817 MFL_Paddle_Verbau "No";
BA_ "GenSigSendType" SG_ 817 MFL_Tastencode_1 "Cyclic";
BA_ "GenSigSwitchedByIgnition" SG_ 817 MFL_Tastencode_1 "No";
BA_ "GenSigSendType" SG_ 817 MFL_Tastencode_2 "Cyclic";
BA_ "GenSigSwitchedByIgnition" SG_ 817 MFL_Tastencode_2 "No";
BA_ "GenSigSendType" SG_ 817 MFL_Eventcode_1 "Cyclic";
BA_ "GenSigSwitchedByIgnition" SG_ 817 MFL_Eventcode_1 "No";
BA_ "GenSigSendType" SG_ 817 MFL_Eventcode_2 "Cyclic";
BA_ "GenSigSwitchedByIgnition" SG_ 817 MFL_Eventcode_2 "No";
BA_ "GenSigSendType" SG_ 817 MFL_Marke "Cyclic";
BA_ "GenSigFuncType" SG_ 817 MFL_Marke "Constant";
BA_ "GenSigSwitchedByIgnition" SG_ 817 MFL_Marke "No";
BA_ "GenSigSendType" SG_ 817 MFL_Variante "Cyclic";
BA_ "GenSigFuncType" SG_ 817 MFL_Variante "Constant";
BA_ "GenSigSwitchedByIgnition" SG_ 817 MFL_Variante "No";
BA_ "GenSigSendType" SG_ 817 MFL_Dummy_0_Signal_1 "Cyclic";
BA_ "GenSigSwitchedByIgnition" SG_ 817 MFL_Dummy_0_Signal_1 "No";
BA_ "GenSigSendType" SG_ 817 MFL_Tip_Down "IfActive";
BA_ "GenSigSendType" SG_ 817 MFL_Tip_Up "IfActive";
BA_ "GenSigSendType" SG_ 817 MFL_SatModul_links_Err "Cyclic";
BA_ "GenSigFuncType" SG_ 817 MFL_SatModul_links_Err "DatedBit";
BA_ "GenSigSwitchedByIgnition" SG_ 817 MFL_SatModul_links_Err "No";
BA_ "Fehlerwert" SG_ 817 MFL_SatModul_links_Err 1;
BA_ "GenSigSendType" SG_ 817 MFL_SatModul_rechts_Err "Cyclic";
BA_ "GenSigFuncType" SG_ 817 MFL_SatModul_rechts_Err "DatedBit";
BA_ "GenSigSwitchedByIgnition" SG_ 817 MFL_SatModul_rechts_Err "No";
BA_ "Fehlerwert" SG_ 817 MFL_SatModul_rechts_Err 1;
BA_ "GenSigSendType" SG_ 817 MFL_Dummy_0_Signal_2 "Cyclic";
BA_ "GenSigSwitchedByIgnition" SG_ 817 MFL_Dummy_0_Signal_2 "No";
BA_ "GenSigSendType" SG_ 817 MFL_Dummy_0_Signal_3 "Cyclic";
BA_ "GenSigSwitchedByIgnition" SG_ 817 MFL_Dummy_0_Signal_3 "No";
BA_ "GenSigSendType" SG_ 817 MFL_LR_HZG_Status "Cyclic";
BA_ "GenSigSwitchedByIgnition" SG_ 817 MFL_LR_HZG_Status "No";
BA_ "GenSigSendType" SG_ 817 MFL_LR_HZG_Err "Cyclic";
BA_ "GenSigSwitchedByIgnition" SG_ 817 MFL_LR_HZG_Err "No";
BA_ "Fehlerwert" SG_ 817 MFL_LR_HZG_Err 1;
BA_ "GenSigSendType" SG_ 817 MFL_Signalhorn "IfActive";
BA_ "GenSigSwitchedByIgnition" SG_ 817 MFL_Signalhorn "No";
BA_ "GenSigSendType" SG_ 817 MFL_Signalhorn_Err "Cyclic";
BA_ "GenSigSwitchedByIgnition" SG_ 817 MFL_Signalhorn_Err "No";
BA_ "Fehlerwert" SG_ 817 MFL_Signalhorn_Err 1;
BA_ "GenSigSendType" SG_ 817 MFL_Tip_links_Err "Cyclic";
BA_ "GenSigSwitchedByIgnition" SG_ 817 MFL_Tip_links_Err "No";
BA_ "Fehlerwert" SG_ 817 MFL_Tip_links_Err 1;
BA_ "GenSigSendType" SG_ 817 MFL_Tip_rechts_Err "Cyclic";
BA_ "GenSigSwitchedByIgnition" SG_ 817 MFL_Tip_rechts_Err "No";
BA_ "Fehlerwert" SG_ 817 MFL_Tip_rechts_Err 1;
BA_ "GenSigSendType" SG_ 817 MFL_Taste_links_Err "Cyclic";
BA_ "GenSigSwitchedByIgnition" SG_ 817 MFL_Taste_links_Err "No";
BA_ "Fehlerwert" SG_ 817 MFL_Taste_links_Err 1;
BA_ "GenSigSendType" SG_ 817 MFL_Taste_rechts_Err "Cyclic";
BA_ "GenSigSwitchedByIgnition" SG_ 817 MFL_Taste_rechts_Err "No";
BA_ "Fehlerwert" SG_ 817 MFL_Taste_rechts_Err 1;
BA_ "GenSigSendType" SG_ 817 MFL_ECU_Err "Cyclic";
BA_ "GenSigSwitchedByIgnition" SG_ 817 MFL_ECU_Err "No";
BA_ "Fehlerwert" SG_ 817 MFL_ECU_Err 1;
BA_ "GenSigSendType" SG_ 817 MFL_Response_Err "Cyclic";
BA_ "GenSigSwitchedByIgnition" SG_ 817 MFL_Response_Err "No";
BA_ "Fehlerwert" SG_ 817 MFL_Response_Err 1;
BA_ "GenSigSendType" SG_ 15 MO_SOPC "IfActive";
BA_ "GenSigSwitchedByIgnition" SG_ 15 MO_SOPC "No";
BA_ "GenSigSendType" SG_ 1600 MO_QBit_Ansaugluft_Temp "Cyclic";
BA_ "GenSigStartValue" SG_ 1600 MO_QBit_Ansaugluft_Temp 1;
BA_ "GenSigSwitchedByIgnition" SG_ 1600 MO_QBit_Ansaugluft_Temp "No";
BA_ "GenSigSendType" SG_ 1600 MO_QBit_Oel_Temp "Cyclic";
BA_ "GenSigStartValue" SG_ 1600 MO_QBit_Oel_Temp 1;
BA_ "GenSigSwitchedByIgnition" SG_ 1600 MO_QBit_Oel_Temp "No";
BA_ "GenSigSendType" SG_ 1600 MO_QBit_Kuehlmittel_Temp "Cyclic";
BA_ "GenSigStartValue" SG_ 1600 MO_QBit_Kuehlmittel_Temp 1;
BA_ "GenSigSwitchedByIgnition" SG_ 1600 MO_QBit_Kuehlmittel_Temp "No";
BA_ "GenSigSendType" SG_ 1600 MO_KL15_Abschaltempfehlung "Cyclic";
BA_ "GenSigSwitchedByIgnition" SG_ 1600 MO_KL15_Abschaltempfehlung "No";
BA_ "GenSigSendType" SG_ 1600 MO_HYB_Fehler_HV_Netz "Cyclic";
BA_ "GenSigSwitchedByIgnition" SG_ 1600 MO_HYB_Fehler_HV_Netz "No";
BA_ "GenSigSendType" SG_ 1600 MO_aktives_Getriebeheizen "Cyclic";
BA_ "GenSigSwitchedByIgnition" SG_ 1600 MO_aktives_Getriebeheizen "No";
BA_ "GenSigSendType" SG_ 1600 MO_Absperrventil_oeffnen "Cyclic";
BA_ "GenSigSwitchedByIgnition" SG_ 1600 MO_Absperrventil_oeffnen "No";
BA_ "GenSigSendType" SG_ 1600 MO_Ansaugluft_Temp "Cyclic";
BA_ "GenSigStartValue" SG_ 1600 MO_Ansaugluft_Temp 254;
BA_ "GenSigSwitchedByIgnition" SG_ 1600 MO_Ansaugluft_Temp "No";
BA_ "Fehlerwert" SG_ 1600 MO_Ansaugluft_Temp 255;
BA_ "GenSigSendType" SG_ 1600 MO_Oel_Temp "Cyclic";
BA_ "GenSigStartValue" SG_ 1600 MO_Oel_Temp 254;
BA_ "GenSigSwitchedByIgnition" SG_ 1600 MO_Oel_Temp "No";
BA_ "Fehlerwert" SG_ 1600 MO_Oel_Temp 255;
BA_ "GenSigSendType" SG_ 1600 MO_Kuehlmittel_Temp "Cyclic";
BA_ "GenSigStartValue" SG_ 1600 MO_Kuehlmittel_Temp 254;
BA_ "GenSigSwitchedByIgnition" SG_ 1600 MO_Kuehlmittel_Temp "No";
BA_ "Fehlerwert" SG_ 1600 MO_Kuehlmittel_Temp 255;
BA_ "GenSigSendType" SG_ 1600 MO_Hoeheninfo "Cyclic";
BA_ "GenSigSwitchedByIgnition" SG_ 1600 MO_Hoeheninfo "No";
BA_ "Fehlerwert" SG_ 1600 MO_Hoeheninfo 255;
BA_ "GenSigSendType" SG_ 1600 MO_Kennfeldk "Cyclic";
BA_ "GenSigSwitchedByIgnition" SG_ 1600 MO_Kennfeldk "No";
BA_ "GenSigSendType" SG_ 1600 MO_Versionsinfo_02 "Cyclic";
BA_ "GenSigSwitchedByIgnition" SG_ 1600 MO_Versionsinfo_02 "No";
BA_ "GenSigSendType" SG_ 1600 MO_QBit_Hoeheninfo "Cyclic";
BA_ "GenSigStartValue" SG_ 1600 MO_QBit_Hoeheninfo 1;
BA_ "GenSigSwitchedByIgnition" SG_ 1600 MO_QBit_Hoeheninfo "No";
BA_ "GenSigSendType" SG_ 1600 MO_Getriebe_kuehlen "Cyclic";
BA_ "GenSigSwitchedByIgnition" SG_ 1600 MO_Getriebe_kuehlen "No";
BA_ "GenSigSendType" SG_ 1600 MO_Mom_Traegheit_02 "Cyclic";
BA_ "GenSigSwitchedByIgnition" SG_ 1600 MO_Mom_Traegheit_02 "No";
BA_ "GenSigSendType" SG_ 1600 MO_Heizungspumpenansteuerung "Cyclic";
BA_ "GenSigStartValue" SG_ 1600 MO_Heizungspumpenansteuerung 14;
BA_ "GenSigSwitchedByIgnition" SG_ 1600 MO_Heizungspumpenansteuerung "No";
BA_ "Fehlerwert" SG_ 1600 MO_Heizungspumpenansteuerung 13;
BA_ "GenSigSendType" SG_ 1600 MO_SpannungsAnf "Cyclic";
BA_ "GenSigSwitchedByIgnition" SG_ 1600 MO_SpannungsAnf "No";
BA_ "GenSigSendType" SG_ 1600 MO_Nachlaufzeit_Heizungspumpe "Cyclic";
BA_ "GenSigSwitchedByIgnition" SG_ 1600 MO_Nachlaufzeit_Heizungspumpe "No";
BA_ "GenSigSendType" SG_ 167 Motor_11_CRC "Cyclic";
BA_ "GenSigFuncType" SG_ 167 Motor_11_CRC "CRC-8";
BA_ "GenSigSwitchedByIgnition" SG_ 167 Motor_11_CRC "No";
BA_ "GenSigSendType" SG_ 167 Motor_11_BZ "Cyclic";
BA_ "GenSigFuncType" SG_ 167 Motor_11_BZ "MsgCounter";
BA_ "GenSigSwitchedByIgnition" SG_ 167 Motor_11_BZ "No";
BA_ "GenSigSendType" SG_ 167 MO_Mom_Soll_Roh "Cyclic";
BA_ "GenSigStartValue" SG_ 167 MO_Mom_Soll_Roh 1022;
BA_ "GenSigSwitchedByIgnition" SG_ 167 MO_Mom_Soll_Roh "No";
BA_ "GenSigSendType" SG_ 167 MO_Mom_Ist_Summe "Cyclic";
BA_ "GenSigStartValue" SG_ 167 MO_Mom_Ist_Summe 1022;
BA_ "GenSigSwitchedByIgnition" SG_ 167 MO_Mom_Ist_Summe "No";
BA_ "GenSigSendType" SG_ 167 MO_Mom_Traegheit_Summe "Cyclic";
BA_ "GenSigStartValue" SG_ 167 MO_Mom_Traegheit_Summe 1022;
BA_ "GenSigSwitchedByIgnition" SG_ 167 MO_Mom_Traegheit_Summe "No";
BA_ "GenSigSendType" SG_ 167 MO_Mom_Soll_gefiltert "Cyclic";
BA_ "GenSigStartValue" SG_ 167 MO_Mom_Soll_gefiltert 1022;
BA_ "GenSigSwitchedByIgnition" SG_ 167 MO_Mom_Soll_gefiltert "No";
BA_ "GenSigSendType" SG_ 167 MO_Mom_Schub "Cyclic";
BA_ "GenSigStartValue" SG_ 167 MO_Mom_Schub 510;
BA_ "GenSigSwitchedByIgnition" SG_ 167 MO_Mom_Schub "No";
BA_ "GenSigSendType" SG_ 167 MO_Status_Normalbetrieb_01 "Cyclic";
BA_ "GenSigSwitchedByIgnition" SG_ 167 MO_Status_Normalbetrieb_01 "No";
BA_ "GenSigSendType" SG_ 167 MO_erste_Ungenauschwelle "Cyclic";
BA_ "GenSigSwitchedByIgnition" SG_ 167 MO_erste_Ungenauschwelle "No";
BA_ "GenSigSendType" SG_ 167 MO_QBit_Motormomente "Cyclic";
BA_ "GenSigStartValue" SG_ 167 MO_QBit_Motormomente 1;
BA_ "GenSigSwitchedByIgnition" SG_ 167 MO_QBit_Motormomente "No";
BA_ "GenSigSendType" SG_ 168 Motor_12_CRC "Cyclic";
BA_ "GenSigFuncType" SG_ 168 Motor_12_CRC "CRC-8";
BA_ "GenSigSwitchedByIgnition" SG_ 168 Motor_12_CRC "No";
BA_ "GenSigSendType" SG_ 168 Motor_12_BZ "Cyclic";
BA_ "GenSigFuncType" SG_ 168 Motor_12_BZ "MsgCounter";
BA_ "GenSigSwitchedByIgnition" SG_ 168 Motor_12_BZ "No";
BA_ "GenSigSendType" SG_ 168 MO_Mom_neg_verfuegbar "Cyclic";
BA_ "GenSigStartValue" SG_ 168 MO_Mom_neg_verfuegbar 510;
BA_ "GenSigSwitchedByIgnition" SG_ 168 MO_Mom_neg_verfuegbar "No";
BA_ "Fehlerwert" SG_ 168 MO_Mom_neg_verfuegbar 511;
BA_ "GenSigSendType" SG_ 168 MO_Mom_Begr_Fahr "Cyclic";
BA_ "GenSigStartValue" SG_ 168 MO_Mom_Begr_Fahr 510;
BA_ "GenSigSwitchedByIgnition" SG_ 168 MO_Mom_Begr_Fahr "No";
BA_ "Fehlerwert" SG_ 168 MO_Mom_Begr_Fahr 511;
BA_ "GenSigSendType" SG_ 168 MO_Mom_Begr_Schalt "Cyclic";
BA_ "GenSigStartValue" SG_ 168 MO_Mom_Begr_Schalt 1022;
BA_ "GenSigSwitchedByIgnition" SG_ 168 MO_Mom_Begr_Schalt "No";
BA_ "GenSigSendType" SG_ 168 MO_Momentenintegral_02 "Cyclic";
BA_ "GenSigSwitchedByIgnition" SG_ 168 MO_Momentenintegral_02 "No";
BA_ "GenSigSendType" SG_ 168 MO_QBit_Drehzahl_01 "Cyclic";
BA_ "GenSigStartValue" SG_ 168 MO_QBit_Drehzahl_01 1;
BA_ "GenSigSwitchedByIgnition" SG_ 168 MO_QBit_Drehzahl_01 "No";
BA_ "GenSigSendType" SG_ 168 MO_Drehzahl_01 "Cyclic";
BA_ "GenSigSwitchedByIgnition" SG_ 168 MO_Drehzahl_01 "No";
BA_ "GenSigSendType" SG_ 958 Motor_14_CRC "Cyclic";
BA_ "GenSigFuncType" SG_ 958 Motor_14_CRC "CRC-8";
BA_ "GenSigSwitchedByIgnition" SG_ 958 Motor_14_CRC "No";
BA_ "GenSigSendType" SG_ 958 Motor_14_BZ "Cyclic";
BA_ "GenSigFuncType" SG_ 958 Motor_14_BZ "MsgCounter";
BA_ "GenSigSwitchedByIgnition" SG_ 958 Motor_14_BZ "No";
BA_ "GenSigSendType" SG_ 958 MO_StartStopp_Status "Cyclic";
BA_ "GenSigSwitchedByIgnition" SG_ 958 MO_StartStopp_Status "No";
BA_ "GenSigSendType" SG_ 958 MO_StartStopp_Wiederstart "OnChange";
BA_ "GenSigSwitchedByIgnition" SG_ 958 MO_StartStopp_Wiederstart "No";
BA_ "GenSigSendType" SG_ 958 MO_StartStopp_Motorstopp "OnChange";
BA_ "GenSigSwitchedByIgnition" SG_ 958 MO_StartStopp_Motorstopp "No";
BA_ "GenSigSendType" SG_ 958 MO_Freig_Reku "Cyclic";
BA_ "GenSigSwitchedByIgnition" SG_ 958 MO_Freig_Reku "No";
BA_ "GenSigSendType" SG_ 958 MO_Kl_75 "OnChange";
BA_ "GenSigSwitchedByIgnition" SG_ 958 MO_Kl_75 "No";
BA_ "GenSigSendType" SG_ 958 MO_Kl_50 "OnChange";
BA_ "GenSigSwitchedByIgnition" SG_ 958 MO_Kl_50 "No";
BA_ "GenSigSendType" SG_ 958 MO_Gangposition "OnChange";
BA_ "GenSigStartValue" SG_ 958 MO_Gangposition 14;
BA_ "GenSigSwitchedByIgnition" SG_ 958 MO_Gangposition "No";
BA_ "Fehlerwert" SG_ 958 MO_Gangposition 15;
BA_ "GenSigSendType" SG_ 958 MO_StartStopp_Fahrerwunsch "Cyclic";
BA_ "GenSigSwitchedByIgnition" SG_ 958 MO_StartStopp_Fahrerwunsch "No";
BA_ "GenSigSendType" SG_ 958 MO_HYB_Fahrbereitschaft "Cyclic";
BA_ "GenSigSwitchedByIgnition" SG_ 958 MO_HYB_Fahrbereitschaft "No";
BA_ "GenSigSendType" SG_ 958 MO_Ext_E_Fahrt_aktiv "OnChange";
BA_ "NWM-WakeupAllowed" SG_ 958 MO_Ext_E_Fahrt_aktiv "Yes";
BA_ "GenSigSwitchedByIgnition" SG_ 958 MO_Ext_E_Fahrt_aktiv "No";
BA_ "GenSigSendType" SG_ 958 MO_Fahrer_bremst "OnChange";
BA_ "GenSigSwitchedByIgnition" SG_ 958 MO_Fahrer_bremst "No";
BA_ "GenSigSendType" SG_ 958 MO_QBit_Fahrer_bremst "OnChange";
BA_ "GenSigStartValue" SG_ 958 MO_QBit_Fahrer_bremst 1;
BA_ "GenSigSwitchedByIgnition" SG_ 958 MO_QBit_Fahrer_bremst "No";
BA_ "GenSigSendType" SG_ 958 MO_BLS "OnChange";
BA_ "GenSigSwitchedByIgnition" SG_ 958 MO_BLS "No";
BA_ "GenSigSendType" SG_ 958 MO_Konsistenz_Bremsped "OnChange";
BA_ "GenSigSwitchedByIgnition" SG_ 958 MO_Konsistenz_Bremsped "No";
BA_ "GenSigSendType" SG_ 958 MO_Timeout_ESP "OnChange";
BA_ "GenSigSwitchedByIgnition" SG_ 958 MO_Timeout_ESP "No";
BA_ "GenSigSendType" SG_ 958 MO_Klima_Eingr "OnChange";
BA_ "GenSigSwitchedByIgnition" SG_ 958 MO_Klima_Eingr "No";
BA_ "GenSigSendType" SG_ 958 MO_Aussp_Anlass "OnChange";
BA_ "GenSigSwitchedByIgnition" SG_ 958 MO_Aussp_Anlass "No";
BA_ "GenSigSendType" SG_ 958 MO_Freig_Anlass "OnChange";
BA_ "GenSigSwitchedByIgnition" SG_ 958 MO_Freig_Anlass "No";
BA_ "GenSigSendType" SG_ 958 MO_Kuppl_schalter "OnChange";
BA_ "GenSigSwitchedByIgnition" SG_ 958 MO_Kuppl_schalter "No";
BA_ "GenSigSendType" SG_ 958 MO_Interlock "OnChange";
BA_ "GenSigSwitchedByIgnition" SG_ 958 MO_Interlock "No";
BA_ "GenSigSendType" SG_ 958 MO_Motor_laeuft "OnChange";
BA_ "GenSigSwitchedByIgnition" SG_ 958 MO_Motor_laeuft "No";
BA_ "GenSigSendType" SG_ 958 MO_Kickdown "OnChange";
BA_ "GenSigSwitchedByIgnition" SG_ 958 MO_Kickdown "No";
BA_ "GenSigSendType" SG_ 958 MO_QBit_KL_75 "OnChange";
BA_ "GenSigStartValue" SG_ 958 MO_QBit_KL_75 1;
BA_ "GenSigSwitchedByIgnition" SG_ 958 MO_QBit_KL_75 "No";
BA_ "GenSigSendType" SG_ 958 MO_EKlKomLeiRed "Cyclic";
BA_ "GenSigSwitchedByIgnition" SG_ 958 MO_EKlKomLeiRed "No";
BA_ "GenSigSendType" SG_ 958 MO_Handshake_STH "Cyclic";
BA_ "GenSigSwitchedByIgnition" SG_ 958 MO_Handshake_STH "No";
BA_ "GenSigSendType" SG_ 958 MO_BKV_Unterdruckwarnung "Cyclic";
BA_ "GenSigSwitchedByIgnition" SG_ 958 MO_BKV_Unterdruckwarnung "No";
BA_ "GenSigSendType" SG_ 958 MO_Freigabe_Segeln "Cyclic";
BA_ "GenSigSwitchedByIgnition" SG_ 958 MO_Freigabe_Segeln "No";
BA_ "GenSigSendType" SG_ 958 MO_PTC_Status "Cyclic";
BA_ "GenSigSwitchedByIgnition" SG_ 958 MO_PTC_Status "No";
BA_ "GenSigSendType" SG_ 958 MO_QBit_Gangposition "OnChange";
BA_ "GenSigStartValue" SG_ 958 MO_QBit_Gangposition 1;
BA_ "GenSigSwitchedByIgnition" SG_ 958 MO_QBit_Gangposition "No";
BA_ "GenSigSendType" SG_ 958 MO_Signalquelle_Gangposition "Cyclic";
BA_ "GenSigSwitchedByIgnition" SG_ 958 MO_Signalquelle_Gangposition "No";
BA_ "GenSigSendType" SG_ 958 MO_Remotestart_Betrieb "OnChange";
BA_ "GenSigSwitchedByIgnition" SG_ 958 MO_Remotestart_Betrieb "No";
BA_ "GenSigSendType" SG_ 958 MO_Remotestart_moeglich "Cyclic";
BA_ "GenSigSwitchedByIgnition" SG_ 958 MO_Remotestart_moeglich "No";
BA_ "GenSigSendType" SG_ 958 MO_FMAus_aktiv "OnChange";
BA_ "GenSigSwitchedByIgnition" SG_ 958 MO_FMAus_aktiv "No";
BA_ "GenSigSendType" SG_ 958 MO_FMAus_Startvariante "OnChange";
BA_ "GenSigSwitchedByIgnition" SG_ 958 MO_FMAus_Startvariante "No";
BA_ "GenSigSendType" SG_ 958 MO_BMS_NV_Anf_stuetzen "OnChange";
BA_ "GenSigSwitchedByIgnition" SG_ 958 MO_BMS_NV_Anf_stuetzen "No";
BA_ "GenSigSendType" SG_ 958 MO_Zylinderabschaltung "OnChange";
BA_ "GenSigSwitchedByIgnition" SG_ 958 MO_Zylinderabschaltung "No";
BA_ "GenSigSendType" SG_ 958 MO_HYB_VM_aktiv "OnChange";
BA_ "GenSigSwitchedByIgnition" SG_ 958 MO_HYB_VM_aktiv "No";
BA_ "GenSigSendType" SG_ 958 MO_StartVorauss_erfuellt "OnChange";
BA_ "GenSigStartValue" SG_ 958 MO_StartVorauss_erfuellt 1;
BA_ "GenSigSwitchedByIgnition" SG_ 958 MO_StartVorauss_erfuellt "No";
BA_ "GenSigSendType" SG_ 1631 TSK_Grundmasse "Cyclic";
BA_ "GenSigSwitchedByIgnition" SG_ 1631 TSK_Grundmasse "No";
BA_ "GenSigSendType" SG_ 1631 TSK_QBit_Steigung "Cyclic";
BA_ "GenSigStartValue" SG_ 1631 TSK_QBit_Steigung 1;
BA_ "GenSigSwitchedByIgnition" SG_ 1631 TSK_QBit_Steigung "No";
BA_ "GenSigSendType" SG_ 1631 TSK_QBit_Fahrzeugmasse "Cyclic";
BA_ "GenSigStartValue" SG_ 1631 TSK_QBit_Fahrzeugmasse 1;
BA_ "GenSigSwitchedByIgnition" SG_ 1631 TSK_QBit_Fahrzeugmasse "No";
BA_ "GenSigSendType" SG_ 1631 MO_SpannungsAnf_02 "Cyclic";
BA_ "GenSigSwitchedByIgnition" SG_ 1631 MO_SpannungsAnf_02 "No";
BA_ "GenSigSendType" SG_ 1631 MO_DPF_reg "Cyclic";
BA_ "GenSigSwitchedByIgnition" SG_ 1631 MO_DPF_reg "No";
BA_ "GenSigSendType" SG_ 1631 MO_Heizstrom_EKAT "Cyclic";
BA_ "GenSigSwitchedByIgnition" SG_ 1631 MO_Heizstrom_EKAT "No";
BA_ "Fehlerwert" SG_ 1631 MO_Heizstrom_EKAT 127;
BA_ "GenSigSendType" SG_ 1631 MO_Heizstrom_SCR "Cyclic";
BA_ "GenSigSwitchedByIgnition" SG_ 1631 MO_Heizstrom_SCR "No";
BA_ "Fehlerwert" SG_ 1631 MO_Heizstrom_SCR 63;
BA_ "GenSigSendType" SG_ 1631 MO_P_Generator_ungefiltert_Anf "Cyclic";
BA_ "GenSigSwitchedByIgnition" SG_ 1631 MO_P_Generator_ungefiltert_Anf "No";
BA_ "GenSigSendType" SG_ 1631 TSK_Getriebeinfo "Cyclic";
BA_ "GenSigSwitchedByIgnition" SG_ 1631 TSK_Getriebeinfo "No";
BA_ "GenSigSendType" SG_ 1631 MO_Energieinhalt_BMS "Cyclic";
BA_ "GenSigStartValue" SG_ 1631 MO_Energieinhalt_BMS 4094;
BA_ "GenSigSwitchedByIgnition" SG_ 1631 MO_Energieinhalt_BMS "No";
BA_ "Fehlerwert" SG_ 1631 MO_Energieinhalt_BMS 4095;
BA_ "GenSigSendType" SG_ 1631 TSK_Fahrzeugmasse_02 "Cyclic";
BA_ "GenSigSwitchedByIgnition" SG_ 1631 TSK_Fahrzeugmasse_02 "No";
BA_ "Fehlerwert" SG_ 1631 TSK_Fahrzeugmasse_02 255;
BA_ "GenSigSendType" SG_ 1631 TSK_Steigung_02 "Cyclic";
BA_ "GenSigSwitchedByIgnition" SG_ 1631 TSK_Steigung_02 "No";
BA_ "Fehlerwert" SG_ 1631 TSK_Steigung_02 255;
VAL_ 2527679583 Parken_Seitenspiegel_Anf 0 "Keine_Anforderung" 1 "Seitenspiegel_anklappen" 2 "Seitenspiegel_abklappen";
VAL_ 2527679583 Parken_ZV_Schliessen 0 "Keine_Anforderung" 1 "ZV_verriegeln" 2 "ZV_safen";
VAL_ 2527679583 Parken_aktives_System_02 0 "Init" 1 "Keine_Aktivitaet" 2 "RPA" 3 "IPA" 4 "MA" 5 "TP" 6 "rTP" 7 "AAA" 8 "rAAA" 9 "ARA_1" 10 "PLA" 11 "RBF" 12 "PHP";
VAL_ 2527679583 Parken_ZR_Sondermodus_Anf 0 "Init" 1 "Keine_Anforderung" 2 "Anforderung_Sondermodus";
VAL_ 2527679583 Parken_Schluesselsuche_Anf 0 "keine_Anforderung" 1 "Anforderung_Schluesselsuche";
VAL_ 2527679583 Parken_FFB_LED_Anf 0 "keine_Anforderung" 1 "Abbruch_Fehler" 2 "Bereit_OK" 3 "Beendet";
VAL_ 2527679583 Parken_Wegfahrsperren_Anf 0 "keine_Anforderung" 1 "Anforderung_Fahreruebernahme" 2 "Anforderung_Fahreruebergabe";
VAL_ 2527679583 Parken_Aktivierungslicht_Anf 0 "keine_Anforderung" 1 "Aktivierungslicht";
VAL_ 2527679583 Parken_Fahrtrichtungslicht_Anf 0 "keine_Anforderung" 1 "Vorwaerts" 2 "Rueckwaerts";
VAL_ 2527679583 Parken_Lichtnachlauf_Anf 0 "keine_Anforderung" 1 "Anforderung_Lichtnachlauf";
VAL_ 2527679583 Parken_Fahrerhinweise_Anf 0 "keine_Anforderung" 1 "Fahrerhinweise_anzeigen";
VAL_ 2527679583 Parken_Bestaetigungsblinken_Anf 0 "keine_Anforderung" 1 "Erfolgsblinken_Einparken" 2 "Abbruchsblinken" 3 "Erfolgsblinken_Ausparken";
VAL_ 2527679583 Parken_Fahrbereitschaftlicht_Anf 0 "keine_Anforderung" 1 "Fahrbereitschaftslicht";
VAL_ 2527679583 Parken_Lichtsteuerung_Anf 0 "keine_Anforderung" 1 "Automatik_Lichtmodus_aktivieren";
VAL_ 2527679583 IPA_Anf_Meldungen 136 "Disclaimer_Bremse_loesen" 8 "Fahrinf_PaLueSu_aufschalten" 128 "Disclaimer_LP_rechts" 0 "keine Meldung" 129 "Disclaimer_LP_links" 1 "beendet" 130 "Disclaimer_RQ_rechts" 2 "Fahrinf_Bremse_FT_betaetigen" 131 "Disclaimer_RQ_links" 3 "Suche_fortsetzen_ESC_Eingriff" 132 "Disclaimer_VQ_rechts" 4 "n_a_temp_ESC_deaktiviert" 133 "Disclaimer_VQ_links" 5 "n_a_temp_Anhaengerbetrieb" 134 "Disclaimer_AP_rechts" 6 "Suche_Zeitlimit_ueberschritten" 137 "Abbruch_Lenkeingriff_Fahrer" 9 "Stby_Bremse_u_FT_druecken" 138 "Abbruch_Anhaenger_erkannt" 10 "PosOK_Stillstandszeit" 139 "Abbruch_max_Rangierzuege" 11 "Stby_FT_druecken" 140 "Abbruch_Zeitlimit_ueberschritten" 12 "AP_nicht_moeglich" 141 "Beendet_Bitte_uebernehmen" 13 "Fahrinf_Bremse_loesen_Umfeld" 142 "Beendet" 14 "n_a_temp_Tuer_Heckklappe_offen" 15 "Stby_Tuer_Heckklappe_schliessen" 16 "PP_aktiv_nur_aussen_bedienbar" 17 "PP_Fzg_verlassen" 18 "n_a_Offroad_Modus" 19 "PP_Schluessel_oder_App_bedienen" 20 "PP_App_bedienen" 21 "PP_Schluessel_bedienen" 22 "n_a_temp" 23 "Systemstoerung_Service" 24 "n_a_temp_Sensorsicht" 25 "n_a_temp_Spiegel_ausklappen" 26 "GP_Stoerung_Service" 27 "n_a_temp_FAS_aktiv" 28 "PP_BT_unterbrochen" 29 "Hindernis_in_Fahrtrichtung" 30 "Ausparken_Fahrtrichtung_vorgeben" 32 "Suche_Rangierflaeche_zu_klein" 33 "n_a_temp_Drive_Select" 34 "Fahrinf_Bremse_loesen" 35 "Fahrinf_Fahrtrichtungswechsel" 36 "Fahrinf_Bremse_FT_RT_betaetigen" 37 "GP_Fzgposition_vor_Garage" 38 "GP_RT_Garage_oeffnen" 39 "GP_Kein_Zuparken" 40 "Suche_Fahrinfo_beachten" 41 "GP_Fzgposition_freie_Parkflaeche" 42 "GP_n_a_temp_Laser" 43 "Geschwindigkeitsueberschreitung" 44 "Fahrinf_Weiter_vorfahren" 45 "Fahrinf_Bremsbetaetigug" 46 "Fahrinf_Anhalten" 47 "GP_AP_nicht_moeglich_Fahrweg" 48 "PP_Gang_Schluesselauthentifizier" 49 "Fahrhinweis_FT_betaetigen" 50 "PP_aktiv_Hinweis_FUEN" 135 "Disclaimer_AP_links" 143 "Abbruch_Fahrpedaleingriff" 144 "Abbruch_ESC_Eingriff" 145 "Stby_Verkehr_erkannt" 146 "Abbruch_Spiegel_ausklappen" 147 "Abbruch_Waehlhebeleingriff" 148 "Abbruch_AP_Luecke_zu_klein" 149 "Abbruch_Rangierflaeche_zu_klein" 150 "Abbruch_Sensorsicht" 151 "Beendet_Stoerung_Fzgverbindung" 152 "Beendet_selbst_bremsen" 153 "Abbruch_Hindernis_erkannt" 154 "Abbruch_bitte_uebernehmen" 155 "Beendet_Fortsetzung_moeglich" 156 "Stby_Hindernis_erkannt" 157 "FUEN_moeglich" 158 "Abbruch_FUEN_Motor_abgestellt" 159 "Abbruch_Drive_Select" 160 "Abbruch_AP_Seite_versperrt" 161 "PP_Fehler_Schluesselautorisier" 162 "PP_Hinweis_ZV" 163 "PP_Hinweis_Motorabschaltung" 164 "Stby_FT_oder_RT_betaetigen" 165 "Stby_Hindernis_Richtungswechsel" 166 "Stby_erhoehter_Fahrwiderstand" 167 "Abbruch_EPB_aktiviert" 168 "Abbruch_MO_nicht_bereit" 169 "Abbruch_Stoerung_Service" 170 "Abbruch_Gurtschloss_gesteckt" 171 "PP_Abbruch_Rangierbereich" 172 "PP_Abbruch_Verdeckaktivierung" 173 "Abbruch_Bremseingriff_FAS_System" 174 "PP_eingeschraenkt_verfuegbar" 175 "Abbruch" 176 "PosOK_Lenkrad_loslassen_Bremse" 177 "PosOK_Lenkrad_loslassen_FT" 178 "Wiederaufnahme_FT_betaetigen" 179 "PP_beendet_FUEN_moeglich" 180 "Lenkeingriff_beendet" 181 "PP_Abbruch_Zeitlimit" 192 "TPA_aborted_deviated_from_trajec" 193 "TPA_aborted_limited_visibility" 194 "TPA_aborted_localization_failure" 195 "TPA_aborted_System_error" 196 "TPA_aborted_TPA_canceled" 197 "TPA_DNH_Platzhalter" 198 "TPA_DNH_Platzhalter" 199 "TPA_DNH_Platzhalter" 200 "TPA_DNH_Platzhalter" 201 "TPA_DNH_Platzhalter" 202 "TPA_DNH_Platzhalter" 203 "TPA_DNH_Platzhalter" 204 "TPA_DNH_Platzhalter" 205 "TPA_DNH_Platzhalter" 206 "TPA_DNH_Platzhalter" 207 "TPA_DNH_Platzhalter";
VAL_ 2527679684 Kamera_ASM_Ereignis 0 "No_Event" 255 "ASM_Trigger";
VAL_ 2527679684 Kamera_ASM_Zeitstempel 255 "Init";
VAL_ 960 RSt_Fahrerhinweise 0 "Init" 1 "Fahreruebernahme_Hinweis_ZAT_Automat_ohne_Gong" 2 "Fahreruebernahme_Hinweis_ZAT_Automat_mit_Gong" 3 "Fahreruebernahme_Hinweis_ZAT_Handschalter_ohne_Gong" 4 "Fahreruebernahme_Hinweis_ZAT_Handschalter_mit_Gong" 5 "Fahreruebernahme_Hinweis_ZAS_Automat_ohne_Gong" 6 "Fahreruebernahme_Hinweis_ZAS_Automat_mit_Gong" 7 "Fahreruebernahme_Hinweis_ZAS_Handschalter_ohne_Gong" 8 "Fahreruebernahme_Hinweis_ZAS_Handschalter_mit_Gong" 9 "RemoteStart_aktiv_ohne_Gong" 10 "RemoteStart_aktiv_mit_Gong" 11 "void" 12 "void" 13 "void" 14 "void" 15 "void";
VAL_ 960 ZAS_Kl_S 0 "aus" 1 "S_Kontakt_ein";
VAL_ 960 ZAS_Kl_15 0 "aus" 1 "ein";
VAL_ 960 ZAS_Kl_X 0 "aus" 1 "ein";
VAL_ 960 ZAS_Kl_50_Startanforderung 0 "aus" 1 "KL50_ein_Startwunsch_Fahrer";
VAL_ 960 BCM_Remotestart_Betrieb 0 "kein_RS_Betrieb" 1 "RS_Betrieb";
VAL_ 960 ZAS_Kl_Infotainment 0 "inaktiv" 1 "aktiv";
VAL_ 960 BCM_Remotestart_KL15_Anf 0 "inaktiv" 1 "aktiv";
VAL_ 960 BCM_Remotestart_MO_Start 0 "nicht_angefordert" 1 "angefordert";
VAL_ 960 KST_Warn_P1_ZST_def 0 "nicht_defekt" 1 "defekt";
VAL_ 960 KST_Warn_P2_ZST_def 0 "nicht_defekt" 1 "defekt";
VAL_ 960 KST_Fahrerhinweis_1 0 "inaktiv" 1 "aktiv";
VAL_ 960 KST_Fahrerhinweis_2 0 "inaktiv" 1 "aktiv";
VAL_ 960 BCM_Ausparken_Betrieb 0 "kein_Betrieb" 1 "Ausparkvorgang_aktiv";
VAL_ 960 KST_Fahrerhinweis_4 0 "inaktiv" 1 "aktiv";
VAL_ 960 KST_Fahrerhinweis_5 0 "inaktiv" 1 "aktiv";
VAL_ 960 KST_Fahrerhinweis_6 0 "inaktiv" 1 "aktiv";
VAL_ 2463978753 KST_WFS_Fahrfreigabe_Anforderung 0 "Keine" 1 "Uneingeschraenkt" 2 "Eingeschraenkt";
VAL_ 2463978753 KST_Sonderzustand_Status 0 "Init" 1 "Uebergang_neue_Anforderung" 2 "Aktiv" 3 "Fehler";
VAL_ 2463978753 KST_Sonderzustand_Anforderung 0 "Init" 1 "RemoteStart" 2 "RemoteParkAssist" 3 "IntelligentParkAssist" 4 "TrainiertesParken" 5 "OnlineRemoteUpdate" 6 "Einfrierschutz" 7 "Klemme15ViaDiagnose" 8 "RueckwandklappenSicherungPDC" 9 "ParkHausPilot" 31 "Fehler";
VAL_ 1420 KST_Anf_Klemme_15 0 "nicht_angefordert" 1 "angefordert";
VAL_ 1420 KST_Anf_Klemme_50 0 "nicht_angefordert" 1 "angefordert";
VAL_ 1420 KST_Anf_Klemme_S 0 "nicht_angefordert" 1 "angefordert";
VAL_ 1420 KST_Txt_Werkstatt 0 "Aus" 1 "Ein";
VAL_ 1420 KST_Txt_P_Gang 0 "Aus" 1 "Ein";
VAL_ 1420 KST_Txt_Panikabschaltung 0 "Aus" 1 "Ein";
VAL_ 1420 KST_Anf_Klemmenfreigabe_ELV 0 "nicht_angefordert" 1 "angefordert";
VAL_ 1420 KST_Txt_Komfortabschaltung 0 "inaktiv" 1 "aktiv";
VAL_ 1420 KST_Unterdr_Zuendungsmeldung 0 "keine_Unterdr_der_Zuendungsmeldung" 1 "Unterdr_der_Zuendungsmeldung_aktiv";
VAL_ 1420 KST_aut_Abschaltung_Zuendung 0 "Zuendung_wird_bei_Verl_nicht_deaktiviert" 1 "Zuendung_wird_bei_Verl_deaktiviert";
VAL_ 1420 KST_Anf_Klemmenfreigabe_WFS 0 "nicht_angefordert" 1 "angefordert";
VAL_ 1420 KST_Anf_ZV_Verriegelung 0 "inaktiv" 1 "aktiv";
VAL_ 1420 Relais_VoKo_angesteuert 0 "nicht_angesteuert" 1 "angesteuert";
VAL_ 1420 RSt_Anforderung_HMS 0 "keine_Anforderung" 1 "halten" 2 "parken" 3 "halten_Standby" 4 "anfahren" 5 "Loesen_ueber_Rampe" 6 "Parken_mit_P";
VAL_ 1420 KST_Zuendungswarnung 0 "keine_Ausgabe_Zuendungswarnung" 1 "Ausg_Zuendungswarnung_Stillstand" 2 "Ausg_Zuendungswarnung_Fahrt" 3 "reserved";
VAL_ 1420 KST_Fahrer_Info_Text 0 "nicht_Aktiv" 1 "Fahrerhinweis_1" 2 "Fahrerhinweis_2";
VAL_ 949 KL_Drehz_Anh 0 "keine_Anhebung" 1 "Drehzahlanhebung_vom_Motor_angefordert";
VAL_ 949 KL_Vorwarn_Komp_ein 0 "Init" 1 "Vorwarnung_Kompressor_ein";
VAL_ 949 KL_AC_Schalter 0 "aus" 1 "ein";
VAL_ 949 KL_Komp_Moment_alt 1 "veraltet_bzw_Ermittlung_des_Moments_nicht_moeglich__zB_keine_Drehzahl_kein_Kaeltemitteldruck";
VAL_ 949 KL_Vorwarn_Zuheizer_ein 0 "keine_Vorwarnung" 1 "Vorwarnung_Zuheizer_ein";
VAL_ 949 KL_Zustand 0 "Aus" 1 "Ein";
VAL_ 949 KL_Kompressorkupplung_linear 253 "volle_Ansteuerung" 254 "Init__nicht_bedient";
VAL_ 949 KL_Charisma_FahrPr 0 "keine_Funktion" 1 "Programm_1" 2 "Programm_2" 3 "Programm_3" 4 "Programm_4" 5 "Programm_5" 6 "Programm_6" 7 "Programm_7" 8 "Programm_8" 9 "Programm_9" 10 "Programm_10" 11 "Programm_11" 12 "Programm_12" 13 "Programm_13" 14 "Programm_14" 15 "Programm_15";
VAL_ 949 KL_Charisma_Status 0 "Init" 1 "verfuegbar" 2 "nicht_verfuegbar" 3 "asynchron_durch_Fahrerwunsch";
VAL_ 949 KL_nachtr_Stopp_Anf 0 "nicht_angefordert" 1 "angefordert";
VAL_ 949 KL_T_Charge 0 "Taster_nicht_betaetigt" 1 "Taster_betaetigt";
VAL_ 949 KL_Last_Kompr 255 "Fehler";
VAL_ 949 KL_Spannungs_Anf 0 "keine_Anforderung" 1 "Anforderung_Stufe_1" 2 "Anforderung_Stufe_2" 3 "Anforderung_Stufe_3";
VAL_ 949 KL_Thermomanagement 0 "keine_Freigabe_TMM__max_Heizbedarf" 1 "kleine_Freigabe_TMM" 2 "mittlere_Freigabe_TMM" 3 "volle_Freigabe_TMM__kein_Heizbedarf";
VAL_ 949 KL_StartStopp_Info 0 "Motorlauf_nicht_notwendig_(Stoppfreigabe)" 1 "Motoranlauf_nicht_zwingend_notwendig_(Stoppverbot,keine_Startanforderung)" 2 "Motoranlauf_zwingend_notwendig_(Startanforderung)" 3 "Systemfehler";
VAL_ 949 KL_Freilauf_Info 0 "Freilauf_freigegeben" 1 "Uebergang_in_Freilauf_unzulaessig" 2 "Freilauf_nicht_freigegeben_Abbruch" 3 "Freilauf_Anforderung";
VAL_ 949 KL_Anf_KL 255 "Fehler";
VAL_ 949 KL_el_Zuheizer_Stufe 0 "Aus" 1 "Stufe_1" 2 "Stufe_2" 3 "Stufe_3";
VAL_ 949 KL_Ausstattung_Klima 0 "Heizung_elektrisch" 1 "Klimamanuell_elektrisch" 2 "Climatic__1_Zone" 3 "Climatronic__1_Zone" 4 "Climatronic__2_Zonen" 5 "Climatronic__3_Zonen" 6 "Climatronic__4_Zonen" 7 "reserviert";
VAL_ 949 KL_Variante_Standheizung 0 "Wasserstandheizung_60_min_Laufzeit" 1 "Luftstandheizung_120_min_Laufzeit" 2 "Wasserstandheizung_120_min_Laufzeit" 3 "Wasser_und_Luftstandheizung_120_min_Laufzeit";
VAL_ 949 KL_Anf_KV 126 "Init";
VAL_ 1511 KL_HV_Heizer_Strom 255 "Init";
VAL_ 1511 KL_EKK_Strom 255 "Init";
VAL_ 1511 KL_Pumpe_02_Soll 126 "Init" 127 "Fehler";
VAL_ 1511 KL_Ventil_03_Soll 0 "nicht_ansteuern" 1 "Ventil_ansteuern";
VAL_ 1511 KL_Ventil_10_Status 0 "Ventil_nicht_angesteuert" 1 "Ventil_angesteuert" 2 "reserviert" 3 "reserviert" 4 "reserviert" 5 "Ventil_nicht_verbaut" 6 "Init" 7 "Fehler";
VAL_ 1511 KL_Senderkennung 0 "Sender Climatronic SG" 1 "Sender Waermepumpen SG";
VAL_ 1511 WP_KJ_Soll 0 "Init_Keine_Anforderung" 1 "KJ_oeffnen" 2 "KJ_schliessen" 3 "Fehler";
VAL_ 1511 KL_Fehler_HV_EKK 0 "Init" 1 "Kein HV Fehler am EKK erkannt" 2 "HV Fehler am EKK erkannt" 3 "Fehler";
VAL_ 1511 KL_Fehler_HV_Heizer 0 "Init" 1 "Kein HV Fehler am HV Heizer erkannt" 2 "HV Fehler am HV Heizer erkannt" 3 "Fehler";
VAL_ 1511 KL_BattKond_WaPu_DZMax 62 "Init" 63 "Fehler";
VAL_ 1511 WP_Kuehlerluefter_Anf 255 "Fehler";
VAL_ 1511 KL_KM_ASV_01_Status 0 "Ventil nicht geschaltet" 1 "Ventil geschaltet" 2 "Ventil nicht verbaut" 3 "Fehler";
VAL_ 1511 KL_KM_ASV_02_Status 0 "Ventil nicht geschaltet" 1 "Ventil geschaltet" 2 "Ventil nicht verbaut" 3 "Fehler";
VAL_ 1511 KL_Vorwarn_HVHeizer_Leistung 0 "Init_Aus" 1 "500W" 2 "1000W" 3 "1500W" 4 "2000W" 5 "2500W" 6 "3000W" 7 "3500W" 8 "4000W" 9 "4500W" 10 "5000W" 11 "5500W" 12 "6000W" 13 "6500W" 14 "7000W" 15 "Fehler";
VAL_ 1511 KL_Status_EoHVL_EKK 0 "Init" 1 "Keine_offene_HV_Leitung_erkannt" 2 "offene_HV_Leitung_erkannt" 3 "Fehler";
VAL_ 1511 KL_Status_EoHVL_Heizer 0 "Init" 1 "Keine_offene_HV_Leitung_erkannt" 2 "offene_HV_Leitung_erkannt" 3 "Fehler";
VAL_ 1505 BCM1_Aussen_Temp_ungef 253 "nicht_verbaut" 254 "Initwert" 255 "Fehler";
VAL_ 1505 BCM_Heizungsabsperrventil_Status 0 "HAV_offen" 1 "HAV_geschlossen" 2 "Init_oder_nicht_verbaut" 3 "Fehler";
VAL_ 1505 BCM_Heizungspumpe_Status 0 "Pumpe_aus" 1 "Pumpe_aktiv_und_Stauts_iO" 2 "Init_oder_nicht_verbaut" 3 "Fehler";
VAL_ 1505 BCM_Kompressorkupplung_Status 0 "Kupplung_offen" 1 "Kupplung_geschlossen" 2 "Init_oder_nicht_verbaut" 3 "Fehler";
VAL_ 1505 BCM1_PTC_stufig_Status 0 "Aus" 1 "Stufe_1_aktiv" 2 "Stufe_2_aktiv" 3 "Stufe_3_aktiv" 6 "Init_oder_nicht_verbaut" 7 "Fehler";
VAL_ 1505 BCM1_FStatus_Aussentemp_ungef 0 "iO" 1 "niO";
VAL_ 1505 BCM1_Kompressorstrom_ist 254 "Init, bzw. nicht verfuegbar" 255 "Fehler";
VAL_ 1505 BCM1_OBD_FStatus_ATemp 0 "kein Fehler / Init / nicht verbaut" 1 "KS- (Kurzschluss nach minus)" 2 "KS+ (Kurzschluss nach plus)" 3 "OC (Leitungsunterbrechung)" 4 "OOR+ (Signal zu gross)" 5 "OOR- (Signal zu klein)" 6 "RC+ (Signal unplausibel zu gross)" 7 "RC- (Signal unplausibel zu klein)" 8 "KS+/OC (Kurzschluss nach plus/Unterbrechung)" 9 "KS-/OC  (Kurzschluss nach minus/Unterbrechung)" 10 "KS-/KS+  (Kurzschluss nach minus/plus)" 11 "KS-/KS+/OC (Kurzschluss nach minus/plus/Unterbrechung)" 12 "frei" 13 "frei" 14 "frei" 15 "frei";
VAL_ 2549088277 Airbag_01_KompSchutz 0 "inaktiv" 1 "aktiv";
VAL_ 2549088277 Airbag_01_Abschaltstufe 0 "keine_Einschraenkung" 1 "Funktionseinschraenkung";
VAL_ 2549088277 Airbag_01_Transport_Mode 0 "keine_Einschraenkung" 1 "Funktionseinschraenkung";
VAL_ 2549088277 Airbag_01_Nachlauftyp 0 "Komm_bei_KL15_EIN" 1 "Komm_nach_KL15_AUS" 2 "Komm_bei_KL15_AUS";
VAL_ 2549088277 NM_Airbag_01_Wakeup 0 "Peripherie_Wakeup__Ursache_nicht_bekannt" 1 "Bus_Wakeup" 2 "KL15_HW";
VAL_ 2549088277 KN_AB_DiagPfad 0 "aktiv" 1 "inaktiv";
VAL_ 2549088277 AB_KD_Fehler 0 "kein_KD_Fehler" 1 "KD_Fehler";
VAL_ 2549088380 EMotor_KompSchutz 0 "inaktiv" 1 "aktiv";
VAL_ 2549088380 EMotor_01_Abschaltstufe 0 "keine_Einschraenkung" 1 "Funktionseinschraenkung";
VAL_ 2549088380 EMotor_01_Transport_Mode 0 "keine_Einschraenkung" 1 "Funktionseinschraenkung";
VAL_ 2549088380 EMotor_Nachlauftyp 0 "Komm_bei_KL15_EIN" 1 "Komm_nach_KL15_AUS" 2 "Komm_bei_KL15_AUS";
VAL_ 2549088380 NM_EMotor_01_Wakeup 0 "Peripherie_Wakeup__Ursache_nicht_bekannt" 1 "Bus_Wakeup" 2 "KL15_HW";
VAL_ 2549088380 KN_EM_HYB_DiagPfad 0 "aktiv" 1 "inaktiv";
VAL_ 2549088380 EM_HYB_KD_Fehler 0 "kein_KD_Fehler" 1 "KD_Fehler";
VAL_ 2549088272 Gateway_KompSchutz 0 "inaktiv" 1 "aktiv";
VAL_ 2549088272 Gateway_Abschaltstufe 0 "keine_Einschraenkung" 1 "Funktionseinschraenkung";
VAL_ 2549088272 Gateway_Transport_Mode 0 "keine_Einschraenkung" 1 "Funktionseinschraenkung";
VAL_ 2549088272 Gateway_Nachlauftyp 0 "Komm_bei_KL15_EIN" 1 "Komm_nach_KL15_AUS" 2 "Komm_bei_KL15_AUS";
VAL_ 2549088272 NM_Gateway_Wakeup 128 "Energiemanagement" 0 "Peripherie_Wakeup__Ursache_nicht_bekannt" 129 "Funktionswakeup_OBDC" 1 "Bus_Wakeup" 130 "Hochvoltenergiemanagement" 2 "KL15_HW" 131 "CWU_empfangen" 3 "ACAN_Wakeup" 132 "Fuer_Bus_relevanten_FC_empfangen" 4 "FCAN_Wakeup" 133 "OnlineDienst_empfangen" 5 "KCAN_Wakeup" 134 "HV_Aktivieren" 6 "ICAN_Wakeup" 135 "HV_Deaktivieren" 7 "DiagCAN_Wakeup" 136 "VTS_Suche_DriverCard" 8 "ECAN_Wakeup" 137 "VTS_Hupen_Blinken" 9 "Energie_LIN_Wakeup" 138 "Remote_Vehicle_Status" 10 "Bedien_LIN_Wakeup" 139 "Plug_and_Charge" 11 "HybridCAN_Wakeup" 140 "VTS_Wakeup_Infotainment" 12 "Flexray_Wakeup" 141 "CCAN_Wakeup" 13 "MFL_WakeUp" 142 "NFcGW_fordert_OTA_FC_an" 14 "Ethernet" 15 "DCAN_Wakeup" 16 "K2CAN_Wakeup" 32 "FlexRay_Branch1_WakeUp" 33 "FlexRay_Branch2_WakeUp" 34 "FlexRay_Branch3_WakeUp" 35 "FlexRay_Branch4_WakeUp" 36 "FlexRay_Branch5_WakeUp" 37 "FlexRay_Branch6_WakeUp" 38 "FlexRay_Branch7_WakeUp" 39 "FlexRay_Branch8_WakeUp" 40 "FlexRay_Branch9_WakeUp" 41 "FlexRay_Branch10_WakeUp" 42 "FlexRay_Branch11_WakeUp" 43 "FlexRay_Branch12_WakeUp" 44 "FlexRay_Branch13_WakeUp" 45 "FlexRay_Branch14_WakeUp" 46 "FlexRay_Branch15_WakeUp" 47 "FlexRay_Branch16_WakeUp";
VAL_ 2549088272 KN_GW_DiagPfad 0 "aktiv" 1 "inaktiv";
VAL_ 2549088272 GW_KD_Fehler 0 "kein_KD_Fehler" 1 "KD_Fehler";
VAL_ 2549088440 LE2_KompSchutz 0 "inaktiv" 1 "aktiv";
VAL_ 2549088440 LE2_Abschaltstufe 0 "keine_Einschraenkung" 1 "Funktionseinschraenkung";
VAL_ 2549088440 LE2_Transport_Mode 0 "keine_Einschraenkung" 1 "Funktionseinschraenkung";
VAL_ 2549088440 LE2_Nachlauftyp 0 "Komm_bei_KL15_EIN" 1 "Komm_nach_KL15_AUS" 2 "Komm_bei_KL15_AUS";
VAL_ 2549088440 NM_LE2_Wakeup 0 "Peripherie_Wakeup__Ursache_nicht_bekannt" 1 "Bus_Wakeup" 2 "KL15_HW" 3 "KL_30__Reset";
VAL_ 2549088440 KN_LE2_DiagPfad 0 "aktiv" 1 "inaktiv";
VAL_ 2549088440 LE2_KD_Fehler 0 "kein_KD_Fehler" 1 "KD_Fehler";
VAL_ 2549088374 Motor_KompSchutz 0 "inaktiv" 1 "aktiv";
VAL_ 2549088374 MO_01_Abschaltstufe 0 "keine_Einschraenkung" 1 "Funktionseinschraenkung";
VAL_ 2549088374 MO_01_Transport_Mode 0 "keine_Einschraenkung" 1 "Funktionseinschraenkung";
VAL_ 2549088374 Motor_Nachlauftyp 0 "Komm_bei_KL15_EIN" 1 "Komm_nach_KL15_AUS" 2 "Komm_bei_KL15_AUS";
VAL_ 2549088374 KN_Motor_ECUKnockOutTimer 63 "ECUKnockOut_deaktiviert";
VAL_ 2549088374 KN_Motor_BusKnockOut 0 "Funktion_nicht_ausgeloest" 1 "Veto_aktiv" 2 "Funktion_ausgeloest" 3 "Funktion_deaktiviert";
VAL_ 2549088374 KN_Motor_BusKnockOutTimer 255 "BusKnockOut_deaktiviert";
VAL_ 2549088374 NM_MO_01_Wakeup 0 "Peripherie_Wakeup__Ursache_nicht_bekannt" 1 "Bus_Wakeup" 2 "KL15_HW" 3 "Oelstandsmessung" 4 "Evakuierung_SCR_System" 5 "Drucktankbetankung" 6 "KL50_HW" 7 "Fahrstufenwechsel";
VAL_ 2549088374 KN_Motor_ECUKnockOut 0 "Funktion_nicht_ausgeloest" 1 "Veto_war_aktiv" 2 "Funktion_ausgeloest" 3 "Funktion_deaktiviert";
VAL_ 2549088374 KN_MO_DiagPfad 0 "aktiv" 1 "inaktiv";
VAL_ 2549088374 MO_KD_Fehler 0 "kein_KD_Fehler" 1 "KD_Fehler";
VAL_ 982 LH_Aussenlicht_def 0 "OK" 1 "defekt";
VAL_ 982 LH_Standlicht_H_aktiv 1 "Standlicht hinten aktiv";
VAL_ 982 LH_Parklicht_HL_aktiv 0 "nicht aktiv" 1 "Parklicht hinten links aktiv";
VAL_ 982 LH_Parklicht_HR_aktiv 0 "nicht aktiv" 1 "Parklicht hinten rechts aktiv";
VAL_ 982 LH_Bremslicht_H_aktiv 1 "Bremslicht hinten aktiv";
VAL_ 982 LH_Nebelschluss_aktiv 0 "nicht aktiv" 1 "aktiv";
VAL_ 982 LH_Rueckfahrlicht_aktiv 0 "nicht aktiv" 1 "aktiv";
VAL_ 982 LH_Blinker_HL_akt 1 "Blinker hinten links aktiv";
VAL_ 982 LH_Blinker_HR_akt 1 "Blinker hinten rechts aktiv";
VAL_ 982 LH_Blinker_li_def 0 "OK" 1 "Blinker hinten links defekt";
VAL_ 982 LH_Bremsl_li_def 0 "OK" 1 "mindestens ein Bremslicht hinten links defekt";
VAL_ 982 LH_Schlusslicht_li_def 0 "OK" 1 "mindestens ein Schlusslicht hinten links defekt";
VAL_ 982 LH_Rueckf_li_def 0 "OK" 1 "Rückfahrlicht hinten links defekt";
VAL_ 982 LH_Nebel_li_def 0 "OK" 1 " Nebelschlusslicht hinten links defekt";
VAL_ 982 LH_Schluss_Brems_Nebel_li_def 0 "iO" 1 "defekt";
VAL_ 982 LH_Schluss_Brems_Nebel_re_def 0 "iO" 1 "defekt";
VAL_ 982 LH_Zusatzschlussl_def 0 "OK" 1 "mindestens_ein_Zusatzschlusslicht_defekt";
VAL_ 982 LH_Schluss_Brems_li_def 0 "OK" 1 "defekt";
VAL_ 982 LH_Schluss_Nebel_li_def 0 "OK" 1 "defekt";
VAL_ 982 LH_SL_BRL_BLK_li_def 0 "OK" 1 "defekt";
VAL_ 982 LH_Brems_Blk_li_def 0 "OK" 1 "defekt";
VAL_ 982 LH_Diag_Status_re_def 0 "OK" 1 "Aussenlict_Diagnose_Systemstoerung_rechts";
VAL_ 982 LH_Diag_Status_li_def 0 "OK" 1 "Aussenlicht_Diagnose_Systemstoerung_links";
VAL_ 982 LH_Diag_LED_li_def 0 "OK" 1 "Heckleuchte_links_defekt";
VAL_ 982 LH_Diag_LED_re_def 0 "OK" 1 "Heckleuchte_rechts_defekt";
VAL_ 982 LH_Blinker_re_def 0 "OK" 1 "Blinker hinten rechts defekt";
VAL_ 982 LH_Bremsl_re_def 0 "OK" 1 "mindestens ein Bremslicht hinten rechts defekt";
VAL_ 982 LH_Schlusslicht_re_def 0 "OK" 1 "mindestens ein Schlusslicht hinten rechts defekt";
VAL_ 982 LH_Rueckf_re_def 0 "OK" 1 "Rückfahrlicht hinten rechts defekt";
VAL_ 982 LH_Nebel_re_def 0 "OK" 1 "Nebelschlusslicht hinten rechts defekt";
VAL_ 982 LH_Schluss_Brems_mi_def 0 "OK" 1 "Defekt";
VAL_ 982 LH_Schluss_Brems_re_def 0 "OK" 1 "defekt";
VAL_ 982 LH_Schluss_Nebel_re_def 0 "OK" 1 "defekt";
VAL_ 982 LH_SL_BRL_BLK_re_def 0 "OK" 1 "defekt";
VAL_ 982 LH_Brems_Blk_re_def 0 "OK" 1 "defekt";
VAL_ 982 LH_Kennzl_def 0 "OK" 1 "Kennzeichenbeleuchtung hinten defekt";
VAL_ 982 LH_3_Bremsl_def 0 "OK" 1 "hochgesetzte  Bremsleuchte defekt";
VAL_ 982 LH_Nebel_mi_def 0 "OK" 1 " Nebelschlusslicht hinten Mitte defekt";
VAL_ 982 LH_Rueckf_mi_def 0 "OK" 1 "Rückfahllicht Mitte defekt";
VAL_ 982 LH_Schlusslicht_mi_def 0 "OK" 1 "defekt";
VAL_ 982 LH_Bremsl_li_ges_def 0 "OK" 1 "Alle Bremslichter hinten links defekt";
VAL_ 982 LH_Bremsl_re_ges_def 0 "OK" 1 "Alle Bremslichter hinten rechts defekt";
VAL_ 982 LH_Bremsl_mi_def 0 "OK" 1 "defekt";
VAL_ 982 BRL_als_SHL 0 "nicht_aktiv" 1 "aktiv";
VAL_ 134 LWI_Sensorstatus 0 "iO" 1 "nicht kalibriert";
VAL_ 134 LWI_QBit_Sub_Daten 0 "LWS-Subinfo 'real' (Lenkradwinkelinformation ADS-tauglich) " 1 "LWS-Subinfo 'simuliert' (Lenkradwinkelinformation nicht ADS-tauglich )";
VAL_ 134 LWI_QBit_Lenkradwinkel 0 "gültiger Wert" 1 "ausserhalb der Spezifikation";
VAL_ 134 LWI_Lenkradwinkel 8190 "Init" 8191 "Fehler";
VAL_ 134 LWI_VZ_Lenkradwinkel 0 "positiv_links_von_der_Nullstellung" 1 "negativ";
VAL_ 134 LWI_VZ_Lenkradw_Geschw 0 "positiv_links_von_der_Nullstellung" 1 "negativ";
VAL_ 134 LWI_Lenkradw_Geschw 510 "Init" 511 "Fehler";
VAL_ 817 MFL_Lokalaktiv 0 "war_nicht_lokal_aktiv" 1 "war_lokal_aktiv";
VAL_ 817 MFL_M_Taste 0 "nicht_betaetigt" 1 "betaetigt";
VAL_ 817 MFL_Paddle_Verbau 0 "verbaut" 1 "nicht_verbaut";
VAL_ 817 MFL_Tastencode_1 0 "Key_Released__No_Key" 1 "Context_Menu" 2 "Menu_Up__Next_Screen" 3 "Menu_Down__Previous_Screen" 4 "Up" 5 "Down" 6 "Up__Down_ThumbWheel" 7 "OK__ThumbWheel_Button" 8 "Cancel__Escape" 9 "Main_Menu" 10 "Side_Menu_left" 11 "Side_Menu_right" 12 "FAS_Menu" 13 "Left__Right_ThumbWheel" 16 "Volume_Up" 17 "Volume_Down" 18 "Volume_Up__Down_ThumbWheel" 19 "Volume_ThumbWheel_Button" 20 "Audio_Source" 21 "Arrow_A_Up__Right" 22 "Arrow_A_Down__Left" 23 "Arrow_B_Up__Right" 24 "Arrow_B_Down__Left" 25 "PTT__PushToTalk" 26 "PTT_Cancel" 27 "Route_Info" 28 "Hook" 29 "Hang_Up" 30 "Off_Hook" 31 "Light_On__Off" 32 "Mute" 33 "Joker1" 34 "Joker2" 35 "View" 100 "MAP" 36 "Arrow_A_Up__Down_ThumbWheel" 101 "MAP_Boost" 37 "Lenkradheizung" 102 "Turn_signal_left" 38 "Rekuperation" 103 "Turn_signal_right" 39 "Tube_Toggle" 104 "Turn_signal_off" 105 "Flashlight" 106 "Highbeam" 107 "Washer_button" 108 "Wiper_button_left" 109 "Wiper_button_right" 110 "Wiper_button_cancel" 111 "Exhaust_Sound" 240 "Startup_Reset" 112 "Drive_Select_button" 241 "Initialization" 113 "Sport_button" 114 "ESP_Drift_Selection_ThumbWheel" 115 "PTT_special_vehicle" 116 "TravelAssist";
VAL_ 817 MFL_Tastencode_2 0 "Key_Released__No_Key" 1 "Context_Menu" 2 "Menu_Up__Next_Screen" 3 "Menu_Down__Previous_Screen" 4 "Up" 5 "Down" 6 "Up__Down_ThumbWheel" 7 "OK__ThumbWheel_Button" 8 "Cancel__Escape" 9 "Main_Menu" 10 "Side_Menu_left" 11 "Side_Menu_right" 12 "FAS_Menu" 13 "Left__Right_ThumbWheel" 16 "Volume_Up" 17 "Volume_Down" 18 "Volume_Up__Down_ThumbWheel" 19 "Volume_ThumbWheel_Button" 20 "Audio_Source" 21 "Arrow_A_Up__Right" 22 "Arrow_A_Down__Left" 23 "Arrow_B_Up__Right" 24 "Arrow_B_Down__Left" 25 "PTT__PushToTalk" 26 "PTT_Cancel" 27 "Route_Info" 28 "Hook" 29 "Hang_Up" 30 "Off_Hook" 31 "Light_On__Off" 32 "Mute" 33 "Joker1" 34 "Joker2" 35 "View" 100 "MAP" 36 "Arrow_A_Up_Right_Down_Left_ThumbWheel" 101 "MAP_Boost" 37 "Lenkradheizung" 102 "Turn_signal_left" 38 "Rekuperation" 103 "Turn_signal_right" 39 "Tube_Toggle" 104 "Turn_signal_off" 105 "Flashlight" 106 "Highbeam" 107 "Washer_button" 108 "Wiper_button_left" 109 "Wiper_button_right" 110 "Wiper_button_cancel" 111 "Exhaust_Sound" 240 "Startup_Reset" 112 "Drive_Select_button" 241 "Initialization" 113 "Sport_button" 114 "ESP_Drift_Selection_ThumbWheel" 115 "PTT_special_vehicle" 116 "TravelAssist";
VAL_ 817 MFL_Eventcode_1 0 "W_no_event____T_no_event" 1 "W_1_Tick_up__T_pressed_normal" 2 "W_2_Ticks_up__T_touched" 3 "W_3_Ticks_up__T_double_click_nor" 4 "W_4_Ticks_up__T_long_press_nor_1" 5 "W_5_Ticks_up__T_long_press_nor_2" 6 "W_6_Ticks_up__T_long_press_nor_3" 7 "W_7_Ticks_up" 9 "W_7_Ticks_dn__T_pressed_strong" 10 "W_6_Ticks_dn" 11 "W_5_Ticks_dn__T_double_click_str" 12 "W_4_Ticks_dn__T_long_press_str_1" 13 "W_3_Ticks_dn__T_long_press_str_2" 14 "W_2_Ticks_dn__T_long_press_str_3" 15 "W_1_Tick_dn";
VAL_ 817 MFL_Eventcode_2 0 "W_no_event____T_no_event" 1 "W_1_Tick_up__T_pressed_normal" 2 "W_2_Ticks_up__T_touched" 3 "W_3_Ticks_up__T_double_click_nor" 4 "W_4_Ticks_up__T_long_press_nor_1" 5 "W_5_Ticks_up__T_long_press_nor_2" 6 "W_6_Ticks_up__T_long_press_nor_3" 7 "W_7_Ticks_up" 9 "W_7_Ticks_dn__T_pressed_strong" 10 "W_6_Ticks_dn" 11 "W_5_Ticks_dn__T_double_click_str" 12 "W_4_Ticks_dn__T_long_press_str_1" 13 "W_3_Ticks_dn__T_long_press_str_2" 14 "W_2_Ticks_dn__T_long_press_str_3" 15 "W_1_Tick_dn";
VAL_ 817 MFL_Marke 0 "VW" 1 "Audi" 2 "Seat" 3 "Skoda" 4 "VW_Nutzf" 5 "Bugatti" 6 "Lamborghini" 7 "Bentley" 8 "Rolls Royce" 9 "Quattro" 10 "kein_Hersteller_1" 11 "kein_Hersteller_2" 12 "kein_Hersteller_3" 13 "kein_Hersteller_4" 14 "Ford" 15 "Porsche";
VAL_ 817 MFL_Tip_Down 0 "nicht_betaetigt" 1 "betaetigt";
VAL_ 817 MFL_Tip_Up 0 "nicht_betaetigt" 1 "betaetigt";
VAL_ 817 MFL_SatModul_links_Err 0 "kein_Fehler" 1 "Fehler";
VAL_ 817 MFL_SatModul_rechts_Err 0 "kein_Fehler" 1 "Fehler";
VAL_ 817 MFL_LR_HZG_Status 0 "inaktiv" 1 "aktiv";
VAL_ 817 MFL_LR_HZG_Err 0 "normal" 1 "Fehler";
VAL_ 817 MFL_Signalhorn 0 "nicht_betaetigt" 1 "betaetigt";
VAL_ 817 MFL_Signalhorn_Err 0 "normal" 1 "Fehler";
VAL_ 817 MFL_Tip_links_Err 0 "normal" 1 "Fehler";
VAL_ 817 MFL_Tip_rechts_Err 0 "normal" 1 "Fehler";
VAL_ 817 MFL_Taste_links_Err 0 "normal" 1 "Fehler";
VAL_ 817 MFL_Taste_rechts_Err 0 "normal" 1 "Fehler";
VAL_ 817 MFL_ECU_Err 0 "normal" 1 "Fehler";
VAL_ 817 MFL_Response_Err 0 "normal" 1 "Fehler";
VAL_ 15 MO_SOPC 0 "kein_SOPC" 1 "SOPC";
VAL_ 1600 MO_QBit_Ansaugluft_Temp 0 "gueltiger_Wert" 1 "Ersatz_Init_oder_Fehlerwert";
VAL_ 1600 MO_QBit_Oel_Temp 0 "gueltiger_Wert" 1 "Ersatz_Init_oder_Fehlerwert";
VAL_ 1600 MO_QBit_Kuehlmittel_Temp 0 "gueltiger_Wert" 1 "Ersatz_Init_oder_Fehlerwert";
VAL_ 1600 MO_KL15_Abschaltempfehlung 0 "Keine Empfehlung" 1 "Abschaltempfehlung";
VAL_ 1600 MO_HYB_Fehler_HV_Netz 0 "i_O" 1 "kein_generatorischer_Betrieb_moeglich";
VAL_ 1600 MO_aktives_Getriebeheizen 0 "kein_Ventil_ansteuern" 1 "Ventil_muss_angesteuert_werden";
VAL_ 1600 MO_Absperrventil_oeffnen 0 "nicht_verfuegbar" 1 "Ansteuerung_Ventil_zulaessig" 2 "Ventil_oeffnen_oder_geoeffnet" 3 "Ventil_schliessen_oder_geschlossen";
VAL_ 1600 MO_Ansaugluft_Temp 254 "Init" 255 "Fehler";
VAL_ 1600 MO_Oel_Temp 253 "nicht_verbaut" 254 "Init" 255 "Fehler";
VAL_ 1600 MO_Kuehlmittel_Temp 254 "Init" 255 "Fehler";
VAL_ 1600 MO_Hoeheninfo 255 "Fehler";
VAL_ 1600 MO_Kennfeldk 0 "keine Kennfeldkühlung vorhanden" 1 "Kennfeldkühlung vorhanden";
VAL_ 1600 MO_Versionsinfo_02 16 "MQB_mit_neuer_Momentenschnittstelle" 0 "zum_Projektbeginn_aufgeraeumter_CAN" 1 "Motor_03_mit_10ms";
VAL_ 1600 MO_QBit_Hoeheninfo 0 "gueltiger_Wert" 1 "Ersatz_Init_oder_Fehlerwert";
VAL_ 1600 MO_Getriebe_kuehlen 0 "nicht_kuehlen" 1 "kuehlen";
VAL_ 1600 MO_Heizungspumpenansteuerung 13 "Fehler" 14 "Init" 15 "nicht_verbaut";
VAL_ 1600 MO_SpannungsAnf 0 "keine_Anforderung" 1 "Anforderung";
VAL_ 167 MO_Mom_Soll_Roh 1022 "Init";
VAL_ 167 MO_Mom_Ist_Summe 1022 "Init";
VAL_ 167 MO_Mom_Traegheit_Summe 1022 "Init";
VAL_ 167 MO_Mom_Soll_gefiltert 1022 "Init";
VAL_ 167 MO_Mom_Schub 510 "Init";
VAL_ 167 MO_Status_Normalbetrieb_01 0 "kein_Normalbetrieb" 1 "Normalbetrieb_erreicht";
VAL_ 167 MO_erste_Ungenauschwelle 0 "genau" 1 "Momente ungenauer >8%";
VAL_ 167 MO_QBit_Motormomente 0 "gueltiger_Wert" 1 "Ersatz_Init_oder_Fehlerwert";
VAL_ 168 MO_Mom_neg_verfuegbar 510 "Init" 511 "Fehler";
VAL_ 168 MO_Mom_Begr_Fahr 510 "Init" 511 "Fehler";
VAL_ 168 MO_Mom_Begr_Schalt 1022 "Init";
VAL_ 168 MO_QBit_Drehzahl_01 0 "gueltiger_Wert" 1 "Ersatz_Init_oder_Fehlerwert";
VAL_ 958 MO_StartStopp_Status 0 "System_in_diesem_KL15_Zyklus_nicht_verfuegbar" 1 "System_aktiv_keine_Freigabe_durch_StartStop_Koordinator" 2 "System_aktiv_alle_Freigaben_liegen_vor" 3 "System_aktiv_mindestens_eine_Freigabe_fehlt";
VAL_ 958 MO_StartStopp_Wiederstart 0 "Wiederstart_inaktiv" 1 "Wiederstart_aktiv";
VAL_ 958 MO_StartStopp_Motorstopp 0 "Motor_Stop_inaktiv" 1 "Motor_Stop_aktiv";
VAL_ 958 MO_Freig_Reku 0 "Rekuperations-Modus aus" 1 "Empfehlung Spannungsanhebung" 2 "Empfehlung Spannungsabsenkung" 3 "Rekuperationsmodus aktiv, Spannungsvariation nicht notwendig";
VAL_ 958 MO_Kl_75 0 "Aus" 1 "Ein";
VAL_ 958 MO_Kl_50 0 "aus" 1 "KL50_ein_Startausfuehrung_Fahrer";
VAL_ 958 MO_Gangposition 0 "Gang_N" 1 "Gang_1" 2 "Gang_2" 3 "Gang_3" 4 "Gang_4" 5 "Gang_5" 6 "Gang_6" 7 "Gang_7" 8 "Gang_8" 9 "Automat_P" 10 "Automat_Vorwaerts_S" 11 "Automat_Vorwaerts_D/E" 12 "Zwischenstellung" 13 "Gang_R" 14 "Istgang_nicht_definiert" 15 "Fehler";
VAL_ 958 MO_StartStopp_Fahrerwunsch 0 "Init" 1 "Stoppverbot_durch_Fahrer" 2 "Stoppfreigabe_durch_Fahrer" 3 "Stoppanforderung_durch_Fahrer";
VAL_ 958 MO_HYB_Fahrbereitschaft 0 "keine_Fahrbereitschaft" 1 "Fahrbereitschaft";
VAL_ 958 MO_Ext_E_Fahrt_aktiv 0 "Rueckmeldung_E_Taster_aus" 1 "Rueckmeldung_E_Taster_ein";
VAL_ 958 MO_Fahrer_bremst 0 "kein_Bremsen" 1 "Bremse_betaetigt";
VAL_ 958 MO_QBit_Fahrer_bremst 0 "gueltiger_Wert" 1 "Ersatz_Init_oder_Fehlerwert";
VAL_ 958 MO_BLS 0 "kein_Bremsen" 1 "Bremse_betaetigt";
VAL_ 958 MO_Konsistenz_Bremsped 0 "Bremspedalinformation_plausibel" 1 "Bremspedalinformation_unplausibel";
VAL_ 958 MO_Timeout_ESP 0 "Empfang_iO" 1 "Timeout";
VAL_ 958 MO_Klima_Eingr 0 "kein Eingriff" 1 "Klimakompressor ausschalten" 2 "Klimakompressor Leistungsreduzierung" 3 "Klimakompressor aufgrund der Heissleuchtenvorwarnung ausschalten";
VAL_ 958 MO_Aussp_Anlass 0 "Anlasser_darf_angesteuert_werden" 1 "Anlasser_ausspuren__Ansteuerung_nicht_moeglich";
VAL_ 958 MO_Freig_Anlass 0 "Start_nicht_zulaessig" 1 "Startfreigabe";
VAL_ 958 MO_Kuppl_schalter 0 "Schalter_sagt_ausgekuppelt" 1 "Schalter_sagt_eingekuppelt";
VAL_ 958 MO_Interlock 0 "Interlockschalter_nicht_betaetigt" 1 "Interlockschalter_betaetigt";
VAL_ 958 MO_Motor_laeuft 0 "Motor_laeuft_nicht" 1 "Motor_laeuft_autark_und_stabil_und_darf_mechanisch_belastet_werden";
VAL_ 958 MO_Kickdown 0 "kein_Kickdown" 1 "Kickdown";
VAL_ 958 MO_QBit_KL_75 0 "gueltiger_Wert" 1 "Ersatz_Init_oder_Fehlerwert";
VAL_ 958 MO_EKlKomLeiRed 0 "keine_Leistungsbegr" 1 "Leistungsbegr_75" 2 "Leistungsbegr_50" 3 "Leistungsbegr_25";
VAL_ 958 MO_Handshake_STH 0 "keine EKP-Ansteuerung durch STH-Anforderung" 1 "EKP-Ansteuerung durch STH-Anforderung";
VAL_ 958 MO_BKV_Unterdruckwarnung 0 "Unterdruckhaushalt_iO" 1 "Unterdruckhaushalt_niO";
VAL_ 958 MO_Freigabe_Segeln 0 "Segelbetrieb_nicht_freigegeben" 1 "Segelbetrieb_freigegeben";
VAL_ 958 MO_PTC_Status 0 "nicht_unterstuetzt" 1 "Stufe_0" 2 "Stufe_1" 3 "Stufe_2" 4 "Stufe_3" 7 "PTC_am_BCM";
VAL_ 958 MO_QBit_Gangposition 0 "gueltiger_Wert" 1 "Ersatz_Init_oder_Fehlerwert";
VAL_ 958 MO_Signalquelle_Gangposition 0 "Sensorsignal" 1 "Modellsignal";
VAL_ 958 MO_Remotestart_Betrieb 0 "MSG_nicht_bereit_fuer_RS_Betrieb" 1 "MSG_bereit_fuer_oder_im_RS_Betrieb";
VAL_ 958 MO_Remotestart_moeglich 0 "Remotestart_nicht_moeglich" 1 "Remotestart_moeglich";
VAL_ 958 MO_FMAus_aktiv 0 "inaktiv" 1 "Segeln_mit_Motor_aus_aktiv";
VAL_ 958 MO_FMAus_Startvariante 0 "kein_Motorstart" 1 "Motorstart_elektrischer_Starter" 2 "GetriebeAnschleppstart" 3 "GetriebeNotAnschleppstart";
VAL_ 958 MO_BMS_NV_Anf_stuetzen 0 "nicht_notwendig" 1 "notwendig";
VAL_ 958 MO_Zylinderabschaltung 0 "Vollmotorbetrieb_VMB" 1 "Uebergang_HMB_in_VMB" 2 "Uebergang_VMB_in_HMB" 3 "Halbmotorbetrieb_HMB";
VAL_ 958 MO_HYB_VM_aktiv 0 "VM_nicht_aktiv" 1 "VM_aktiv";
VAL_ 958 MO_StartVorauss_erfuellt 0 "Signal_nicht_bedient" 1 "StartVorauss_nicht_ueberpruefbar" 2 "StartVorauss_nicht_erfuellt" 3 "StartVorauss_erfuellt";
VAL_ 1631 TSK_QBit_Steigung 0 "gueltiger_Wert" 1 "Ersatz_Init_oder_Fehlerwert";
VAL_ 1631 TSK_QBit_Fahrzeugmasse 0 "gueltiger_Wert" 1 "Ersatz_Init_oder_Fehlerwert";
VAL_ 1631 MO_SpannungsAnf_02 0 "keine_Anforderung" 1 "Anforderung_Stufe_1" 2 "Anforderung_Stufe_2" 3 "Anforderung_Stufe_3";
VAL_ 1631 MO_DPF_reg 0 "DPF_regeneriert_nicht" 1 "DPF_regeneriert";
VAL_ 1631 MO_Heizstrom_EKAT 127 "Fehler";
VAL_ 1631 MO_Heizstrom_SCR 63 "Fehler";
VAL_ 1631 MO_P_Generator_ungefiltert_Anf 0 "nicht_angefordert" 1 "angefordert";
VAL_ 1631 TSK_Getriebeinfo 0 "Handschalter" 1 "AL_AQ_Getriebe" 2 "DL_DQ_Getriebe" 3 "CVT_Getriebe";
VAL_ 1631 MO_Energieinhalt_BMS 4094 "Init" 4095 "Fehler";
VAL_ 1631 TSK_Fahrzeugmasse_02 255 "Fehler";
VAL_ 1631 TSK_Steigung_02 0 "Init_oder_nicht_verbaut" 255 "Fehler";
